VERSION ""

NS_ :

BS_:

BU_: AGSM BCM BSM CADM DMSM DTCM ECM EVCU2 GNMM HCP IPC RFHM SGW TCM
BO_ 1440 TELEMATIC_FD_13: 32 SGW
 SG_ AUD_LVL : 103|8@0+ (1,0) [0|38] "levels" EVCU2
 SG_ ETM_HUD_Zone1_Expanded : 7|6@0+ (1,0) [0|62] "-" IPC
 SG_ ETM_HUD_Zone2_Expanded : 15|6@0+ (1,0) [0|62] "-" IPC
 SG_ ETM_HUD_Zone3_Expanded : 23|6@0+ (1,0) [0|62] "-" IPC
 SG_ ETM_HUD_Zone4_Expanded : 31|6@0+ (1,0) [0|62] "-" IPC
 SG_ ETM_HUD_Zone5_Expanded : 39|6@0+ (1,0) [0|62] "-" IPC
 SG_ HU_Worksite_Inverter_RadioSwitch : 0|1@0+ (1,0) [0|1] "" BCM

BO_ 1465 TELEMATIC_FD_14: 32 SGW
 SG_ ClusterAudiomode : 127|7@0+ (1,0) [0|126] "-" IPC
 SG_ ETM_HUD_Zone1 : 156|3@0+ (1,0) [0|6] "-" IPC
 SG_ ETM_HUD_Zone2 : 167|3@0+ (1,0) [0|6] "-" IPC
 SG_ ETM_HUD_Zone3 : 164|3@0+ (1,0) [0|6] "-" IPC
 SG_ ETM_HUD_Zone4 : 175|3@0+ (1,0) [0|6] "-" IPC
 SG_ ETM_HUD_Zone5 : 172|3@0+ (1,0) [0|6] "-" IPC
 SG_ PSI_Gr1_RPM_SET : 7|5@0+ (250,500) [2000|8000] "rpm" ECM
 SG_ PSI_Gr2_RPM_SET : 15|5@0+ (250,500) [2000|8000] "rpm" ECM
 SG_ PSI_Gr3_RPM_SET : 23|5@0+ (250,500) [2000|8000] "rpm" ECM
 SG_ PSI_Gr4_RPM_SET : 31|5@0+ (250,500) [2000|8000] "rpm" ECM
 SG_ PSI_Gr5_RPM_SET : 39|5@0+ (250,500) [2000|8000] "rpm" ECM
 SG_ PSI_RPM_Reset : 45|1@0+ (1,0) [0|1] "-" ECM
 SG_ PSI_Rq : 47|2@0+ (1,0) [0|3] "-" ECM
 SG_ RACE_CLDWN_ON_OFF_REQ : 2|1@0+ (1,0) [0|0] "-" ECM
 SG_ Radio_Delete_Request : 183|3@0+ (1,0) [0|6] "" IPC
 SG_ Radio_Profile_Request : 82|3@0+ (1,0) [0|6] "-" IPC
 SG_ TGW_CAMERA_DISP_STAT : 91|4@0+ (1,0) [0|14] "-" BCM

BO_ 1466 TELEMATIC_FD_15: 32 SGW
 SG_ Center_Cluster_Button_function : 23|5@0+ (1,0) [0|30] "-" IPC
 SG_ ChargeNow : 89|1@0+ (1,0) [0|1] "-" EVCU2
 SG_ ETM_HUD_CustomSetting : 4|2@0+ (1,0) [0|3] "-" IPC
 SG_ ETM_HUD_Layout : 7|3@0+ (1,0) [0|6] "-" IPC
 SG_ GPS_Elevation : 151|16@0+ (1,-2000) [0|37000] "Hours" IPC
 SG_ HUtoIPC_NAV_Sts : 2|3@0+ (1,0) [0|6] "-" IPC
 SG_ Left_Cluster_Button_function : 15|5@0+ (1,0) [0|30] "-" IPC
 SG_ Right_Cluster_Button_function : 31|5@0+ (1,0) [0|30] "-" IPC

BO_ 150 TELEMATIC_FD_17: 64 SGW
 SG_ FirstFrame_NavTbT : 0|1@0+ (1,0) [0|1] "" IPC
 SG_ NumMultiMessage_NavTbT : 7|3@0+ (1,0) [0|7] "" IPC
 SG_ Text_Characters_NavTbT : 23|416@0+ (1,0) [0|0] "" IPC
 SG_ Text_Type_NavTbT : 4|4@0+ (1,0) [0|14] "" IPC

BO_ 154 TELEMATIC_FD_18: 64 SGW
 SG_ Text_Characters_Aud_Ph : 23|416@0+ (1,0) [0|0] "" IPC
 SG_ Text_Type_Aud_Ph : 7|8@0+ (1,0) [0|254] "" IPC

BO_ 145 TELEMATIC_FD_19: 64 SGW
 SG_ CRC_TELEMATIC_FD_19 : 447|8@0+ (1,0) [0|255] "" EVCU2
 SG_ MessageCounter_TELEMATIC_FD_19 : 435|4@0+ (1,0) [0|15] "" EVCU2
 SG_ PlugAndChargeReq : 385|1@0+ (1,0) [0|1] "" EVCU2
 SG_ Secure_Idle_Req : 0|1@0+ (1,0) [0|1] "" EVCU2,TCM
 SG_ SignatureLightingEnable_Req : 395|1@0+ (1,0) [0|1] "" IPC

BO_ 1428 TELEMATIC_FD_5: 32 SGW
 SG_ CM_TCH_STAT : 74|3@0+ (1,0) [0|6] "" BCM
 SG_ CM_TCH_X_COORD : 143|16@0+ (1,0) [0|65535] "" BCM
 SG_ CM_TCH_Y_COORD : 159|16@0+ (1,0) [0|65535] "" BCM
 SG_ DIST_TO_TURN : 63|16@0+ (1,0) [0|65534] "" CADM,IPC
 SG_ ESC_Sft_btn_status : 79|3@0+ (1,0) [0|6] "" BCM
 SG_ HU_CMP : 174|4@0+ (1,0) [0|0] "" BCM
 SG_ NAV_ARROW : 55|8@0+ (1,0) [1|255] "Arrow" CADM,IPC
 SG_ NAV_UNITS : 42|3@0+ (1,0) [0|7] "" IPC
 SG_ NAVPrsnt : 43|1@0+ (1,0) [0|1] "" IPC
 SG_ T_BY_T_ON : 32|1@0+ (1,0) [0|1] "" CADM,IPC
 SG_ TURN_COMP : 33|1@0+ (1,0) [0|1] "" CADM,IPC
 SG_ WorksiteINVM_Audible_LFW_Req : 76|1@0+ (1,0) [0|1] "" IPC
 SG_ WorksiteINVM_Visual_LFW_Req : 169|1@0+ (1,0) [0|1] "" IPC

BO_ 956 TELEMATIC_FD_8: 32 SGW
 SG_ Power_Tailgate_Enable_Req : 7|1@0+ (1,0) [0|1] "" IPC
 SG_ Rear_Guidance_Light_Status_Req : 0|1@0+ (1,0) [0|1] "" IPC
 SG_ Rear_Lights_with_Approach_Req : 4|1@0+ (1,0) [0|1] "" IPC

BO_ 1832 TELEMATIC_FD_9: 32 SGW
 SG_ GPS_Lat : 87|32@0+ (0.3017485143,-324000000) [-324000000|324000000] "mas" CADM,IPC
 SG_ GPS_Long : 119|32@0+ (0.3017485143,-648000000) [-648000000|648000000] "mas" CADM,IPC

BO_ 158 TELEMATIC_VEHICLE_SETUP: 48 SGW
 SG_ Act_Lane_Mgt_Req : 4|2@0+ (1,0) [0|2] "-" IPC
 SG_ Act_Lane_Mgt_Strength_Req : 1|2@0+ (1,0) [0|2] "-" IPC
 SG_ Active_Park_Mode_Req : 252|1@0+ (1,0) [0|1] "" IPC
 SG_ Active_Park_Prox_Chime_Req : 251|1@0+ (1,0) [0|1] "" IPC
 SG_ Auto_Fold_Mirr_Req : 255|1@0+ (1,0) [0|1] "-" IPC
 SG_ Auto_Trailer_Light_Check_Req : 286|1@0+ (1,0) [0|1] "-" IPC
 SG_ AutoHighBeamEnable_Req : 92|1@0+ (1,0) [0|1] "-" IPC
 SG_ AutoParkBrake_Req : 103|1@0+ (1,0) [0|1] "" IPC
 SG_ AutoUnlockDoorExit_Req : 162|1@0+ (1,0) [0|1] "-" IPC
 SG_ Backup_Cam_Delay_Req : 173|1@0+ (1,0) [0|1] "-" IPC
 SG_ BSDEnable_Req : 140|2@0+ (1,0) [0|2] "-" IPC
 SG_ Consum_Unit_Req : 238|3@0+ (1,0) [0|7] "" IPC
 SG_ CorneringEnable_Req : 82|1@0+ (1,0) [0|1] "-" IPC
 SG_ CRC_TVS1 : 319|8@0+ (1,0) [0|255] "-" CADM
 SG_ Dist_Unit_Req : 231|1@0+ (1,0) [0|1] "" IPC
 SG_ DRLEnable_Req : 80|1@0+ (1,0) [0|1] "-" IPC
 SG_ Drowsy_Driver_Alert_Req : 5|1@0+ (1,0) [0|1] "-" CADM,IPC
 SG_ DynamicGrid_Req : 100|1@0+ (1,0) [0|1] "" IPC
 SG_ Easy_Exit_D_Req : 174|1@0+ (1,0) [0|1] "-" IPC
 SG_ Eng_Off_Pwr_Delay_Req : 187|2@0+ (1,0) [0|3] "-" IPC
 SG_ EPB_MaintenanceMode_Req : 155|1@0+ (1,0) [0|1] "-" BSM
 SG_ FlashLightWLock_Req : 159|1@0+ (1,0) [0|1] "-" IPC
 SG_ FOA_Alert_Type_Req : 283|2@0+ (1,0) [0|3] "" IPC
 SG_ FSFCWPlusActivationMode_Req : 149|2@0+ (1,0) [0|3] "-" CADM,IPC
 SG_ FSFCWPlusSetting_Req : 143|3@0+ (1,0) [0|7] "-" CADM,IPC
 SG_ Fwrd_Cam_Guidelines_Req : 189|1@0+ (1,0) [0|1] "-" IPC
 SG_ GreetingLightsEnable_Req : 81|1@0+ (1,0) [0|1] "-" IPC
 SG_ HeadlightsOffDelay_Req : 145|2@0+ (1,0) [0|3] "-" IPC
 SG_ HeadLightWipers_Req : 167|1@0+ (1,0) [0|1] "-" IPC
 SG_ Hill_Start_Assist_Req : 184|1@0+ (1,0) [0|1] "-" IPC
 SG_ HourMode_Req : 87|1@0+ (1,0) [0|1] "-" IPC
 SG_ HP_Unit_Req : 245|2@0+ (1,0) [0|3] "" IPC
 SG_ Illuminated_Approach_Req : 197|2@0+ (1,0) [0|3] "-" IPC
 SG_ LanguageSelection_Req : 135|8@0+ (1,0) [0|255] "-" IPC
 SG_ LDW_Intensity_Req : 154|2@0+ (1,0) [0|3] "-" IPC
 SG_ LDW_Sensibility_Req : 147|2@0+ (1,0) [0|3] "-" IPC
 SG_ MessageCounter_TVS1 : 307|4@0+ (1,0) [0|15] "-" CADM
 SG_ NavigationRepetition_Req : 105|1@0+ (1,0) [0|1] "" IPC
 SG_ New_Spd_Zone_Ind_Req : 227|2@0+ (1,0) [0|3] "" IPC
 SG_ Paddle_Shifter_Req : 188|1@0+ (1,0) [0|1] "-" IPC
 SG_ PamChimeVolumeFront_Req : 107|2@0+ (1,0) [0|3] "" IPC
 SG_ PamChimeVolumeRear_Req : 111|2@0+ (1,0) [0|3] "" IPC
 SG_ PassiveEntry_Req : 101|1@0+ (1,0) [0|1] "" IPC
 SG_ Ped_EM_Brk_Warn_Act_Req : 175|1@0+ (1,0) [0|1] "-" CADM,IPC
 SG_ PhoneRepetition_Req : 114|1@0+ (1,0) [0|1] "" IPC
 SG_ PLGAlert_Req : 168|1@0+ (1,0) [0|1] "-" IPC
 SG_ Power_Side_Step_Req : 2|1@0+ (1,0) [0|1] "-" IPC
 SG_ Proximity_WU_Req : 6|1@0+ (1,0) [0|1] "-" IPC
 SG_ PwrLevReq : 10|3@0+ (1,0) [0|7] "" IPC
 SG_ RainSensorLevel_Req : 93|1@0+ (1,0) [0|1] "-" IPC
 SG_ Rdy_To_Drive_Req : 223|1@0+ (1,0) [0|1] "" IPC
 SG_ Rear_Brk_Asst_Req : 190|1@0+ (1,0) [0|1] "" IPC
 SG_ RemoteDoorUnlock_Req : 102|1@0+ (1,0) [0|1] "" IPC
 SG_ RemStNrmlStEnbl_Req : 178|2@0+ (1,0) [0|3] "-" IPC
 SG_ RKEMemoryLinkEnable_Req : 166|1@0+ (1,0) [0|1] "-" IPC
 SG_ SOC_Max_Lev_Req : 294|1@0+ (1,0) [0|1] "" IPC
 SG_ SoundHornLock_Req : 127|2@0+ (1,0) [0|3] "" IPC
 SG_ SoundHornRemoteStart_Req : 104|1@0+ (1,0) [0|1] "" IPC
 SG_ Speed_Unit_Req : 253|1@0+ (1,0) [0|1] "" IPC
 SG_ SpeedLockDoorEnable_Req : 94|1@0+ (1,0) [0|1] "-" IPC
 SG_ StaticGrid_Req : 99|1@0+ (1,0) [0|1] "" IPC
 SG_ Susp_Auto_Ent_Ext_Req : 195|1@0+ (1,0) [0|1] "" IPC
 SG_ Susp_Disp_Message_Req : 207|1@0+ (1,0) [0|1] "" IPC
 SG_ Susp_Flsh_Lght_Low_Req : 198|1@0+ (1,0) [0|1] "" IPC
 SG_ Susp_Sound_Hrn_Low_Req : 199|1@0+ (1,0) [0|1] "" IPC
 SG_ Susp_Tire_Jack_Req : 200|1@0+ (1,0) [0|1] "" IPC
 SG_ SVC_Delay_Req : 192|1@0+ (1,0) [0|1] "" IPC
 SG_ SVC_Guidelines_Req : 193|1@0+ (1,0) [0|1] "" IPC
 SG_ Temp_Unit_Req : 239|1@0+ (1,0) [0|1] "" IPC
 SG_ Tilt_Mirr_Rev_Req : 210|1@0+ (1,0) [0|1] "" IPC
 SG_ Tire_Fill_Alert_Req : 215|1@0+ (1,0) [0|1] "" IPC
 SG_ Torque_Unit_Req : 254|1@0+ (1,0) [0|1] "" IPC
 SG_ Traffic_Sign_Info_Req : 230|1@0+ (1,0) [0|1] "" IPC
 SG_ Traffic_Sign_Warn_Req : 206|3@0+ (1,0) [0|3] "" IPC
 SG_ Trail_Brk_Type_Req : 217|2@0+ (1,0) [0|3] "" IPC
 SG_ Trail_Name_Req : 235|4@0+ (1,0) [0|16] "" IPC
 SG_ Trail_Num_Req : 214|2@0+ (1,0) [0|3] "" IPC
 SG_ Trailer_detection_blind_spot_Req : 287|1@0+ (1,0) [0|1] "-" IPC
 SG_ Trailer_Light_Check_Request : 285|2@0+ (1,0) [0|3] "" BCM
 SG_ TyrePress_Unit_Req : 243|2@0+ (1,0) [0|3] "" IPC

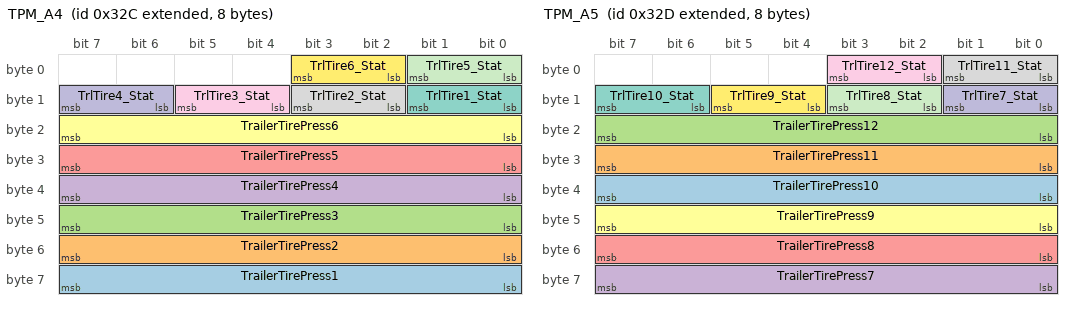
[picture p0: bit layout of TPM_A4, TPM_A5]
BO_ 2147484460 TPM_A4: 8 BCM
 SG_ TrailerTirePress1 : 63|8@0+ (1,0) [0|254] "psi" SGW
 SG_ TrailerTirePress2 : 55|8@0+ (1,0) [0|254] "psi" SGW
 SG_ TrailerTirePress3 : 47|8@0+ (1,0) [0|254] "psi" SGW
 SG_ TrailerTirePress4 : 39|8@0+ (1,0) [0|254] "psi" SGW
 SG_ TrailerTirePress5 : 31|8@0+ (1,0) [0|254] "psi" SGW
 SG_ TrailerTirePress6 : 23|8@0+ (1,0) [0|254] "psi" SGW
 SG_ TrlTire1_Stat : 9|2@0+ (1,0) [0|0] "" SGW
 SG_ TrlTire2_Stat : 11|2@0+ (1,0) [0|0] "" SGW
 SG_ TrlTire3_Stat : 13|2@0+ (1,0) [0|0] "" SGW
 SG_ TrlTire4_Stat : 15|2@0+ (1,0) [0|0] "" SGW
 SG_ TrlTire5_Stat : 1|2@0+ (1,0) [0|0] "" SGW
 SG_ TrlTire6_Stat : 3|2@0+ (1,0) [0|0] "" SGW

BO_ 2147484461 TPM_A5: 8 BCM
 SG_ TrailerTirePress10 : 39|8@0+ (1,0) [0|254] "psi" SGW
 SG_ TrailerTirePress11 : 31|8@0+ (1,0) [0|254] "psi" SGW
 SG_ TrailerTirePress12 : 23|8@0+ (1,0) [0|254] "psi" SGW
 SG_ TrailerTirePress7 : 63|8@0+ (1,0) [0|254] "psi" SGW
 SG_ TrailerTirePress8 : 55|8@0+ (1,0) [0|254] "psi" SGW
 SG_ TrailerTirePress9 : 47|8@0+ (1,0) [0|254] "psi" SGW
 SG_ TrlTire10_Stat : 15|2@0+ (1,0) [0|0] "" SGW
 SG_ TrlTire11_Stat : 1|2@0+ (1,0) [0|0] "" SGW
 SG_ TrlTire12_Stat : 3|2@0+ (1,0) [0|0] "" SGW
 SG_ TrlTire7_Stat : 9|2@0+ (1,0) [0|0] "" SGW
 SG_ TrlTire8_Stat : 11|2@0+ (1,0) [0|0] "" SGW
 SG_ TrlTire9_Stat : 13|2@0+ (1,0) [0|0] "" SGW

CM_ SG_ 1440 AUD_LVL "Audio level";
CM_ SG_ 1440 ETM_HUD_Zone1_Expanded "Configurable HUD zone area 1";
CM_ SG_ 1440 ETM_HUD_Zone2_Expanded "Configurable HUD zone area 2";
CM_ SG_ 1440 ETM_HUD_Zone3_Expanded "Configurable HUD zone area 3";
CM_ SG_ 1440 ETM_HUD_Zone4_Expanded "Configurable HUD zone area 4";
CM_ SG_ 1440 ETM_HUD_Zone5_Expanded "Configurable HUD zone area 5";
CM_ SG_ 1440 HU_Worksite_Inverter_RadioSwitch "Inverter Soft Button switch; [1] = ON";
CM_ SG_ 1465 ClusterAudiomode "TGW audio mode for Cabin/Driver";
CM_ SG_ 1465 ETM_HUD_Zone1 "ETM to Cluster HUD Zone 1";
CM_ SG_ 1465 ETM_HUD_Zone2 "ETM to Cluster HUD Zone 2";
CM_ SG_ 1465 ETM_HUD_Zone3 "ETM to Cluster HUD Zone 3";
CM_ SG_ 1465 ETM_HUD_Zone4 "ETM to Cluster HUD Zone 4";
CM_ SG_ 1465 ETM_HUD_Zone5 "ETM to Cluster HUD Zone 5";
CM_ SG_ 1465 PSI_Gr1_RPM_SET "Requested rpm set point for Performance Shift Indication; 500 indicates not set";
CM_ SG_ 1465 PSI_Gr2_RPM_SET "Requested rpm set point for Performance Shift Indication; 500 indicates not set";
CM_ SG_ 1465 PSI_Gr3_RPM_SET "Requested rpm set point for Performance Shift Indication; 500 indicates not set";
CM_ SG_ 1465 PSI_Gr4_RPM_SET "Requested rpm set point for Performance Shift Indication; 500 indicates not set";
CM_ SG_ 1465 PSI_Gr5_RPM_SET "Requested rpm set point for Performance Shift Indication; 500 indicates not set";
CM_ SG_ 1465 PSI_RPM_Reset "Reset performance shift indication RPM set points to default ;  Reset = [1]";
CM_ SG_ 1465 PSI_Rq "Performance shift indication request";
CM_ SG_ 1465 RACE_CLDWN_ON_OFF_REQ "Activate Quick Cooldown for ADR; Pressed = [1]";
CM_ SG_ 1465 Radio_Delete_Request "Updates based on user which profile is deleted";
CM_ SG_ 1465 Radio_Profile_Request "Changes the profile based on selection";
CM_ SG_ 1465 TGW_CAMERA_DISP_STAT "None";
CM_ SG_ 1466 Center_Cluster_Button_function "Value / text to be shown in Center steering wheel button on cluster";
CM_ SG_ 1466 ChargeNow "Charge Now Signal";
CM_ SG_ 1466 ETM_HUD_CustomSetting "HUD Setting Selection by User";
CM_ SG_ 1466 ETM_HUD_Layout "HUD Layout selection";
CM_ SG_ 1466 GPS_Elevation "Vehicle's altitude";
CM_ SG_ 1466 HUtoIPC_NAV_Sts "HU to IPC NAV Sts";
CM_ SG_ 1466 Left_Cluster_Button_function "Value / text to be shown in left steering wheel button on cluster";
CM_ SG_ 1466 Right_Cluster_Button_function "Value / text to be shown in Right steering wheel button on cluster";
CM_ SG_ 145 CRC_TELEMATIC_FD_19 "CRC according to SAE J1850 standard at each frame transmission.";
CM_ SG_ 145 MessageCounter_TELEMATIC_FD_19 "This signal is a counter used for safety checks strategies. This counter is incremented of 1 (one) unit at each frame transmission.";
CM_ SG_ 145 PlugAndChargeReq "HU Activation Request for for Plug & Change";
CM_ SG_ 145 Secure_Idle_Req "Secure Idle Request";
CM_ SG_ 145 SignatureLightingEnable_Req "Signature Lighting Enable/Disable";
CM_ SG_ 1428 CM_TCH_STAT "Touch Screen Status";
CM_ SG_ 1428 CM_TCH_X_COORD "Value for the touch screen X axis coordinates";
CM_ SG_ 1428 CM_TCH_Y_COORD "Value for the touch screen Y axis coordinates";
CM_ SG_ 1428 DIST_TO_TURN "Numeric distance to next turn";
CM_ SG_ 1428 ESC_Sft_btn_status "ESC mode personalization request";
CM_ SG_ 1428 HU_CMP "Radio compass direction";
CM_ SG_ 1428 NAV_ARROW "Navigation arrow type";
CM_ SG_ 1428 NAV_UNITS "Unit of measure";
CM_ SG_ 1428 NAVPrsnt "A navigation system module is present";
CM_ SG_ 1428 T_BY_T_ON "Turn by turn on";
CM_ SG_ 1428 TURN_COMP "Turn complete";
CM_ SG_ 1428 WorksiteINVM_Audible_LFW_Req "Worksite Inverter Low Fuel Warning audible setting; ON = [1]";
CM_ SG_ 1428 WorksiteINVM_Visual_LFW_Req "Worksite Inverter Low Fuel Warning visual setting; ON = [1]";
CM_ SG_ 956 Power_Tailgate_Enable_Req "Tailgate enable status; enabled = [1]";
CM_ SG_ 956 Rear_Guidance_Light_Status_Req "Rear Guidance Light Status Setting; ON = [1]";
CM_ SG_ 956 Rear_Lights_with_Approach_Req "Rear Guidance Lighting with approach setting; On with Approach = [1]";
CM_ SG_ 1832 GPS_Lat "GPS Latitude (- means south)";
CM_ SG_ 1832 GPS_Long "GPS Longitude (- means west)";
CM_ SG_ 158 Act_Lane_Mgt_Req "Act Lane Mgt setting request";
CM_ SG_ 158 Act_Lane_Mgt_Strength_Req "Act Lane Mgt Strength setting request";
CM_ SG_ 158 Active_Park_Mode_Req "Active Parksense Mode setting request";
CM_ SG_ 158 Active_Park_Prox_Chime_Req "Active Parksense Proximity Chime setting request";
CM_ SG_ 158 Auto_Fold_Mirr_Req "Auto Folding Mirror setting request";
CM_ SG_ 158 Auto_Trailer_Light_Check_Req "Automatic trailer light sequence activation on connect";
CM_ SG_ 158 AutoHighBeamEnable_Req "This signal is managed when the driver requests a setting of  the Auto High Beam feature";
CM_ SG_ 158 AutoParkBrake_Req "This signal is managed when the driver requests a setting of the Auto Park Brake";
CM_ SG_ 158 AutoUnlockDoorExit_Req "This signal is managed when the driver request a setting of  Auto Unlock Door On Exit";
CM_ SG_ 158 Backup_Cam_Delay_Req "Backup Camera Delay setting request";
CM_ SG_ 158 BSDEnable_Req "This signal is managed when the driver requests a setting of Blind Spot Alert";
CM_ SG_ 158 Consum_Unit_Req "Consumption Unit setting request";
CM_ SG_ 158 CorneringEnable_Req "This signal is managed when the driver requests a setting of Cornering Lights";
CM_ SG_ 158 CRC_TVS1 "CRC according to SAE J1850 standard at each frame transmission.";
CM_ SG_ 158 Dist_Unit_Req "Distance Unit setting request";
CM_ SG_ 158 DRLEnable_Req "This signal is managed when the driver requests a setting of the DRL feature";
CM_ SG_ 158 Drowsy_Driver_Alert_Req "Drowsy Driver Alert setting request";
CM_ SG_ 158 DynamicGrid_Req "Rear View Camera Dynamic Gridlines request";
CM_ SG_ 158 Easy_Exit_D_Req "Driver Easy Exit Seat setting request";
CM_ SG_ 158 Eng_Off_Pwr_Delay_Req "Engine Off Power Delay setting request";
CM_ SG_ 158 EPB_MaintenanceMode_Req "This signal is managed when the driver request a setting of  Maintenance Mode";
CM_ SG_ 158 FlashLightWLock_Req "This signal is managed when the driver request a setting of  Flash Light With Lock";
CM_ SG_ 158 FOA_Alert_Type_Req "Forgotten Object Alert Type";
CM_ SG_ 158 FSFCWPlusActivationMode_Req "This signal is managed when the driver request a  setting of FSFCW";
CM_ SG_ 158 FSFCWPlusSetting_Req "This signal is managed when the driver request a  setting of FSFCW";
CM_ SG_ 158 Fwrd_Cam_Guidelines_Req "Forward Facing Camera Guidelines setting request";
CM_ SG_ 158 GreetingLightsEnable_Req "This signal is managed when the button of block or unblocking of the door is pressed.";
CM_ SG_ 158 HeadlightsOffDelay_Req "This signal is managed when the driver requests a setting of the Headligts Off Delay";
CM_ SG_ 158 HeadLightWipers_Req "Setting to turn on/off headlights with wipers";
CM_ SG_ 158 Hill_Start_Assist_Req "Hill Start Assist setting request";
CM_ SG_ 158 HourMode_Req "This signal is managed when the driver requests a setting of Hour Mode";
CM_ SG_ 158 HP_Unit_Req "Horsepower Unit setting request";
CM_ SG_ 158 Illuminated_Approach_Req "Illuminated Approach setting request";
CM_ SG_ 158 LanguageSelection_Req "This signal is managed when the driver requests a setting of Language";
CM_ SG_ 158 LDW_Intensity_Req "This signal is managed when the driver requests a setting of the LDW Intensity";
CM_ SG_ 158 LDW_Sensibility_Req "This signal is managed when the driver requests a setting of  the LDW Sensibility";
CM_ SG_ 158 MessageCounter_TVS1 "This signal is a counter used for safety checks strategies. This counter is incremented of 1 (one) unit at each frame transmission.";
CM_ SG_ 158 New_Spd_Zone_Ind_Req "New Speed Zone Indication setting request";
CM_ SG_ 158 Paddle_Shifter_Req "Paddle Shifter setting request";
CM_ SG_ 158 PamChimeVolumeFront_Req "This signal is managed when the driver request a  setting of the of Chime Volume  of the PAM";
CM_ SG_ 158 PamChimeVolumeRear_Req "This signal is managed when the driver request a  setting of the of Chime Volume  of the PAM  8  Channels";
CM_ SG_ 158 PassiveEntry_Req "This signal is managed when the driver requests a setting of the Passive Entry";
CM_ SG_ 158 Ped_EM_Brk_Warn_Act_Req "Pedestrian Emergency Braking Warning & Active Braking setting request";
CM_ SG_ 158 PLGAlert_Req "Setting to turn on/off the power liftgate chime";
CM_ SG_ 158 Power_Side_Step_Req "Power side step setting request";
CM_ SG_ 158 Proximity_WU_Req "Proximity Wakeup setting request";
CM_ SG_ 158 PwrLevReq "This signal is managed when the driver requests the Power Level setting";
CM_ SG_ 158 RainSensorLevel_Req "This signal is managed when the driver requests a setting of Rain Sensor Level";
CM_ SG_ 158 Rdy_To_Drive_Req "Ready to Driver Pop Up setting request";
CM_ SG_ 158 Rear_Brk_Asst_Req "Rear Braking Assist setting request";
CM_ SG_ 158 RemoteDoorUnlock_Req "This signal is managed when the driver requests a setting of the Remote Door Unlock";
CM_ SG_ 158 RemStNrmlStEnbl_Req "Setting to allow seat heating and venting for all starts, remote starts, or none";
CM_ SG_ 158 RKEMemoryLinkEnable_Req "To enable or disable RKE linked to memory";
CM_ SG_ 158 SOC_Max_Lev_Req "Customer top of SOC selection request.";
CM_ SG_ 158 SoundHornLock_Req "This signal is managed when the driver requests a setting of the Sound Horn with Unlock";
CM_ SG_ 158 SoundHornRemoteStart_Req "This signal is managed when the driver requests a setting of the Sound Horn with Remote Start";
CM_ SG_ 158 Speed_Unit_Req "Speed Unit setting request";
CM_ SG_ 158 SpeedLockDoorEnable_Req "This signal is managed when the driver requests a setting of Auto Door Locks";
CM_ SG_ 158 StaticGrid_Req "Rear View Camera Static Gridlines request";
CM_ SG_ 158 Susp_Auto_Ent_Ext_Req "Suspension Auto Entry/Exit setting request";
CM_ SG_ 158 Susp_Disp_Message_Req "Suspension Display Messages setting request";
CM_ SG_ 158 Susp_Flsh_Lght_Low_Req "Suspension Flash Lights with Lower setting request";
CM_ SG_ 158 Susp_Sound_Hrn_Low_Req "Suspension Sound Horn with Lower setting request";
CM_ SG_ 158 Susp_Tire_Jack_Req "Suspension Tire/Jack Mode setting request";
CM_ SG_ 158 SVC_Delay_Req "Surround View Camera Delay setting request";
CM_ SG_ 158 SVC_Guidelines_Req "Surround View Camera Guidelines setting request";
CM_ SG_ 158 Temp_Unit_Req "Temperature Unit setting request";
CM_ SG_ 158 Tilt_Mirr_Rev_Req "Tilt Mirrors in Reverse setting request";
CM_ SG_ 158 Tire_Fill_Alert_Req "Tire Fill Alert setting request";
CM_ SG_ 158 Torque_Unit_Req "Torque Unit setting request";
CM_ SG_ 158 Traffic_Sign_Info_Req "Traffic Sign Information setting request";
CM_ SG_ 158 Traffic_Sign_Warn_Req "Traffic Sign Warning setting request";
CM_ SG_ 158 Trail_Brk_Type_Req "Trailer Brake Type setting request";
CM_ SG_ 158 Trail_Name_Req "Trailer Name setting request";
CM_ SG_ 158 Trail_Num_Req "Trailer Number setting request";
CM_ SG_ 158 Trailer_detection_blind_spot_Req "Trailer_detection_blind_spot_Req";
CM_ SG_ 158 Trailer_Light_Check_Request "Trailer Light Check Request";
CM_ SG_ 158 TyrePress_Unit_Req "Tyre Pressure setting request";
CM_ SG_ 2147484460 TrailerTirePress1 "Trailer Tire Pressure 1";
CM_ SG_ 2147484460 TrailerTirePress2 "Trailer Tire Pressure 2";
CM_ SG_ 2147484460 TrailerTirePress3 "Trailer Tire Pressure 3";
CM_ SG_ 2147484460 TrailerTirePress4 "Trailer Tire Pressure 4";
CM_ SG_ 2147484460 TrailerTirePress5 "Trailer Tire Pressure 5";
CM_ SG_ 2147484460 TrailerTirePress6 "Trailer Tire Pressure 6";
CM_ SG_ 2147484460 TrlTire1_Stat "Trailer Tire 1 Status";
CM_ SG_ 2147484460 TrlTire2_Stat "Trailer Tire 2 Status";
CM_ SG_ 2147484460 TrlTire3_Stat "Trailer Tire 3 Status";
CM_ SG_ 2147484460 TrlTire4_Stat "Trailer Tire 4 Status";
CM_ SG_ 2147484460 TrlTire5_Stat "Trailer Tire 5 Status";
CM_ SG_ 2147484460 TrlTire6_Stat "Trailer Tire 6 Status";
CM_ SG_ 2147484461 TrailerTirePress10 "Trailer Tire Pressure 10";
CM_ SG_ 2147484461 TrailerTirePress11 "Trailer Tire Pressure 11";
CM_ SG_ 2147484461 TrailerTirePress12 "Trailer Tire Pressure 12";
CM_ SG_ 2147484461 TrailerTirePress7 "Trailer Tire Pressure 7";
CM_ SG_ 2147484461 TrailerTirePress8 "Trailer Tire Pressure 8";
CM_ SG_ 2147484461 TrailerTirePress9 "Trailer Tire Pressure 9";
CM_ SG_ 2147484461 TrlTire10_Stat "Trailer Tire 10 Status";
CM_ SG_ 2147484461 TrlTire11_Stat "Trailer Tire 11 Status";
CM_ SG_ 2147484461 TrlTire12_Stat "Trailer Tire 12 Status";
CM_ SG_ 2147484461 TrlTire7_Stat "Trailer Tire 7 Status";
CM_ SG_ 2147484461 TrlTire8_Stat "Trailer Tire 8 Status";
CM_ SG_ 2147484461 TrlTire9_Stat "Trailer Tire 9 Status";

BA_DEF_ SG_ "GenSigStartValue" INT 0 2147483647;
BA_DEF_ SG_ "GenSigInactiveValue" INT 0 2147483647;
BA_DEF_ SG_ "GenSigSendType" ENUM "NotUsed","OnWrite","OnWriteWithRepetition","OnChange","OnChangeWithRepetition","IfActive","IfActiveWithRepetition","NoSigSendType";
BA_DEF_ SG_ "SystemSignalLongSymbol" STRING ;
BA_DEF_ SG_ "GenSigTimeoutTime_AGSM" INT 0 65535;
BA_DEF_ SG_ "GenSigTimeoutTime_BCM" INT 0 65535;
BA_DEF_ SG_ "GenSigTimeoutTime_BSM" INT 0 65535;
BA_DEF_ SG_ "GenSigTimeoutTime_CADM" INT 0 65535;
BA_DEF_ SG_ "GenSigTimeoutTime_DMSM" INT 0 65535;
BA_DEF_ SG_ "GenSigTimeoutTime_DTCM" INT 0 65535;
BA_DEF_ SG_ "GenSigTimeoutTime_ECM" INT 0 65535;
BA_DEF_ SG_ "GenSigTimeoutTime_EVCU2" INT 0 65535;
BA_DEF_ SG_ "GenSigTimeoutTime_GNMM" INT 0 65535;
BA_DEF_ SG_ "GenSigTimeoutTime_HCP" INT 0 65535;
BA_DEF_ SG_ "GenSigTimeoutTime_IPC" INT 0 65535;
BA_DEF_ SG_ "GenSigTimeoutTime_RFHM" INT 0 65535;
BA_DEF_ SG_ "GenSigTimeoutTime_SGW" INT 0 65535;
BA_DEF_ SG_ "GenSigTimeoutTime_TCM" INT 0 65535;
BA_DEF_ BO_ "DiagRequest" ENUM "No","Yes";
BA_DEF_ BO_ "Type" ENUM "P","C","PE","COC","PE_Cntrl","E","E_Cntrl","OC","S","BAF","DC","EM","MM","ISO-TP","-";
BA_DEF_ BO_ "DiagResponse" ENUM "No","Yes";
BA_DEF_ BO_ "NmMessage" ENUM "No","Yes";
BA_DEF_ BO_ "GenMsgSendType" ENUM "Cyclic","NotUsed","NotUsed","NotUsed","NotUsed","NotUsed","NotUsed","NotUsed","NoMsgSendType";
BA_DEF_ BO_ "GenMsgNrOfRepetition" INT 0 255;
BA_DEF_ BO_ "GenMsgILSupport" ENUM "No","Yes";
BA_DEF_ BO_ "GenMsgStartDelayTime" INT 0 65535;
BA_DEF_ BO_ "GenMsgCycleTimeFast" INT 0 65535;
BA_DEF_ BO_ "GenMsgCycleTime" INT 0 65535;
BA_DEF_ BO_ "GenMsgDelayTime" INT 0 65535;
BA_DEF_ BO_ "NmAsrMessage" ENUM "No","Yes";
BA_DEF_ BO_ "DiagState" ENUM "No","Yes";
BA_DEF_ BO_ "DiagConnection" HEX 0 65535;
BA_DEF_ BO_ "VFrameFormat" ENUM "StandardCAN","ExtendedCAN","reserved","reserved","reserved","reserved","reserved","reserved","reserved","reserved","reserved","reserved","reserved","reserved","StandardCAN_FD","ExtendedCAN_FD";
BA_DEF_ BO_ "CANFD_BRS" ENUM "0","1";
BA_DEF_DEF_ "DiagRequest" "No";
BA_DEF_DEF_ "Type" "-";
BA_DEF_DEF_ "DiagResponse" "No";
BA_DEF_DEF_ "NmMessage" "No";
BA_DEF_DEF_ "GenMsgSendType" "NoMsgSendType";
BA_DEF_DEF_ "GenMsgNrOfRepetition" 0;
BA_DEF_DEF_ "GenMsgILSupport" "No";
BA_DEF_DEF_ "GenMsgStartDelayTime" 0;
BA_DEF_DEF_ "GenMsgCycleTimeFast" 0;
BA_DEF_DEF_ "GenMsgCycleTime" 0;
BA_DEF_DEF_ "GenMsgDelayTime" 0;
BA_DEF_DEF_ "NmAsrMessage" "No";
BA_DEF_DEF_ "DiagState" "No";
BA_DEF_DEF_ "DiagConnection" 0;
BA_DEF_DEF_ "VFrameFormat" "StandardCAN_FD";
BA_DEF_DEF_ "CANFD_BRS" "0";
BA_DEF_DEF_ "GenSigStartValue" 0;
BA_DEF_DEF_ "GenSigInactiveValue" 0;
BA_DEF_DEF_ "GenSigSendType" "NoSigSendType";
BA_DEF_DEF_ "SystemSignalLongSymbol" "";
BA_DEF_DEF_ "GenSigTimeoutTime_AGSM" 2500;
BA_DEF_DEF_ "GenSigTimeoutTime_BCM" 2500;
BA_DEF_DEF_ "GenSigTimeoutTime_BSM" 2500;
BA_DEF_DEF_ "GenSigTimeoutTime_CADM" 2500;
BA_DEF_DEF_ "GenSigTimeoutTime_DMSM" 2500;
BA_DEF_DEF_ "GenSigTimeoutTime_DTCM" 2500;
BA_DEF_DEF_ "GenSigTimeoutTime_ECM" 2500;
BA_DEF_DEF_ "GenSigTimeoutTime_EVCU2" 2500;
BA_DEF_DEF_ "GenSigTimeoutTime_GNMM" 2500;
BA_DEF_DEF_ "GenSigTimeoutTime_HCP" 2500;
BA_DEF_DEF_ "GenSigTimeoutTime_IPC" 2500;
BA_DEF_DEF_ "GenSigTimeoutTime_RFHM" 2500;
BA_DEF_DEF_ "GenSigTimeoutTime_SGW" 2500;
BA_DEF_DEF_ "GenSigTimeoutTime_TCM" 2500;
BA_ "Type" BO_ 1440 3;
BA_ "GenMsgSendType" BO_ 1440 0;
BA_ "GenMsgNrOfRepetition" BO_ 1440 2;
BA_ "GenMsgILSupport" BO_ 1440 1;
BA_ "GenMsgCycleTimeFast" BO_ 1440 20;
BA_ "GenMsgCycleTime" BO_ 1440 1000;
BA_ "GenMsgDelayTime" BO_ 1440 20;
BA_ "CANFD_BRS" BO_ 1440 1;
BA_ "Type" BO_ 1465 3;
BA_ "GenMsgSendType" BO_ 1465 0;
BA_ "GenMsgNrOfRepetition" BO_ 1465 2;
BA_ "GenMsgILSupport" BO_ 1465 1;
BA_ "GenMsgCycleTimeFast" BO_ 1465 20;
BA_ "GenMsgCycleTime" BO_ 1465 1000;
BA_ "GenMsgDelayTime" BO_ 1465 20;
BA_ "CANFD_BRS" BO_ 1465 1;
BA_ "Type" BO_ 1466 3;
BA_ "GenMsgSendType" BO_ 1466 0;
BA_ "GenMsgNrOfRepetition" BO_ 1466 2;
BA_ "GenMsgILSupport" BO_ 1466 1;
BA_ "GenMsgCycleTimeFast" BO_ 1466 20;
BA_ "GenMsgCycleTime" BO_ 1466 1000;
BA_ "GenMsgDelayTime" BO_ 1466 20;
BA_ "CANFD_BRS" BO_ 1466 1;
BA_ "Type" BO_ 150 7;
BA_ "GenMsgILSupport" BO_ 150 1;
BA_ "CANFD_BRS" BO_ 150 1;
BA_ "Type" BO_ 154 7;
BA_ "GenMsgILSupport" BO_ 154 1;
BA_ "CANFD_BRS" BO_ 154 1;
BA_ "Type" BO_ 145 3;
BA_ "GenMsgSendType" BO_ 145 0;
BA_ "GenMsgILSupport" BO_ 145 1;
BA_ "GenMsgCycleTime" BO_ 145 1000;
BA_ "CANFD_BRS" BO_ 145 1;
BA_ "Type" BO_ 1428 3;
BA_ "GenMsgSendType" BO_ 1428 0;
BA_ "GenMsgNrOfRepetition" BO_ 1428 2;
BA_ "GenMsgILSupport" BO_ 1428 1;
BA_ "GenMsgCycleTimeFast" BO_ 1428 20;
BA_ "GenMsgCycleTime" BO_ 1428 1000;
BA_ "GenMsgDelayTime" BO_ 1428 20;
BA_ "CANFD_BRS" BO_ 1428 1;
BA_ "Type" BO_ 956 7;
BA_ "GenMsgILSupport" BO_ 956 1;
BA_ "CANFD_BRS" BO_ 956 1;
BA_ "Type" BO_ 1832 1;
BA_ "GenMsgSendType" BO_ 1832 0;
BA_ "GenMsgILSupport" BO_ 1832 1;
BA_ "GenMsgCycleTime" BO_ 1832 1000;
BA_ "CANFD_BRS" BO_ 1832 1;
BA_ "Type" BO_ 158 8;
BA_ "GenMsgILSupport" BO_ 158 1;
BA_ "CANFD_BRS" BO_ 158 1;
BA_ "Type" BO_ 2147484460 1;
BA_ "GenMsgSendType" BO_ 2147484460 0;
BA_ "GenMsgNrOfRepetition" BO_ 2147484460 2;
BA_ "GenMsgILSupport" BO_ 2147484460 1;
BA_ "GenMsgCycleTime" BO_ 2147484460 1000;
BA_ "GenMsgDelayTime" BO_ 2147484460 20;
BA_ "VFrameFormat" BO_ 2147484460 15;
BA_ "CANFD_BRS" BO_ 2147484460 1;
BA_ "Type" BO_ 2147484461 1;
BA_ "GenMsgSendType" BO_ 2147484461 0;
BA_ "GenMsgNrOfRepetition" BO_ 2147484461 2;
BA_ "GenMsgILSupport" BO_ 2147484461 1;
BA_ "GenMsgCycleTime" BO_ 2147484461 1000;
BA_ "GenMsgDelayTime" BO_ 2147484461 20;
BA_ "VFrameFormat" BO_ 2147484461 15;
BA_ "CANFD_BRS" BO_ 2147484461 1;
BA_ "GenSigSendType" SG_ 1440 AUD_LVL 3;
BA_ "GenSigTimeoutTime_AGSM" SG_ 1440 AUD_LVL 0;
BA_ "GenSigTimeoutTime_BCM" SG_ 1440 AUD_LVL 0;
BA_ "GenSigTimeoutTime_BSM" SG_ 1440 AUD_LVL 0;
BA_ "GenSigTimeoutTime_CADM" SG_ 1440 AUD_LVL 0;
BA_ "GenSigTimeoutTime_DMSM" SG_ 1440 AUD_LVL 0;
BA_ "GenSigTimeoutTime_DTCM" SG_ 1440 AUD_LVL 0;
BA_ "GenSigTimeoutTime_ECM" SG_ 1440 AUD_LVL 0;
BA_ "GenSigTimeoutTime_GNMM" SG_ 1440 AUD_LVL 0;
BA_ "GenSigTimeoutTime_HCP" SG_ 1440 AUD_LVL 0;
BA_ "GenSigTimeoutTime_IPC" SG_ 1440 AUD_LVL 0;
BA_ "GenSigTimeoutTime_RFHM" SG_ 1440 AUD_LVL 0;
BA_ "GenSigTimeoutTime_SGW" SG_ 1440 AUD_LVL 0;
BA_ "GenSigTimeoutTime_TCM" SG_ 1440 AUD_LVL 0;
BA_ "GenSigSendType" SG_ 1440 ETM_HUD_Zone1_Expanded 4;
BA_ "GenSigTimeoutTime_AGSM" SG_ 1440 ETM_HUD_Zone1_Expanded 0;
BA_ "GenSigTimeoutTime_BCM" SG_ 1440 ETM_HUD_Zone1_Expanded 0;
BA_ "GenSigTimeoutTime_BSM" SG_ 1440 ETM_HUD_Zone1_Expanded 0;
BA_ "GenSigTimeoutTime_CADM" SG_ 1440 ETM_HUD_Zone1_Expanded 0;
BA_ "GenSigTimeoutTime_DMSM" SG_ 1440 ETM_HUD_Zone1_Expanded 0;
BA_ "GenSigTimeoutTime_DTCM" SG_ 1440 ETM_HUD_Zone1_Expanded 0;
BA_ "GenSigTimeoutTime_ECM" SG_ 1440 ETM_HUD_Zone1_Expanded 0;
BA_ "GenSigTimeoutTime_EVCU2" SG_ 1440 ETM_HUD_Zone1_Expanded 0;
BA_ "GenSigTimeoutTime_GNMM" SG_ 1440 ETM_HUD_Zone1_Expanded 0;
BA_ "GenSigTimeoutTime_HCP" SG_ 1440 ETM_HUD_Zone1_Expanded 0;
BA_ "GenSigTimeoutTime_RFHM" SG_ 1440 ETM_HUD_Zone1_Expanded 0;
BA_ "GenSigTimeoutTime_SGW" SG_ 1440 ETM_HUD_Zone1_Expanded 0;
BA_ "GenSigTimeoutTime_TCM" SG_ 1440 ETM_HUD_Zone1_Expanded 0;
BA_ "GenSigSendType" SG_ 1440 ETM_HUD_Zone2_Expanded 4;
BA_ "GenSigTimeoutTime_AGSM" SG_ 1440 ETM_HUD_Zone2_Expanded 0;
BA_ "GenSigTimeoutTime_BCM" SG_ 1440 ETM_HUD_Zone2_Expanded 0;
BA_ "GenSigTimeoutTime_BSM" SG_ 1440 ETM_HUD_Zone2_Expanded 0;
BA_ "GenSigTimeoutTime_CADM" SG_ 1440 ETM_HUD_Zone2_Expanded 0;
BA_ "GenSigTimeoutTime_DMSM" SG_ 1440 ETM_HUD_Zone2_Expanded 0;
BA_ "GenSigTimeoutTime_DTCM" SG_ 1440 ETM_HUD_Zone2_Expanded 0;
BA_ "GenSigTimeoutTime_ECM" SG_ 1440 ETM_HUD_Zone2_Expanded 0;
BA_ "GenSigTimeoutTime_EVCU2" SG_ 1440 ETM_HUD_Zone2_Expanded 0;
BA_ "GenSigTimeoutTime_GNMM" SG_ 1440 ETM_HUD_Zone2_Expanded 0;
BA_ "GenSigTimeoutTime_HCP" SG_ 1440 ETM_HUD_Zone2_Expanded 0;
BA_ "GenSigTimeoutTime_RFHM" SG_ 1440 ETM_HUD_Zone2_Expanded 0;
BA_ "GenSigTimeoutTime_SGW" SG_ 1440 ETM_HUD_Zone2_Expanded 0;
BA_ "GenSigTimeoutTime_TCM" SG_ 1440 ETM_HUD_Zone2_Expanded 0;
BA_ "GenSigSendType" SG_ 1440 ETM_HUD_Zone3_Expanded 4;
BA_ "GenSigTimeoutTime_AGSM" SG_ 1440 ETM_HUD_Zone3_Expanded 0;
BA_ "GenSigTimeoutTime_BCM" SG_ 1440 ETM_HUD_Zone3_Expanded 0;
BA_ "GenSigTimeoutTime_BSM" SG_ 1440 ETM_HUD_Zone3_Expanded 0;
BA_ "GenSigTimeoutTime_CADM" SG_ 1440 ETM_HUD_Zone3_Expanded 0;
BA_ "GenSigTimeoutTime_DMSM" SG_ 1440 ETM_HUD_Zone3_Expanded 0;
BA_ "GenSigTimeoutTime_DTCM" SG_ 1440 ETM_HUD_Zone3_Expanded 0;
BA_ "GenSigTimeoutTime_ECM" SG_ 1440 ETM_HUD_Zone3_Expanded 0;
BA_ "GenSigTimeoutTime_EVCU2" SG_ 1440 ETM_HUD_Zone3_Expanded 0;
BA_ "GenSigTimeoutTime_GNMM" SG_ 1440 ETM_HUD_Zone3_Expanded 0;
BA_ "GenSigTimeoutTime_HCP" SG_ 1440 ETM_HUD_Zone3_Expanded 0;
BA_ "GenSigTimeoutTime_RFHM" SG_ 1440 ETM_HUD_Zone3_Expanded 0;
BA_ "GenSigTimeoutTime_SGW" SG_ 1440 ETM_HUD_Zone3_Expanded 0;
BA_ "GenSigTimeoutTime_TCM" SG_ 1440 ETM_HUD_Zone3_Expanded 0;
BA_ "GenSigSendType" SG_ 1440 ETM_HUD_Zone4_Expanded 4;
BA_ "GenSigTimeoutTime_AGSM" SG_ 1440 ETM_HUD_Zone4_Expanded 0;
BA_ "GenSigTimeoutTime_BCM" SG_ 1440 ETM_HUD_Zone4_Expanded 0;
BA_ "GenSigTimeoutTime_BSM" SG_ 1440 ETM_HUD_Zone4_Expanded 0;
BA_ "GenSigTimeoutTime_CADM" SG_ 1440 ETM_HUD_Zone4_Expanded 0;
BA_ "GenSigTimeoutTime_DMSM" SG_ 1440 ETM_HUD_Zone4_Expanded 0;
BA_ "GenSigTimeoutTime_DTCM" SG_ 1440 ETM_HUD_Zone4_Expanded 0;
BA_ "GenSigTimeoutTime_ECM" SG_ 1440 ETM_HUD_Zone4_Expanded 0;
BA_ "GenSigTimeoutTime_EVCU2" SG_ 1440 ETM_HUD_Zone4_Expanded 0;
BA_ "GenSigTimeoutTime_GNMM" SG_ 1440 ETM_HUD_Zone4_Expanded 0;
BA_ "GenSigTimeoutTime_HCP" SG_ 1440 ETM_HUD_Zone4_Expanded 0;
BA_ "GenSigTimeoutTime_RFHM" SG_ 1440 ETM_HUD_Zone4_Expanded 0;
BA_ "GenSigTimeoutTime_SGW" SG_ 1440 ETM_HUD_Zone4_Expanded 0;
BA_ "GenSigTimeoutTime_TCM" SG_ 1440 ETM_HUD_Zone4_Expanded 0;
BA_ "GenSigSendType" SG_ 1440 ETM_HUD_Zone5_Expanded 4;
BA_ "GenSigTimeoutTime_AGSM" SG_ 1440 ETM_HUD_Zone5_Expanded 0;
BA_ "GenSigTimeoutTime_BCM" SG_ 1440 ETM_HUD_Zone5_Expanded 0;
BA_ "GenSigTimeoutTime_BSM" SG_ 1440 ETM_HUD_Zone5_Expanded 0;
BA_ "GenSigTimeoutTime_CADM" SG_ 1440 ETM_HUD_Zone5_Expanded 0;
BA_ "GenSigTimeoutTime_DMSM" SG_ 1440 ETM_HUD_Zone5_Expanded 0;
BA_ "GenSigTimeoutTime_DTCM" SG_ 1440 ETM_HUD_Zone5_Expanded 0;
BA_ "GenSigTimeoutTime_ECM" SG_ 1440 ETM_HUD_Zone5_Expanded 0;
BA_ "GenSigTimeoutTime_EVCU2" SG_ 1440 ETM_HUD_Zone5_Expanded 0;
BA_ "GenSigTimeoutTime_GNMM" SG_ 1440 ETM_HUD_Zone5_Expanded 0;
BA_ "GenSigTimeoutTime_HCP" SG_ 1440 ETM_HUD_Zone5_Expanded 0;
BA_ "GenSigTimeoutTime_RFHM" SG_ 1440 ETM_HUD_Zone5_Expanded 0;
BA_ "GenSigTimeoutTime_SGW" SG_ 1440 ETM_HUD_Zone5_Expanded 0;
BA_ "GenSigTimeoutTime_TCM" SG_ 1440 ETM_HUD_Zone5_Expanded 0;
BA_ "GenSigSendType" SG_ 1440 HU_Worksite_Inverter_RadioSwitch 3;
BA_ "GenSigTimeoutTime_AGSM" SG_ 1440 HU_Worksite_Inverter_RadioSwitch 0;
BA_ "GenSigTimeoutTime_BSM" SG_ 1440 HU_Worksite_Inverter_RadioSwitch 0;
BA_ "GenSigTimeoutTime_CADM" SG_ 1440 HU_Worksite_Inverter_RadioSwitch 0;
BA_ "GenSigTimeoutTime_DMSM" SG_ 1440 HU_Worksite_Inverter_RadioSwitch 0;
BA_ "GenSigTimeoutTime_DTCM" SG_ 1440 HU_Worksite_Inverter_RadioSwitch 0;
BA_ "GenSigTimeoutTime_ECM" SG_ 1440 HU_Worksite_Inverter_RadioSwitch 0;
BA_ "GenSigTimeoutTime_EVCU2" SG_ 1440 HU_Worksite_Inverter_RadioSwitch 0;
BA_ "GenSigTimeoutTime_GNMM" SG_ 1440 HU_Worksite_Inverter_RadioSwitch 0;
BA_ "GenSigTimeoutTime_HCP" SG_ 1440 HU_Worksite_Inverter_RadioSwitch 0;
BA_ "GenSigTimeoutTime_IPC" SG_ 1440 HU_Worksite_Inverter_RadioSwitch 0;
BA_ "GenSigTimeoutTime_RFHM" SG_ 1440 HU_Worksite_Inverter_RadioSwitch 0;
BA_ "GenSigTimeoutTime_SGW" SG_ 1440 HU_Worksite_Inverter_RadioSwitch 0;
BA_ "GenSigTimeoutTime_TCM" SG_ 1440 HU_Worksite_Inverter_RadioSwitch 0;
BA_ "GenSigSendType" SG_ 1465 ClusterAudiomode 3;
BA_ "GenSigTimeoutTime_AGSM" SG_ 1465 ClusterAudiomode 0;
BA_ "GenSigTimeoutTime_BCM" SG_ 1465 ClusterAudiomode 0;
BA_ "GenSigTimeoutTime_BSM" SG_ 1465 ClusterAudiomode 0;
BA_ "GenSigTimeoutTime_CADM" SG_ 1465 ClusterAudiomode 0;
BA_ "GenSigTimeoutTime_DMSM" SG_ 1465 ClusterAudiomode 0;
BA_ "GenSigTimeoutTime_DTCM" SG_ 1465 ClusterAudiomode 0;
BA_ "GenSigTimeoutTime_ECM" SG_ 1465 ClusterAudiomode 0;
BA_ "GenSigTimeoutTime_EVCU2" SG_ 1465 ClusterAudiomode 0;
BA_ "GenSigTimeoutTime_GNMM" SG_ 1465 ClusterAudiomode 0;
BA_ "GenSigTimeoutTime_HCP" SG_ 1465 ClusterAudiomode 0;
BA_ "GenSigTimeoutTime_RFHM" SG_ 1465 ClusterAudiomode 0;
BA_ "GenSigTimeoutTime_SGW" SG_ 1465 ClusterAudiomode 0;
BA_ "GenSigTimeoutTime_TCM" SG_ 1465 ClusterAudiomode 0;
BA_ "GenSigSendType" SG_ 1465 ETM_HUD_Zone1 3;
BA_ "GenSigTimeoutTime_AGSM" SG_ 1465 ETM_HUD_Zone1 0;
BA_ "GenSigTimeoutTime_BCM" SG_ 1465 ETM_HUD_Zone1 0;
BA_ "GenSigTimeoutTime_BSM" SG_ 1465 ETM_HUD_Zone1 0;
BA_ "GenSigTimeoutTime_CADM" SG_ 1465 ETM_HUD_Zone1 0;
BA_ "GenSigTimeoutTime_DMSM" SG_ 1465 ETM_HUD_Zone1 0;
BA_ "GenSigTimeoutTime_DTCM" SG_ 1465 ETM_HUD_Zone1 0;
BA_ "GenSigTimeoutTime_ECM" SG_ 1465 ETM_HUD_Zone1 0;
BA_ "GenSigTimeoutTime_EVCU2" SG_ 1465 ETM_HUD_Zone1 0;
BA_ "GenSigTimeoutTime_GNMM" SG_ 1465 ETM_HUD_Zone1 0;
BA_ "GenSigTimeoutTime_HCP" SG_ 1465 ETM_HUD_Zone1 0;
BA_ "GenSigTimeoutTime_RFHM" SG_ 1465 ETM_HUD_Zone1 0;
BA_ "GenSigTimeoutTime_SGW" SG_ 1465 ETM_HUD_Zone1 0;
BA_ "GenSigTimeoutTime_TCM" SG_ 1465 ETM_HUD_Zone1 0;
BA_ "GenSigSendType" SG_ 1465 ETM_HUD_Zone2 3;
BA_ "GenSigTimeoutTime_AGSM" SG_ 1465 ETM_HUD_Zone2 0;
BA_ "GenSigTimeoutTime_BCM" SG_ 1465 ETM_HUD_Zone2 0;
BA_ "GenSigTimeoutTime_BSM" SG_ 1465 ETM_HUD_Zone2 0;
BA_ "GenSigTimeoutTime_CADM" SG_ 1465 ETM_HUD_Zone2 0;
BA_ "GenSigTimeoutTime_DMSM" SG_ 1465 ETM_HUD_Zone2 0;
BA_ "GenSigTimeoutTime_DTCM" SG_ 1465 ETM_HUD_Zone2 0;
BA_ "GenSigTimeoutTime_ECM" SG_ 1465 ETM_HUD_Zone2 0;
BA_ "GenSigTimeoutTime_EVCU2" SG_ 1465 ETM_HUD_Zone2 0;
BA_ "GenSigTimeoutTime_GNMM" SG_ 1465 ETM_HUD_Zone2 0;
BA_ "GenSigTimeoutTime_HCP" SG_ 1465 ETM_HUD_Zone2 0;
BA_ "GenSigTimeoutTime_RFHM" SG_ 1465 ETM_HUD_Zone2 0;
BA_ "GenSigTimeoutTime_SGW" SG_ 1465 ETM_HUD_Zone2 0;
BA_ "GenSigTimeoutTime_TCM" SG_ 1465 ETM_HUD_Zone2 0;
BA_ "GenSigSendType" SG_ 1465 ETM_HUD_Zone3 3;
BA_ "GenSigTimeoutTime_AGSM" SG_ 1465 ETM_HUD_Zone3 0;
BA_ "GenSigTimeoutTime_BCM" SG_ 1465 ETM_HUD_Zone3 0;
BA_ "GenSigTimeoutTime_BSM" SG_ 1465 ETM_HUD_Zone3 0;
BA_ "GenSigTimeoutTime_CADM" SG_ 1465 ETM_HUD_Zone3 0;
BA_ "GenSigTimeoutTime_DMSM" SG_ 1465 ETM_HUD_Zone3 0;
BA_ "GenSigTimeoutTime_DTCM" SG_ 1465 ETM_HUD_Zone3 0;
BA_ "GenSigTimeoutTime_ECM" SG_ 1465 ETM_HUD_Zone3 0;
BA_ "GenSigTimeoutTime_EVCU2" SG_ 1465 ETM_HUD_Zone3 0;
BA_ "GenSigTimeoutTime_GNMM" SG_ 1465 ETM_HUD_Zone3 0;
BA_ "GenSigTimeoutTime_HCP" SG_ 1465 ETM_HUD_Zone3 0;
BA_ "GenSigTimeoutTime_RFHM" SG_ 1465 ETM_HUD_Zone3 0;
BA_ "GenSigTimeoutTime_SGW" SG_ 1465 ETM_HUD_Zone3 0;
BA_ "GenSigTimeoutTime_TCM" SG_ 1465 ETM_HUD_Zone3 0;
BA_ "GenSigSendType" SG_ 1465 ETM_HUD_Zone4 3;
BA_ "GenSigTimeoutTime_AGSM" SG_ 1465 ETM_HUD_Zone4 0;
BA_ "GenSigTimeoutTime_BCM" SG_ 1465 ETM_HUD_Zone4 0;
BA_ "GenSigTimeoutTime_BSM" SG_ 1465 ETM_HUD_Zone4 0;
BA_ "GenSigTimeoutTime_CADM" SG_ 1465 ETM_HUD_Zone4 0;
BA_ "GenSigTimeoutTime_DMSM" SG_ 1465 ETM_HUD_Zone4 0;
BA_ "GenSigTimeoutTime_DTCM" SG_ 1465 ETM_HUD_Zone4 0;
BA_ "GenSigTimeoutTime_ECM" SG_ 1465 ETM_HUD_Zone4 0;
BA_ "GenSigTimeoutTime_EVCU2" SG_ 1465 ETM_HUD_Zone4 0;
BA_ "GenSigTimeoutTime_GNMM" SG_ 1465 ETM_HUD_Zone4 0;
BA_ "GenSigTimeoutTime_HCP" SG_ 1465 ETM_HUD_Zone4 0;
BA_ "GenSigTimeoutTime_RFHM" SG_ 1465 ETM_HUD_Zone4 0;
BA_ "GenSigTimeoutTime_SGW" SG_ 1465 ETM_HUD_Zone4 0;
BA_ "GenSigTimeoutTime_TCM" SG_ 1465 ETM_HUD_Zone4 0;
BA_ "GenSigSendType" SG_ 1465 ETM_HUD_Zone5 3;
BA_ "GenSigTimeoutTime_AGSM" SG_ 1465 ETM_HUD_Zone5 0;
BA_ "GenSigTimeoutTime_BCM" SG_ 1465 ETM_HUD_Zone5 0;
BA_ "GenSigTimeoutTime_BSM" SG_ 1465 ETM_HUD_Zone5 0;
BA_ "GenSigTimeoutTime_CADM" SG_ 1465 ETM_HUD_Zone5 0;
BA_ "GenSigTimeoutTime_DMSM" SG_ 1465 ETM_HUD_Zone5 0;
BA_ "GenSigTimeoutTime_DTCM" SG_ 1465 ETM_HUD_Zone5 0;
BA_ "GenSigTimeoutTime_ECM" SG_ 1465 ETM_HUD_Zone5 0;
BA_ "GenSigTimeoutTime_EVCU2" SG_ 1465 ETM_HUD_Zone5 0;
BA_ "GenSigTimeoutTime_GNMM" SG_ 1465 ETM_HUD_Zone5 0;
BA_ "GenSigTimeoutTime_HCP" SG_ 1465 ETM_HUD_Zone5 0;
BA_ "GenSigTimeoutTime_RFHM" SG_ 1465 ETM_HUD_Zone5 0;
BA_ "GenSigTimeoutTime_SGW" SG_ 1465 ETM_HUD_Zone5 0;
BA_ "GenSigTimeoutTime_TCM" SG_ 1465 ETM_HUD_Zone5 0;
BA_ "GenSigSendType" SG_ 1465 PSI_Gr1_RPM_SET 3;
BA_ "GenSigTimeoutTime_AGSM" SG_ 1465 PSI_Gr1_RPM_SET 0;
BA_ "GenSigTimeoutTime_BCM" SG_ 1465 PSI_Gr1_RPM_SET 0;
BA_ "GenSigTimeoutTime_BSM" SG_ 1465 PSI_Gr1_RPM_SET 0;
BA_ "GenSigTimeoutTime_CADM" SG_ 1465 PSI_Gr1_RPM_SET 0;
BA_ "GenSigTimeoutTime_DMSM" SG_ 1465 PSI_Gr1_RPM_SET 0;
BA_ "GenSigTimeoutTime_DTCM" SG_ 1465 PSI_Gr1_RPM_SET 0;
BA_ "GenSigTimeoutTime_EVCU2" SG_ 1465 PSI_Gr1_RPM_SET 0;
BA_ "GenSigTimeoutTime_GNMM" SG_ 1465 PSI_Gr1_RPM_SET 0;
BA_ "GenSigTimeoutTime_HCP" SG_ 1465 PSI_Gr1_RPM_SET 0;
BA_ "GenSigTimeoutTime_IPC" SG_ 1465 PSI_Gr1_RPM_SET 0;
BA_ "GenSigTimeoutTime_RFHM" SG_ 1465 PSI_Gr1_RPM_SET 0;
BA_ "GenSigTimeoutTime_SGW" SG_ 1465 PSI_Gr1_RPM_SET 0;
BA_ "GenSigTimeoutTime_TCM" SG_ 1465 PSI_Gr1_RPM_SET 0;
BA_ "GenSigSendType" SG_ 1465 PSI_Gr2_RPM_SET 3;
BA_ "GenSigTimeoutTime_AGSM" SG_ 1465 PSI_Gr2_RPM_SET 0;
BA_ "GenSigTimeoutTime_BCM" SG_ 1465 PSI_Gr2_RPM_SET 0;
BA_ "GenSigTimeoutTime_BSM" SG_ 1465 PSI_Gr2_RPM_SET 0;
BA_ "GenSigTimeoutTime_CADM" SG_ 1465 PSI_Gr2_RPM_SET 0;
BA_ "GenSigTimeoutTime_DMSM" SG_ 1465 PSI_Gr2_RPM_SET 0;
BA_ "GenSigTimeoutTime_DTCM" SG_ 1465 PSI_Gr2_RPM_SET 0;
BA_ "GenSigTimeoutTime_EVCU2" SG_ 1465 PSI_Gr2_RPM_SET 0;
BA_ "GenSigTimeoutTime_GNMM" SG_ 1465 PSI_Gr2_RPM_SET 0;
BA_ "GenSigTimeoutTime_HCP" SG_ 1465 PSI_Gr2_RPM_SET 0;
BA_ "GenSigTimeoutTime_IPC" SG_ 1465 PSI_Gr2_RPM_SET 0;
BA_ "GenSigTimeoutTime_RFHM" SG_ 1465 PSI_Gr2_RPM_SET 0;
BA_ "GenSigTimeoutTime_SGW" SG_ 1465 PSI_Gr2_RPM_SET 0;
BA_ "GenSigTimeoutTime_TCM" SG_ 1465 PSI_Gr2_RPM_SET 0;
BA_ "GenSigSendType" SG_ 1465 PSI_Gr3_RPM_SET 3;
BA_ "GenSigTimeoutTime_AGSM" SG_ 1465 PSI_Gr3_RPM_SET 0;
BA_ "GenSigTimeoutTime_BCM" SG_ 1465 PSI_Gr3_RPM_SET 0;
BA_ "GenSigTimeoutTime_BSM" SG_ 1465 PSI_Gr3_RPM_SET 0;
BA_ "GenSigTimeoutTime_CADM" SG_ 1465 PSI_Gr3_RPM_SET 0;
BA_ "GenSigTimeoutTime_DMSM" SG_ 1465 PSI_Gr3_RPM_SET 0;
BA_ "GenSigTimeoutTime_DTCM" SG_ 1465 PSI_Gr3_RPM_SET 0;
BA_ "GenSigTimeoutTime_EVCU2" SG_ 1465 PSI_Gr3_RPM_SET 0;
BA_ "GenSigTimeoutTime_GNMM" SG_ 1465 PSI_Gr3_RPM_SET 0;
BA_ "GenSigTimeoutTime_HCP" SG_ 1465 PSI_Gr3_RPM_SET 0;
BA_ "GenSigTimeoutTime_IPC" SG_ 1465 PSI_Gr3_RPM_SET 0;
BA_ "GenSigTimeoutTime_RFHM" SG_ 1465 PSI_Gr3_RPM_SET 0;
BA_ "GenSigTimeoutTime_SGW" SG_ 1465 PSI_Gr3_RPM_SET 0;
BA_ "GenSigTimeoutTime_TCM" SG_ 1465 PSI_Gr3_RPM_SET 0;
BA_ "GenSigSendType" SG_ 1465 PSI_Gr4_RPM_SET 3;
BA_ "GenSigTimeoutTime_AGSM" SG_ 1465 PSI_Gr4_RPM_SET 0;
BA_ "GenSigTimeoutTime_BCM" SG_ 1465 PSI_Gr4_RPM_SET 0;
BA_ "GenSigTimeoutTime_BSM" SG_ 1465 PSI_Gr4_RPM_SET 0;
BA_ "GenSigTimeoutTime_CADM" SG_ 1465 PSI_Gr4_RPM_SET 0;
BA_ "GenSigTimeoutTime_DMSM" SG_ 1465 PSI_Gr4_RPM_SET 0;
BA_ "GenSigTimeoutTime_DTCM" SG_ 1465 PSI_Gr4_RPM_SET 0;
BA_ "GenSigTimeoutTime_EVCU2" SG_ 1465 PSI_Gr4_RPM_SET 0;
BA_ "GenSigTimeoutTime_GNMM" SG_ 1465 PSI_Gr4_RPM_SET 0;
BA_ "GenSigTimeoutTime_HCP" SG_ 1465 PSI_Gr4_RPM_SET 0;
BA_ "GenSigTimeoutTime_IPC" SG_ 1465 PSI_Gr4_RPM_SET 0;
BA_ "GenSigTimeoutTime_RFHM" SG_ 1465 PSI_Gr4_RPM_SET 0;
BA_ "GenSigTimeoutTime_SGW" SG_ 1465 PSI_Gr4_RPM_SET 0;
BA_ "GenSigTimeoutTime_TCM" SG_ 1465 PSI_Gr4_RPM_SET 0;
BA_ "GenSigSendType" SG_ 1465 PSI_Gr5_RPM_SET 3;
BA_ "GenSigTimeoutTime_AGSM" SG_ 1465 PSI_Gr5_RPM_SET 0;
BA_ "GenSigTimeoutTime_BCM" SG_ 1465 PSI_Gr5_RPM_SET 0;
BA_ "GenSigTimeoutTime_BSM" SG_ 1465 PSI_Gr5_RPM_SET 0;
BA_ "GenSigTimeoutTime_CADM" SG_ 1465 PSI_Gr5_RPM_SET 0;
BA_ "GenSigTimeoutTime_DMSM" SG_ 1465 PSI_Gr5_RPM_SET 0;
BA_ "GenSigTimeoutTime_DTCM" SG_ 1465 PSI_Gr5_RPM_SET 0;
BA_ "GenSigTimeoutTime_EVCU2" SG_ 1465 PSI_Gr5_RPM_SET 0;
BA_ "GenSigTimeoutTime_GNMM" SG_ 1465 PSI_Gr5_RPM_SET 0;
BA_ "GenSigTimeoutTime_HCP" SG_ 1465 PSI_Gr5_RPM_SET 0;
BA_ "GenSigTimeoutTime_IPC" SG_ 1465 PSI_Gr5_RPM_SET 0;
BA_ "GenSigTimeoutTime_RFHM" SG_ 1465 PSI_Gr5_RPM_SET 0;
BA_ "GenSigTimeoutTime_SGW" SG_ 1465 PSI_Gr5_RPM_SET 0;
BA_ "GenSigTimeoutTime_TCM" SG_ 1465 PSI_Gr5_RPM_SET 0;
BA_ "GenSigSendType" SG_ 1465 PSI_RPM_Reset 3;
BA_ "GenSigTimeoutTime_AGSM" SG_ 1465 PSI_RPM_Reset 0;
BA_ "GenSigTimeoutTime_BCM" SG_ 1465 PSI_RPM_Reset 0;
BA_ "GenSigTimeoutTime_BSM" SG_ 1465 PSI_RPM_Reset 0;
BA_ "GenSigTimeoutTime_CADM" SG_ 1465 PSI_RPM_Reset 0;
BA_ "GenSigTimeoutTime_DMSM" SG_ 1465 PSI_RPM_Reset 0;
BA_ "GenSigTimeoutTime_DTCM" SG_ 1465 PSI_RPM_Reset 0;
BA_ "GenSigTimeoutTime_EVCU2" SG_ 1465 PSI_RPM_Reset 0;
BA_ "GenSigTimeoutTime_GNMM" SG_ 1465 PSI_RPM_Reset 0;
BA_ "GenSigTimeoutTime_HCP" SG_ 1465 PSI_RPM_Reset 0;
BA_ "GenSigTimeoutTime_IPC" SG_ 1465 PSI_RPM_Reset 0;
BA_ "GenSigTimeoutTime_RFHM" SG_ 1465 PSI_RPM_Reset 0;
BA_ "GenSigTimeoutTime_SGW" SG_ 1465 PSI_RPM_Reset 0;
BA_ "GenSigTimeoutTime_TCM" SG_ 1465 PSI_RPM_Reset 0;
BA_ "GenSigSendType" SG_ 1465 PSI_Rq 3;
BA_ "GenSigTimeoutTime_AGSM" SG_ 1465 PSI_Rq 0;
BA_ "GenSigTimeoutTime_BCM" SG_ 1465 PSI_Rq 0;
BA_ "GenSigTimeoutTime_BSM" SG_ 1465 PSI_Rq 0;
BA_ "GenSigTimeoutTime_CADM" SG_ 1465 PSI_Rq 0;
BA_ "GenSigTimeoutTime_DMSM" SG_ 1465 PSI_Rq 0;
BA_ "GenSigTimeoutTime_DTCM" SG_ 1465 PSI_Rq 0;
BA_ "GenSigTimeoutTime_EVCU2" SG_ 1465 PSI_Rq 0;
BA_ "GenSigTimeoutTime_GNMM" SG_ 1465 PSI_Rq 0;
BA_ "GenSigTimeoutTime_HCP" SG_ 1465 PSI_Rq 0;
BA_ "GenSigTimeoutTime_IPC" SG_ 1465 PSI_Rq 0;
BA_ "GenSigTimeoutTime_RFHM" SG_ 1465 PSI_Rq 0;
BA_ "GenSigTimeoutTime_SGW" SG_ 1465 PSI_Rq 0;
BA_ "GenSigTimeoutTime_TCM" SG_ 1465 PSI_Rq 0;
BA_ "GenSigSendType" SG_ 1465 RACE_CLDWN_ON_OFF_REQ 3;
BA_ "GenSigTimeoutTime_AGSM" SG_ 1465 RACE_CLDWN_ON_OFF_REQ 0;
BA_ "GenSigTimeoutTime_BCM" SG_ 1465 RACE_CLDWN_ON_OFF_REQ 0;
BA_ "GenSigTimeoutTime_BSM" SG_ 1465 RACE_CLDWN_ON_OFF_REQ 0;
BA_ "GenSigTimeoutTime_CADM" SG_ 1465 RACE_CLDWN_ON_OFF_REQ 0;
BA_ "GenSigTimeoutTime_DMSM" SG_ 1465 RACE_CLDWN_ON_OFF_REQ 0;
BA_ "GenSigTimeoutTime_DTCM" SG_ 1465 RACE_CLDWN_ON_OFF_REQ 0;
BA_ "GenSigTimeoutTime_EVCU2" SG_ 1465 RACE_CLDWN_ON_OFF_REQ 0;
BA_ "GenSigTimeoutTime_GNMM" SG_ 1465 RACE_CLDWN_ON_OFF_REQ 0;
BA_ "GenSigTimeoutTime_HCP" SG_ 1465 RACE_CLDWN_ON_OFF_REQ 0;
BA_ "GenSigTimeoutTime_IPC" SG_ 1465 RACE_CLDWN_ON_OFF_REQ 0;
BA_ "GenSigTimeoutTime_RFHM" SG_ 1465 RACE_CLDWN_ON_OFF_REQ 0;
BA_ "GenSigTimeoutTime_SGW" SG_ 1465 RACE_CLDWN_ON_OFF_REQ 0;
BA_ "GenSigTimeoutTime_TCM" SG_ 1465 RACE_CLDWN_ON_OFF_REQ 0;
BA_ "GenSigSendType" SG_ 1465 Radio_Delete_Request 3;
BA_ "GenSigTimeoutTime_AGSM" SG_ 1465 Radio_Delete_Request 0;
BA_ "GenSigTimeoutTime_BCM" SG_ 1465 Radio_Delete_Request 0;
BA_ "GenSigTimeoutTime_BSM" SG_ 1465 Radio_Delete_Request 0;
BA_ "GenSigTimeoutTime_CADM" SG_ 1465 Radio_Delete_Request 0;
BA_ "GenSigTimeoutTime_DMSM" SG_ 1465 Radio_Delete_Request 0;
BA_ "GenSigTimeoutTime_DTCM" SG_ 1465 Radio_Delete_Request 0;
BA_ "GenSigTimeoutTime_ECM" SG_ 1465 Radio_Delete_Request 0;
BA_ "GenSigTimeoutTime_EVCU2" SG_ 1465 Radio_Delete_Request 0;
BA_ "GenSigTimeoutTime_GNMM" SG_ 1465 Radio_Delete_Request 0;
BA_ "GenSigTimeoutTime_HCP" SG_ 1465 Radio_Delete_Request 0;
BA_ "GenSigTimeoutTime_RFHM" SG_ 1465 Radio_Delete_Request 0;
BA_ "GenSigTimeoutTime_SGW" SG_ 1465 Radio_Delete_Request 0;
BA_ "GenSigTimeoutTime_TCM" SG_ 1465 Radio_Delete_Request 0;
BA_ "GenSigSendType" SG_ 1465 Radio_Profile_Request 3;
BA_ "GenSigTimeoutTime_AGSM" SG_ 1465 Radio_Profile_Request 0;
BA_ "GenSigTimeoutTime_BCM" SG_ 1465 Radio_Profile_Request 0;
BA_ "GenSigTimeoutTime_BSM" SG_ 1465 Radio_Profile_Request 0;
BA_ "GenSigTimeoutTime_CADM" SG_ 1465 Radio_Profile_Request 0;
BA_ "GenSigTimeoutTime_DMSM" SG_ 1465 Radio_Profile_Request 0;
BA_ "GenSigTimeoutTime_DTCM" SG_ 1465 Radio_Profile_Request 0;
BA_ "GenSigTimeoutTime_ECM" SG_ 1465 Radio_Profile_Request 0;
BA_ "GenSigTimeoutTime_EVCU2" SG_ 1465 Radio_Profile_Request 0;
BA_ "GenSigTimeoutTime_GNMM" SG_ 1465 Radio_Profile_Request 0;
BA_ "GenSigTimeoutTime_HCP" SG_ 1465 Radio_Profile_Request 0;
BA_ "GenSigTimeoutTime_RFHM" SG_ 1465 Radio_Profile_Request 0;
BA_ "GenSigTimeoutTime_SGW" SG_ 1465 Radio_Profile_Request 0;
BA_ "GenSigTimeoutTime_TCM" SG_ 1465 Radio_Profile_Request 0;
BA_ "GenSigSendType" SG_ 1465 TGW_CAMERA_DISP_STAT 3;
BA_ "GenSigTimeoutTime_AGSM" SG_ 1465 TGW_CAMERA_DISP_STAT 0;
BA_ "GenSigTimeoutTime_BSM" SG_ 1465 TGW_CAMERA_DISP_STAT 0;
BA_ "GenSigTimeoutTime_CADM" SG_ 1465 TGW_CAMERA_DISP_STAT 0;
BA_ "GenSigTimeoutTime_DMSM" SG_ 1465 TGW_CAMERA_DISP_STAT 0;
BA_ "GenSigTimeoutTime_DTCM" SG_ 1465 TGW_CAMERA_DISP_STAT 0;
BA_ "GenSigTimeoutTime_ECM" SG_ 1465 TGW_CAMERA_DISP_STAT 0;
BA_ "GenSigTimeoutTime_EVCU2" SG_ 1465 TGW_CAMERA_DISP_STAT 0;
BA_ "GenSigTimeoutTime_GNMM" SG_ 1465 TGW_CAMERA_DISP_STAT 0;
BA_ "GenSigTimeoutTime_HCP" SG_ 1465 TGW_CAMERA_DISP_STAT 0;
BA_ "GenSigTimeoutTime_IPC" SG_ 1465 TGW_CAMERA_DISP_STAT 0;
BA_ "GenSigTimeoutTime_RFHM" SG_ 1465 TGW_CAMERA_DISP_STAT 0;
BA_ "GenSigTimeoutTime_SGW" SG_ 1465 TGW_CAMERA_DISP_STAT 0;
BA_ "GenSigTimeoutTime_TCM" SG_ 1465 TGW_CAMERA_DISP_STAT 0;
BA_ "GenSigSendType" SG_ 1466 Center_Cluster_Button_function 3;
BA_ "GenSigTimeoutTime_AGSM" SG_ 1466 Center_Cluster_Button_function 0;
BA_ "GenSigTimeoutTime_BCM" SG_ 1466 Center_Cluster_Button_function 0;
BA_ "GenSigTimeoutTime_BSM" SG_ 1466 Center_Cluster_Button_function 0;
BA_ "GenSigTimeoutTime_CADM" SG_ 1466 Center_Cluster_Button_function 0;
BA_ "GenSigTimeoutTime_DMSM" SG_ 1466 Center_Cluster_Button_function 0;
BA_ "GenSigTimeoutTime_DTCM" SG_ 1466 Center_Cluster_Button_function 0;
BA_ "GenSigTimeoutTime_ECM" SG_ 1466 Center_Cluster_Button_function 0;
BA_ "GenSigTimeoutTime_EVCU2" SG_ 1466 Center_Cluster_Button_function 0;
BA_ "GenSigTimeoutTime_GNMM" SG_ 1466 Center_Cluster_Button_function 0;
BA_ "GenSigTimeoutTime_HCP" SG_ 1466 Center_Cluster_Button_function 0;
BA_ "GenSigTimeoutTime_RFHM" SG_ 1466 Center_Cluster_Button_function 0;
BA_ "GenSigTimeoutTime_SGW" SG_ 1466 Center_Cluster_Button_function 0;
BA_ "GenSigTimeoutTime_TCM" SG_ 1466 Center_Cluster_Button_function 0;
BA_ "GenSigSendType" SG_ 1466 ChargeNow 3;
BA_ "GenSigTimeoutTime_AGSM" SG_ 1466 ChargeNow 0;
BA_ "GenSigTimeoutTime_BCM" SG_ 1466 ChargeNow 0;
BA_ "GenSigTimeoutTime_BSM" SG_ 1466 ChargeNow 0;
BA_ "GenSigTimeoutTime_CADM" SG_ 1466 ChargeNow 0;
BA_ "GenSigTimeoutTime_DMSM" SG_ 1466 ChargeNow 0;
BA_ "GenSigTimeoutTime_DTCM" SG_ 1466 ChargeNow 0;
BA_ "GenSigTimeoutTime_ECM" SG_ 1466 ChargeNow 0;
BA_ "GenSigTimeoutTime_GNMM" SG_ 1466 ChargeNow 0;
BA_ "GenSigTimeoutTime_HCP" SG_ 1466 ChargeNow 0;
BA_ "GenSigTimeoutTime_IPC" SG_ 1466 ChargeNow 0;
BA_ "GenSigTimeoutTime_RFHM" SG_ 1466 ChargeNow 0;
BA_ "GenSigTimeoutTime_SGW" SG_ 1466 ChargeNow 0;
BA_ "GenSigTimeoutTime_TCM" SG_ 1466 ChargeNow 0;
BA_ "GenSigSendType" SG_ 1466 ETM_HUD_CustomSetting 3;
BA_ "GenSigTimeoutTime_AGSM" SG_ 1466 ETM_HUD_CustomSetting 0;
BA_ "GenSigTimeoutTime_BCM" SG_ 1466 ETM_HUD_CustomSetting 0;
BA_ "GenSigTimeoutTime_BSM" SG_ 1466 ETM_HUD_CustomSetting 0;
BA_ "GenSigTimeoutTime_CADM" SG_ 1466 ETM_HUD_CustomSetting 0;
BA_ "GenSigTimeoutTime_DMSM" SG_ 1466 ETM_HUD_CustomSetting 0;
BA_ "GenSigTimeoutTime_DTCM" SG_ 1466 ETM_HUD_CustomSetting 0;
BA_ "GenSigTimeoutTime_ECM" SG_ 1466 ETM_HUD_CustomSetting 0;
BA_ "GenSigTimeoutTime_EVCU2" SG_ 1466 ETM_HUD_CustomSetting 0;
BA_ "GenSigTimeoutTime_GNMM" SG_ 1466 ETM_HUD_CustomSetting 0;
BA_ "GenSigTimeoutTime_HCP" SG_ 1466 ETM_HUD_CustomSetting 0;
BA_ "GenSigTimeoutTime_RFHM" SG_ 1466 ETM_HUD_CustomSetting 0;
BA_ "GenSigTimeoutTime_SGW" SG_ 1466 ETM_HUD_CustomSetting 0;
BA_ "GenSigTimeoutTime_TCM" SG_ 1466 ETM_HUD_CustomSetting 0;
BA_ "GenSigSendType" SG_ 1466 ETM_HUD_Layout 3;
BA_ "GenSigTimeoutTime_AGSM" SG_ 1466 ETM_HUD_Layout 0;
BA_ "GenSigTimeoutTime_BCM" SG_ 1466 ETM_HUD_Layout 0;
BA_ "GenSigTimeoutTime_BSM" SG_ 1466 ETM_HUD_Layout 0;
BA_ "GenSigTimeoutTime_CADM" SG_ 1466 ETM_HUD_Layout 0;
BA_ "GenSigTimeoutTime_DMSM" SG_ 1466 ETM_HUD_Layout 0;
BA_ "GenSigTimeoutTime_DTCM" SG_ 1466 ETM_HUD_Layout 0;
BA_ "GenSigTimeoutTime_ECM" SG_ 1466 ETM_HUD_Layout 0;
BA_ "GenSigTimeoutTime_EVCU2" SG_ 1466 ETM_HUD_Layout 0;
BA_ "GenSigTimeoutTime_GNMM" SG_ 1466 ETM_HUD_Layout 0;
BA_ "GenSigTimeoutTime_HCP" SG_ 1466 ETM_HUD_Layout 0;
BA_ "GenSigTimeoutTime_RFHM" SG_ 1466 ETM_HUD_Layout 0;
BA_ "GenSigTimeoutTime_SGW" SG_ 1466 ETM_HUD_Layout 0;
BA_ "GenSigTimeoutTime_TCM" SG_ 1466 ETM_HUD_Layout 0;
BA_ "GenSigStartValue" SG_ 1466 GPS_Elevation 65535;
BA_ "GenSigSendType" SG_ 1466 GPS_Elevation 4;
BA_ "GenSigTimeoutTime_AGSM" SG_ 1466 GPS_Elevation 0;
BA_ "GenSigTimeoutTime_BCM" SG_ 1466 GPS_Elevation 0;
BA_ "GenSigTimeoutTime_BSM" SG_ 1466 GPS_Elevation 0;
BA_ "GenSigTimeoutTime_CADM" SG_ 1466 GPS_Elevation 0;
BA_ "GenSigTimeoutTime_DMSM" SG_ 1466 GPS_Elevation 0;
BA_ "GenSigTimeoutTime_DTCM" SG_ 1466 GPS_Elevation 0;
BA_ "GenSigTimeoutTime_ECM" SG_ 1466 GPS_Elevation 0;
BA_ "GenSigTimeoutTime_EVCU2" SG_ 1466 GPS_Elevation 0;
BA_ "GenSigTimeoutTime_GNMM" SG_ 1466 GPS_Elevation 0;
BA_ "GenSigTimeoutTime_HCP" SG_ 1466 GPS_Elevation 0;
BA_ "GenSigTimeoutTime_RFHM" SG_ 1466 GPS_Elevation 0;
BA_ "GenSigTimeoutTime_SGW" SG_ 1466 GPS_Elevation 0;
BA_ "GenSigTimeoutTime_TCM" SG_ 1466 GPS_Elevation 0;
BA_ "GenSigSendType" SG_ 1466 HUtoIPC_NAV_Sts 3;
BA_ "GenSigTimeoutTime_AGSM" SG_ 1466 HUtoIPC_NAV_Sts 0;
BA_ "GenSigTimeoutTime_BCM" SG_ 1466 HUtoIPC_NAV_Sts 0;
BA_ "GenSigTimeoutTime_BSM" SG_ 1466 HUtoIPC_NAV_Sts 0;
BA_ "GenSigTimeoutTime_CADM" SG_ 1466 HUtoIPC_NAV_Sts 0;
BA_ "GenSigTimeoutTime_DMSM" SG_ 1466 HUtoIPC_NAV_Sts 0;
BA_ "GenSigTimeoutTime_DTCM" SG_ 1466 HUtoIPC_NAV_Sts 0;
BA_ "GenSigTimeoutTime_ECM" SG_ 1466 HUtoIPC_NAV_Sts 0;
BA_ "GenSigTimeoutTime_EVCU2" SG_ 1466 HUtoIPC_NAV_Sts 0;
BA_ "GenSigTimeoutTime_GNMM" SG_ 1466 HUtoIPC_NAV_Sts 0;
BA_ "GenSigTimeoutTime_HCP" SG_ 1466 HUtoIPC_NAV_Sts 0;
BA_ "GenSigTimeoutTime_RFHM" SG_ 1466 HUtoIPC_NAV_Sts 0;
BA_ "GenSigTimeoutTime_SGW" SG_ 1466 HUtoIPC_NAV_Sts 0;
BA_ "GenSigTimeoutTime_TCM" SG_ 1466 HUtoIPC_NAV_Sts 0;
BA_ "GenSigSendType" SG_ 1466 Left_Cluster_Button_function 3;
BA_ "GenSigTimeoutTime_AGSM" SG_ 1466 Left_Cluster_Button_function 0;
BA_ "GenSigTimeoutTime_BCM" SG_ 1466 Left_Cluster_Button_function 0;
BA_ "GenSigTimeoutTime_BSM" SG_ 1466 Left_Cluster_Button_function 0;
BA_ "GenSigTimeoutTime_CADM" SG_ 1466 Left_Cluster_Button_function 0;
BA_ "GenSigTimeoutTime_DMSM" SG_ 1466 Left_Cluster_Button_function 0;
BA_ "GenSigTimeoutTime_DTCM" SG_ 1466 Left_Cluster_Button_function 0;
BA_ "GenSigTimeoutTime_ECM" SG_ 1466 Left_Cluster_Button_function 0;
BA_ "GenSigTimeoutTime_EVCU2" SG_ 1466 Left_Cluster_Button_function 0;
BA_ "GenSigTimeoutTime_GNMM" SG_ 1466 Left_Cluster_Button_function 0;
BA_ "GenSigTimeoutTime_HCP" SG_ 1466 Left_Cluster_Button_function 0;
BA_ "GenSigTimeoutTime_RFHM" SG_ 1466 Left_Cluster_Button_function 0;
BA_ "GenSigTimeoutTime_SGW" SG_ 1466 Left_Cluster_Button_function 0;
BA_ "GenSigTimeoutTime_TCM" SG_ 1466 Left_Cluster_Button_function 0;
BA_ "GenSigSendType" SG_ 1466 Right_Cluster_Button_function 3;
BA_ "GenSigTimeoutTime_AGSM" SG_ 1466 Right_Cluster_Button_function 0;
BA_ "GenSigTimeoutTime_BCM" SG_ 1466 Right_Cluster_Button_function 0;
BA_ "GenSigTimeoutTime_BSM" SG_ 1466 Right_Cluster_Button_function 0;
BA_ "GenSigTimeoutTime_CADM" SG_ 1466 Right_Cluster_Button_function 0;
BA_ "GenSigTimeoutTime_DMSM" SG_ 1466 Right_Cluster_Button_function 0;
BA_ "GenSigTimeoutTime_DTCM" SG_ 1466 Right_Cluster_Button_function 0;
BA_ "GenSigTimeoutTime_ECM" SG_ 1466 Right_Cluster_Button_function 0;
BA_ "GenSigTimeoutTime_EVCU2" SG_ 1466 Right_Cluster_Button_function 0;
BA_ "GenSigTimeoutTime_GNMM" SG_ 1466 Right_Cluster_Button_function 0;
BA_ "GenSigTimeoutTime_HCP" SG_ 1466 Right_Cluster_Button_function 0;
BA_ "GenSigTimeoutTime_RFHM" SG_ 1466 Right_Cluster_Button_function 0;
BA_ "GenSigTimeoutTime_SGW" SG_ 1466 Right_Cluster_Button_function 0;
BA_ "GenSigTimeoutTime_TCM" SG_ 1466 Right_Cluster_Button_function 0;
BA_ "GenSigSendType" SG_ 150 FirstFrame_NavTbT 3;
BA_ "GenSigTimeoutTime_AGSM" SG_ 150 FirstFrame_NavTbT 0;
BA_ "GenSigTimeoutTime_BCM" SG_ 150 FirstFrame_NavTbT 0;
BA_ "GenSigTimeoutTime_BSM" SG_ 150 FirstFrame_NavTbT 0;
BA_ "GenSigTimeoutTime_CADM" SG_ 150 FirstFrame_NavTbT 0;
BA_ "GenSigTimeoutTime_DMSM" SG_ 150 FirstFrame_NavTbT 0;
BA_ "GenSigTimeoutTime_DTCM" SG_ 150 FirstFrame_NavTbT 0;
BA_ "GenSigTimeoutTime_ECM" SG_ 150 FirstFrame_NavTbT 0;
BA_ "GenSigTimeoutTime_EVCU2" SG_ 150 FirstFrame_NavTbT 0;
BA_ "GenSigTimeoutTime_GNMM" SG_ 150 FirstFrame_NavTbT 0;
BA_ "GenSigTimeoutTime_HCP" SG_ 150 FirstFrame_NavTbT 0;
BA_ "GenSigTimeoutTime_RFHM" SG_ 150 FirstFrame_NavTbT 0;
BA_ "GenSigTimeoutTime_SGW" SG_ 150 FirstFrame_NavTbT 0;
BA_ "GenSigTimeoutTime_TCM" SG_ 150 FirstFrame_NavTbT 0;
BA_ "GenSigSendType" SG_ 150 NumMultiMessage_NavTbT 3;
BA_ "GenSigTimeoutTime_AGSM" SG_ 150 NumMultiMessage_NavTbT 0;
BA_ "GenSigTimeoutTime_BCM" SG_ 150 NumMultiMessage_NavTbT 0;
BA_ "GenSigTimeoutTime_BSM" SG_ 150 NumMultiMessage_NavTbT 0;
BA_ "GenSigTimeoutTime_CADM" SG_ 150 NumMultiMessage_NavTbT 0;
BA_ "GenSigTimeoutTime_DMSM" SG_ 150 NumMultiMessage_NavTbT 0;
BA_ "GenSigTimeoutTime_DTCM" SG_ 150 NumMultiMessage_NavTbT 0;
BA_ "GenSigTimeoutTime_ECM" SG_ 150 NumMultiMessage_NavTbT 0;
BA_ "GenSigTimeoutTime_EVCU2" SG_ 150 NumMultiMessage_NavTbT 0;
BA_ "GenSigTimeoutTime_GNMM" SG_ 150 NumMultiMessage_NavTbT 0;
BA_ "GenSigTimeoutTime_HCP" SG_ 150 NumMultiMessage_NavTbT 0;
BA_ "GenSigTimeoutTime_RFHM" SG_ 150 NumMultiMessage_NavTbT 0;
BA_ "GenSigTimeoutTime_SGW" SG_ 150 NumMultiMessage_NavTbT 0;
BA_ "GenSigTimeoutTime_TCM" SG_ 150 NumMultiMessage_NavTbT 0;
BA_ "GenSigSendType" SG_ 150 Text_Characters_NavTbT 3;
BA_ "GenSigTimeoutTime_AGSM" SG_ 150 Text_Characters_NavTbT 0;
BA_ "GenSigTimeoutTime_BCM" SG_ 150 Text_Characters_NavTbT 0;
BA_ "GenSigTimeoutTime_BSM" SG_ 150 Text_Characters_NavTbT 0;
BA_ "GenSigTimeoutTime_CADM" SG_ 150 Text_Characters_NavTbT 0;
BA_ "GenSigTimeoutTime_DMSM" SG_ 150 Text_Characters_NavTbT 0;
BA_ "GenSigTimeoutTime_DTCM" SG_ 150 Text_Characters_NavTbT 0;
BA_ "GenSigTimeoutTime_ECM" SG_ 150 Text_Characters_NavTbT 0;
BA_ "GenSigTimeoutTime_EVCU2" SG_ 150 Text_Characters_NavTbT 0;
BA_ "GenSigTimeoutTime_GNMM" SG_ 150 Text_Characters_NavTbT 0;
BA_ "GenSigTimeoutTime_HCP" SG_ 150 Text_Characters_NavTbT 0;
BA_ "GenSigTimeoutTime_RFHM" SG_ 150 Text_Characters_NavTbT 0;
BA_ "GenSigTimeoutTime_SGW" SG_ 150 Text_Characters_NavTbT 0;
BA_ "GenSigTimeoutTime_TCM" SG_ 150 Text_Characters_NavTbT 0;
BA_ "GenSigSendType" SG_ 150 Text_Type_NavTbT 3;
BA_ "GenSigTimeoutTime_AGSM" SG_ 150 Text_Type_NavTbT 0;
BA_ "GenSigTimeoutTime_BCM" SG_ 150 Text_Type_NavTbT 0;
BA_ "GenSigTimeoutTime_BSM" SG_ 150 Text_Type_NavTbT 0;
BA_ "GenSigTimeoutTime_CADM" SG_ 150 Text_Type_NavTbT 0;
BA_ "GenSigTimeoutTime_DMSM" SG_ 150 Text_Type_NavTbT 0;
BA_ "GenSigTimeoutTime_DTCM" SG_ 150 Text_Type_NavTbT 0;
BA_ "GenSigTimeoutTime_ECM" SG_ 150 Text_Type_NavTbT 0;
BA_ "GenSigTimeoutTime_EVCU2" SG_ 150 Text_Type_NavTbT 0;
BA_ "GenSigTimeoutTime_GNMM" SG_ 150 Text_Type_NavTbT 0;
BA_ "GenSigTimeoutTime_HCP" SG_ 150 Text_Type_NavTbT 0;
BA_ "GenSigTimeoutTime_RFHM" SG_ 150 Text_Type_NavTbT 0;
BA_ "GenSigTimeoutTime_SGW" SG_ 150 Text_Type_NavTbT 0;
BA_ "GenSigTimeoutTime_TCM" SG_ 150 Text_Type_NavTbT 0;
BA_ "GenSigSendType" SG_ 154 Text_Characters_Aud_Ph 3;
BA_ "GenSigTimeoutTime_AGSM" SG_ 154 Text_Characters_Aud_Ph 0;
BA_ "GenSigTimeoutTime_BCM" SG_ 154 Text_Characters_Aud_Ph 0;
BA_ "GenSigTimeoutTime_BSM" SG_ 154 Text_Characters_Aud_Ph 0;
BA_ "GenSigTimeoutTime_CADM" SG_ 154 Text_Characters_Aud_Ph 0;
BA_ "GenSigTimeoutTime_DMSM" SG_ 154 Text_Characters_Aud_Ph 0;
BA_ "GenSigTimeoutTime_DTCM" SG_ 154 Text_Characters_Aud_Ph 0;
BA_ "GenSigTimeoutTime_ECM" SG_ 154 Text_Characters_Aud_Ph 0;
BA_ "GenSigTimeoutTime_EVCU2" SG_ 154 Text_Characters_Aud_Ph 0;
BA_ "GenSigTimeoutTime_GNMM" SG_ 154 Text_Characters_Aud_Ph 0;
BA_ "GenSigTimeoutTime_HCP" SG_ 154 Text_Characters_Aud_Ph 0;
BA_ "GenSigTimeoutTime_RFHM" SG_ 154 Text_Characters_Aud_Ph 0;
BA_ "GenSigTimeoutTime_SGW" SG_ 154 Text_Characters_Aud_Ph 0;
BA_ "GenSigTimeoutTime_TCM" SG_ 154 Text_Characters_Aud_Ph 0;
BA_ "GenSigSendType" SG_ 154 Text_Type_Aud_Ph 3;
BA_ "GenSigTimeoutTime_AGSM" SG_ 154 Text_Type_Aud_Ph 0;
BA_ "GenSigTimeoutTime_BCM" SG_ 154 Text_Type_Aud_Ph 0;
BA_ "GenSigTimeoutTime_BSM" SG_ 154 Text_Type_Aud_Ph 0;
BA_ "GenSigTimeoutTime_CADM" SG_ 154 Text_Type_Aud_Ph 0;
BA_ "GenSigTimeoutTime_DMSM" SG_ 154 Text_Type_Aud_Ph 0;
BA_ "GenSigTimeoutTime_DTCM" SG_ 154 Text_Type_Aud_Ph 0;
BA_ "GenSigTimeoutTime_ECM" SG_ 154 Text_Type_Aud_Ph 0;
BA_ "GenSigTimeoutTime_EVCU2" SG_ 154 Text_Type_Aud_Ph 0;
BA_ "GenSigTimeoutTime_GNMM" SG_ 154 Text_Type_Aud_Ph 0;
BA_ "GenSigTimeoutTime_HCP" SG_ 154 Text_Type_Aud_Ph 0;
BA_ "GenSigTimeoutTime_RFHM" SG_ 154 Text_Type_Aud_Ph 0;
BA_ "GenSigTimeoutTime_SGW" SG_ 154 Text_Type_Aud_Ph 0;
BA_ "GenSigTimeoutTime_TCM" SG_ 154 Text_Type_Aud_Ph 0;
BA_ "GenSigTimeoutTime_AGSM" SG_ 145 CRC_TELEMATIC_FD_19 0;
BA_ "GenSigTimeoutTime_BCM" SG_ 145 CRC_TELEMATIC_FD_19 0;
BA_ "GenSigTimeoutTime_BSM" SG_ 145 CRC_TELEMATIC_FD_19 0;
BA_ "GenSigTimeoutTime_CADM" SG_ 145 CRC_TELEMATIC_FD_19 0;
BA_ "GenSigTimeoutTime_DMSM" SG_ 145 CRC_TELEMATIC_FD_19 0;
BA_ "GenSigTimeoutTime_DTCM" SG_ 145 CRC_TELEMATIC_FD_19 0;
BA_ "GenSigTimeoutTime_ECM" SG_ 145 CRC_TELEMATIC_FD_19 0;
BA_ "GenSigTimeoutTime_GNMM" SG_ 145 CRC_TELEMATIC_FD_19 0;
BA_ "GenSigTimeoutTime_HCP" SG_ 145 CRC_TELEMATIC_FD_19 0;
BA_ "GenSigTimeoutTime_IPC" SG_ 145 CRC_TELEMATIC_FD_19 0;
BA_ "GenSigTimeoutTime_RFHM" SG_ 145 CRC_TELEMATIC_FD_19 0;
BA_ "GenSigTimeoutTime_SGW" SG_ 145 CRC_TELEMATIC_FD_19 0;
BA_ "GenSigTimeoutTime_TCM" SG_ 145 CRC_TELEMATIC_FD_19 0;
BA_ "GenSigTimeoutTime_AGSM" SG_ 145 MessageCounter_TELEMATIC_FD_19 0;
BA_ "GenSigTimeoutTime_BCM" SG_ 145 MessageCounter_TELEMATIC_FD_19 0;
BA_ "GenSigTimeoutTime_BSM" SG_ 145 MessageCounter_TELEMATIC_FD_19 0;
BA_ "GenSigTimeoutTime_CADM" SG_ 145 MessageCounter_TELEMATIC_FD_19 0;
BA_ "GenSigTimeoutTime_DMSM" SG_ 145 MessageCounter_TELEMATIC_FD_19 0;
BA_ "GenSigTimeoutTime_DTCM" SG_ 145 MessageCounter_TELEMATIC_FD_19 0;
BA_ "GenSigTimeoutTime_ECM" SG_ 145 MessageCounter_TELEMATIC_FD_19 0;
BA_ "GenSigTimeoutTime_GNMM" SG_ 145 MessageCounter_TELEMATIC_FD_19 0;
BA_ "GenSigTimeoutTime_HCP" SG_ 145 MessageCounter_TELEMATIC_FD_19 0;
BA_ "GenSigTimeoutTime_IPC" SG_ 145 MessageCounter_TELEMATIC_FD_19 0;
BA_ "GenSigTimeoutTime_RFHM" SG_ 145 MessageCounter_TELEMATIC_FD_19 0;
BA_ "GenSigTimeoutTime_SGW" SG_ 145 MessageCounter_TELEMATIC_FD_19 0;
BA_ "GenSigTimeoutTime_TCM" SG_ 145 MessageCounter_TELEMATIC_FD_19 0;
BA_ "GenSigSendType" SG_ 145 PlugAndChargeReq 3;
BA_ "GenSigTimeoutTime_AGSM" SG_ 145 PlugAndChargeReq 0;
BA_ "GenSigTimeoutTime_BCM" SG_ 145 PlugAndChargeReq 0;
BA_ "GenSigTimeoutTime_BSM" SG_ 145 PlugAndChargeReq 0;
BA_ "GenSigTimeoutTime_CADM" SG_ 145 PlugAndChargeReq 0;
BA_ "GenSigTimeoutTime_DMSM" SG_ 145 PlugAndChargeReq 0;
BA_ "GenSigTimeoutTime_DTCM" SG_ 145 PlugAndChargeReq 0;
BA_ "GenSigTimeoutTime_ECM" SG_ 145 PlugAndChargeReq 0;
BA_ "GenSigTimeoutTime_GNMM" SG_ 145 PlugAndChargeReq 0;
BA_ "GenSigTimeoutTime_HCP" SG_ 145 PlugAndChargeReq 0;
BA_ "GenSigTimeoutTime_IPC" SG_ 145 PlugAndChargeReq 0;
BA_ "GenSigTimeoutTime_RFHM" SG_ 145 PlugAndChargeReq 0;
BA_ "GenSigTimeoutTime_SGW" SG_ 145 PlugAndChargeReq 0;
BA_ "GenSigTimeoutTime_TCM" SG_ 145 PlugAndChargeReq 0;
BA_ "GenSigSendType" SG_ 145 Secure_Idle_Req 3;
BA_ "GenSigTimeoutTime_AGSM" SG_ 145 Secure_Idle_Req 0;
BA_ "GenSigTimeoutTime_BCM" SG_ 145 Secure_Idle_Req 0;
BA_ "GenSigTimeoutTime_BSM" SG_ 145 Secure_Idle_Req 0;
BA_ "GenSigTimeoutTime_CADM" SG_ 145 Secure_Idle_Req 0;
BA_ "GenSigTimeoutTime_DMSM" SG_ 145 Secure_Idle_Req 0;
BA_ "GenSigTimeoutTime_DTCM" SG_ 145 Secure_Idle_Req 0;
BA_ "GenSigTimeoutTime_ECM" SG_ 145 Secure_Idle_Req 0;
BA_ "GenSigTimeoutTime_GNMM" SG_ 145 Secure_Idle_Req 0;
BA_ "GenSigTimeoutTime_HCP" SG_ 145 Secure_Idle_Req 0;
BA_ "GenSigTimeoutTime_IPC" SG_ 145 Secure_Idle_Req 0;
BA_ "GenSigTimeoutTime_RFHM" SG_ 145 Secure_Idle_Req 0;
BA_ "GenSigTimeoutTime_SGW" SG_ 145 Secure_Idle_Req 0;
BA_ "GenSigStartValue" SG_ 145 SignatureLightingEnable_Req 1;
BA_ "GenSigSendType" SG_ 145 SignatureLightingEnable_Req 3;
BA_ "GenSigTimeoutTime_AGSM" SG_ 145 SignatureLightingEnable_Req 0;
BA_ "GenSigTimeoutTime_BCM" SG_ 145 SignatureLightingEnable_Req 0;
BA_ "GenSigTimeoutTime_BSM" SG_ 145 SignatureLightingEnable_Req 0;
BA_ "GenSigTimeoutTime_CADM" SG_ 145 SignatureLightingEnable_Req 0;
BA_ "GenSigTimeoutTime_DMSM" SG_ 145 SignatureLightingEnable_Req 0;
BA_ "GenSigTimeoutTime_DTCM" SG_ 145 SignatureLightingEnable_Req 0;
BA_ "GenSigTimeoutTime_ECM" SG_ 145 SignatureLightingEnable_Req 0;
BA_ "GenSigTimeoutTime_EVCU2" SG_ 145 SignatureLightingEnable_Req 0;
BA_ "GenSigTimeoutTime_GNMM" SG_ 145 SignatureLightingEnable_Req 0;
BA_ "GenSigTimeoutTime_HCP" SG_ 145 SignatureLightingEnable_Req 0;
BA_ "GenSigTimeoutTime_RFHM" SG_ 145 SignatureLightingEnable_Req 0;
BA_ "GenSigTimeoutTime_SGW" SG_ 145 SignatureLightingEnable_Req 0;
BA_ "GenSigTimeoutTime_TCM" SG_ 145 SignatureLightingEnable_Req 0;
BA_ "GenSigSendType" SG_ 1428 CM_TCH_STAT 3;
BA_ "GenSigTimeoutTime_AGSM" SG_ 1428 CM_TCH_STAT 0;
BA_ "GenSigTimeoutTime_BSM" SG_ 1428 CM_TCH_STAT 0;
BA_ "GenSigTimeoutTime_CADM" SG_ 1428 CM_TCH_STAT 0;
BA_ "GenSigTimeoutTime_DMSM" SG_ 1428 CM_TCH_STAT 0;
BA_ "GenSigTimeoutTime_DTCM" SG_ 1428 CM_TCH_STAT 0;
BA_ "GenSigTimeoutTime_ECM" SG_ 1428 CM_TCH_STAT 0;
BA_ "GenSigTimeoutTime_EVCU2" SG_ 1428 CM_TCH_STAT 0;
BA_ "GenSigTimeoutTime_GNMM" SG_ 1428 CM_TCH_STAT 0;
BA_ "GenSigTimeoutTime_HCP" SG_ 1428 CM_TCH_STAT 0;
BA_ "GenSigTimeoutTime_IPC" SG_ 1428 CM_TCH_STAT 0;
BA_ "GenSigTimeoutTime_RFHM" SG_ 1428 CM_TCH_STAT 0;
BA_ "GenSigTimeoutTime_SGW" SG_ 1428 CM_TCH_STAT 0;
BA_ "GenSigTimeoutTime_TCM" SG_ 1428 CM_TCH_STAT 0;
BA_ "GenSigSendType" SG_ 1428 CM_TCH_X_COORD 3;
BA_ "GenSigTimeoutTime_AGSM" SG_ 1428 CM_TCH_X_COORD 0;
BA_ "GenSigTimeoutTime_BSM" SG_ 1428 CM_TCH_X_COORD 0;
BA_ "GenSigTimeoutTime_CADM" SG_ 1428 CM_TCH_X_COORD 0;
BA_ "GenSigTimeoutTime_DMSM" SG_ 1428 CM_TCH_X_COORD 0;
BA_ "GenSigTimeoutTime_DTCM" SG_ 1428 CM_TCH_X_COORD 0;
BA_ "GenSigTimeoutTime_ECM" SG_ 1428 CM_TCH_X_COORD 0;
BA_ "GenSigTimeoutTime_EVCU2" SG_ 1428 CM_TCH_X_COORD 0;
BA_ "GenSigTimeoutTime_GNMM" SG_ 1428 CM_TCH_X_COORD 0;
BA_ "GenSigTimeoutTime_HCP" SG_ 1428 CM_TCH_X_COORD 0;
BA_ "GenSigTimeoutTime_IPC" SG_ 1428 CM_TCH_X_COORD 0;
BA_ "GenSigTimeoutTime_RFHM" SG_ 1428 CM_TCH_X_COORD 0;
BA_ "GenSigTimeoutTime_SGW" SG_ 1428 CM_TCH_X_COORD 0;
BA_ "GenSigTimeoutTime_TCM" SG_ 1428 CM_TCH_X_COORD 0;
BA_ "GenSigSendType" SG_ 1428 CM_TCH_Y_COORD 3;
BA_ "GenSigTimeoutTime_AGSM" SG_ 1428 CM_TCH_Y_COORD 0;
BA_ "GenSigTimeoutTime_BSM" SG_ 1428 CM_TCH_Y_COORD 0;
BA_ "GenSigTimeoutTime_CADM" SG_ 1428 CM_TCH_Y_COORD 0;
BA_ "GenSigTimeoutTime_DMSM" SG_ 1428 CM_TCH_Y_COORD 0;
BA_ "GenSigTimeoutTime_DTCM" SG_ 1428 CM_TCH_Y_COORD 0;
BA_ "GenSigTimeoutTime_ECM" SG_ 1428 CM_TCH_Y_COORD 0;
BA_ "GenSigTimeoutTime_EVCU2" SG_ 1428 CM_TCH_Y_COORD 0;
BA_ "GenSigTimeoutTime_GNMM" SG_ 1428 CM_TCH_Y_COORD 0;
BA_ "GenSigTimeoutTime_HCP" SG_ 1428 CM_TCH_Y_COORD 0;
BA_ "GenSigTimeoutTime_IPC" SG_ 1428 CM_TCH_Y_COORD 0;
BA_ "GenSigTimeoutTime_RFHM" SG_ 1428 CM_TCH_Y_COORD 0;
BA_ "GenSigTimeoutTime_SGW" SG_ 1428 CM_TCH_Y_COORD 0;
BA_ "GenSigTimeoutTime_TCM" SG_ 1428 CM_TCH_Y_COORD 0;
BA_ "GenSigSendType" SG_ 1428 DIST_TO_TURN 3;
BA_ "GenSigTimeoutTime_AGSM" SG_ 1428 DIST_TO_TURN 0;
BA_ "GenSigTimeoutTime_BCM" SG_ 1428 DIST_TO_TURN 0;
BA_ "GenSigTimeoutTime_BSM" SG_ 1428 DIST_TO_TURN 0;
BA_ "GenSigTimeoutTime_DMSM" SG_ 1428 DIST_TO_TURN 0;
BA_ "GenSigTimeoutTime_DTCM" SG_ 1428 DIST_TO_TURN 0;
BA_ "GenSigTimeoutTime_ECM" SG_ 1428 DIST_TO_TURN 0;
BA_ "GenSigTimeoutTime_EVCU2" SG_ 1428 DIST_TO_TURN 0;
BA_ "GenSigTimeoutTime_GNMM" SG_ 1428 DIST_TO_TURN 0;
BA_ "GenSigTimeoutTime_HCP" SG_ 1428 DIST_TO_TURN 0;
BA_ "GenSigTimeoutTime_RFHM" SG_ 1428 DIST_TO_TURN 0;
BA_ "GenSigTimeoutTime_SGW" SG_ 1428 DIST_TO_TURN 0;
BA_ "GenSigTimeoutTime_TCM" SG_ 1428 DIST_TO_TURN 0;
BA_ "GenSigStartValue" SG_ 1428 ESC_Sft_btn_status 4;
BA_ "GenSigSendType" SG_ 1428 ESC_Sft_btn_status 3;
BA_ "GenSigTimeoutTime_AGSM" SG_ 1428 ESC_Sft_btn_status 0;
BA_ "GenSigTimeoutTime_BSM" SG_ 1428 ESC_Sft_btn_status 0;
BA_ "GenSigTimeoutTime_CADM" SG_ 1428 ESC_Sft_btn_status 0;
BA_ "GenSigTimeoutTime_DMSM" SG_ 1428 ESC_Sft_btn_status 0;
BA_ "GenSigTimeoutTime_DTCM" SG_ 1428 ESC_Sft_btn_status 0;
BA_ "GenSigTimeoutTime_ECM" SG_ 1428 ESC_Sft_btn_status 0;
BA_ "GenSigTimeoutTime_EVCU2" SG_ 1428 ESC_Sft_btn_status 0;
BA_ "GenSigTimeoutTime_GNMM" SG_ 1428 ESC_Sft_btn_status 0;
BA_ "GenSigTimeoutTime_HCP" SG_ 1428 ESC_Sft_btn_status 0;
BA_ "GenSigTimeoutTime_IPC" SG_ 1428 ESC_Sft_btn_status 0;
BA_ "GenSigTimeoutTime_RFHM" SG_ 1428 ESC_Sft_btn_status 0;
BA_ "GenSigTimeoutTime_SGW" SG_ 1428 ESC_Sft_btn_status 0;
BA_ "GenSigTimeoutTime_TCM" SG_ 1428 ESC_Sft_btn_status 0;
BA_ "GenSigStartValue" SG_ 1428 HU_CMP 15;
BA_ "GenSigSendType" SG_ 1428 HU_CMP 3;
BA_ "GenSigTimeoutTime_AGSM" SG_ 1428 HU_CMP 0;
BA_ "GenSigTimeoutTime_BSM" SG_ 1428 HU_CMP 0;
BA_ "GenSigTimeoutTime_CADM" SG_ 1428 HU_CMP 0;
BA_ "GenSigTimeoutTime_DMSM" SG_ 1428 HU_CMP 0;
BA_ "GenSigTimeoutTime_DTCM" SG_ 1428 HU_CMP 0;
BA_ "GenSigTimeoutTime_ECM" SG_ 1428 HU_CMP 0;
BA_ "GenSigTimeoutTime_EVCU2" SG_ 1428 HU_CMP 0;
BA_ "GenSigTimeoutTime_GNMM" SG_ 1428 HU_CMP 0;
BA_ "GenSigTimeoutTime_HCP" SG_ 1428 HU_CMP 0;
BA_ "GenSigTimeoutTime_IPC" SG_ 1428 HU_CMP 0;
BA_ "GenSigTimeoutTime_RFHM" SG_ 1428 HU_CMP 0;
BA_ "GenSigTimeoutTime_SGW" SG_ 1428 HU_CMP 0;
BA_ "GenSigTimeoutTime_TCM" SG_ 1428 HU_CMP 0;
BA_ "GenSigSendType" SG_ 1428 NAV_ARROW 3;
BA_ "GenSigTimeoutTime_AGSM" SG_ 1428 NAV_ARROW 0;
BA_ "GenSigTimeoutTime_BCM" SG_ 1428 NAV_ARROW 0;
BA_ "GenSigTimeoutTime_BSM" SG_ 1428 NAV_ARROW 0;
BA_ "GenSigTimeoutTime_DMSM" SG_ 1428 NAV_ARROW 0;
BA_ "GenSigTimeoutTime_DTCM" SG_ 1428 NAV_ARROW 0;
BA_ "GenSigTimeoutTime_ECM" SG_ 1428 NAV_ARROW 0;
BA_ "GenSigTimeoutTime_EVCU2" SG_ 1428 NAV_ARROW 0;
BA_ "GenSigTimeoutTime_GNMM" SG_ 1428 NAV_ARROW 0;
BA_ "GenSigTimeoutTime_HCP" SG_ 1428 NAV_ARROW 0;
BA_ "GenSigTimeoutTime_RFHM" SG_ 1428 NAV_ARROW 0;
BA_ "GenSigTimeoutTime_SGW" SG_ 1428 NAV_ARROW 0;
BA_ "GenSigTimeoutTime_TCM" SG_ 1428 NAV_ARROW 0;
BA_ "GenSigSendType" SG_ 1428 NAV_UNITS 3;
BA_ "GenSigTimeoutTime_AGSM" SG_ 1428 NAV_UNITS 0;
BA_ "GenSigTimeoutTime_BCM" SG_ 1428 NAV_UNITS 0;
BA_ "GenSigTimeoutTime_BSM" SG_ 1428 NAV_UNITS 0;
BA_ "GenSigTimeoutTime_CADM" SG_ 1428 NAV_UNITS 0;
BA_ "GenSigTimeoutTime_DMSM" SG_ 1428 NAV_UNITS 0;
BA_ "GenSigTimeoutTime_DTCM" SG_ 1428 NAV_UNITS 0;
BA_ "GenSigTimeoutTime_ECM" SG_ 1428 NAV_UNITS 0;
BA_ "GenSigTimeoutTime_EVCU2" SG_ 1428 NAV_UNITS 0;
BA_ "GenSigTimeoutTime_GNMM" SG_ 1428 NAV_UNITS 0;
BA_ "GenSigTimeoutTime_HCP" SG_ 1428 NAV_UNITS 0;
BA_ "GenSigTimeoutTime_RFHM" SG_ 1428 NAV_UNITS 0;
BA_ "GenSigTimeoutTime_SGW" SG_ 1428 NAV_UNITS 0;
BA_ "GenSigTimeoutTime_TCM" SG_ 1428 NAV_UNITS 0;
BA_ "GenSigSendType" SG_ 1428 NAVPrsnt 3;
BA_ "GenSigTimeoutTime_AGSM" SG_ 1428 NAVPrsnt 0;
BA_ "GenSigTimeoutTime_BCM" SG_ 1428 NAVPrsnt 0;
BA_ "GenSigTimeoutTime_BSM" SG_ 1428 NAVPrsnt 0;
BA_ "GenSigTimeoutTime_CADM" SG_ 1428 NAVPrsnt 0;
BA_ "GenSigTimeoutTime_DMSM" SG_ 1428 NAVPrsnt 0;
BA_ "GenSigTimeoutTime_DTCM" SG_ 1428 NAVPrsnt 0;
BA_ "GenSigTimeoutTime_ECM" SG_ 1428 NAVPrsnt 0;
BA_ "GenSigTimeoutTime_EVCU2" SG_ 1428 NAVPrsnt 0;
BA_ "GenSigTimeoutTime_GNMM" SG_ 1428 NAVPrsnt 0;
BA_ "GenSigTimeoutTime_HCP" SG_ 1428 NAVPrsnt 0;
BA_ "GenSigTimeoutTime_RFHM" SG_ 1428 NAVPrsnt 0;
BA_ "GenSigTimeoutTime_SGW" SG_ 1428 NAVPrsnt 0;
BA_ "GenSigTimeoutTime_TCM" SG_ 1428 NAVPrsnt 0;
BA_ "GenSigSendType" SG_ 1428 T_BY_T_ON 3;
BA_ "GenSigTimeoutTime_AGSM" SG_ 1428 T_BY_T_ON 0;
BA_ "GenSigTimeoutTime_BCM" SG_ 1428 T_BY_T_ON 0;
BA_ "GenSigTimeoutTime_BSM" SG_ 1428 T_BY_T_ON 0;
BA_ "GenSigTimeoutTime_DMSM" SG_ 1428 T_BY_T_ON 0;
BA_ "GenSigTimeoutTime_DTCM" SG_ 1428 T_BY_T_ON 0;
BA_ "GenSigTimeoutTime_ECM" SG_ 1428 T_BY_T_ON 0;
BA_ "GenSigTimeoutTime_EVCU2" SG_ 1428 T_BY_T_ON 0;
BA_ "GenSigTimeoutTime_GNMM" SG_ 1428 T_BY_T_ON 0;
BA_ "GenSigTimeoutTime_HCP" SG_ 1428 T_BY_T_ON 0;
BA_ "GenSigTimeoutTime_RFHM" SG_ 1428 T_BY_T_ON 0;
BA_ "GenSigTimeoutTime_SGW" SG_ 1428 T_BY_T_ON 0;
BA_ "GenSigTimeoutTime_TCM" SG_ 1428 T_BY_T_ON 0;
BA_ "GenSigSendType" SG_ 1428 TURN_COMP 3;
BA_ "GenSigTimeoutTime_AGSM" SG_ 1428 TURN_COMP 0;
BA_ "GenSigTimeoutTime_BCM" SG_ 1428 TURN_COMP 0;
BA_ "GenSigTimeoutTime_BSM" SG_ 1428 TURN_COMP 0;
BA_ "GenSigTimeoutTime_DMSM" SG_ 1428 TURN_COMP 0;
BA_ "GenSigTimeoutTime_DTCM" SG_ 1428 TURN_COMP 0;
BA_ "GenSigTimeoutTime_ECM" SG_ 1428 TURN_COMP 0;
BA_ "GenSigTimeoutTime_EVCU2" SG_ 1428 TURN_COMP 0;
BA_ "GenSigTimeoutTime_GNMM" SG_ 1428 TURN_COMP 0;
BA_ "GenSigTimeoutTime_HCP" SG_ 1428 TURN_COMP 0;
BA_ "GenSigTimeoutTime_RFHM" SG_ 1428 TURN_COMP 0;
BA_ "GenSigTimeoutTime_SGW" SG_ 1428 TURN_COMP 0;
BA_ "GenSigTimeoutTime_TCM" SG_ 1428 TURN_COMP 0;
BA_ "GenSigStartValue" SG_ 1428 WorksiteINVM_Audible_LFW_Req 1;
BA_ "GenSigSendType" SG_ 1428 WorksiteINVM_Audible_LFW_Req 4;
BA_ "GenSigTimeoutTime_AGSM" SG_ 1428 WorksiteINVM_Audible_LFW_Req 0;
BA_ "GenSigTimeoutTime_BCM" SG_ 1428 WorksiteINVM_Audible_LFW_Req 0;
BA_ "GenSigTimeoutTime_BSM" SG_ 1428 WorksiteINVM_Audible_LFW_Req 0;
BA_ "GenSigTimeoutTime_CADM" SG_ 1428 WorksiteINVM_Audible_LFW_Req 0;
BA_ "GenSigTimeoutTime_DMSM" SG_ 1428 WorksiteINVM_Audible_LFW_Req 0;
BA_ "GenSigTimeoutTime_DTCM" SG_ 1428 WorksiteINVM_Audible_LFW_Req 0;
BA_ "GenSigTimeoutTime_ECM" SG_ 1428 WorksiteINVM_Audible_LFW_Req 0;
BA_ "GenSigTimeoutTime_EVCU2" SG_ 1428 WorksiteINVM_Audible_LFW_Req 0;
BA_ "GenSigTimeoutTime_GNMM" SG_ 1428 WorksiteINVM_Audible_LFW_Req 0;
BA_ "GenSigTimeoutTime_HCP" SG_ 1428 WorksiteINVM_Audible_LFW_Req 0;
BA_ "GenSigTimeoutTime_RFHM" SG_ 1428 WorksiteINVM_Audible_LFW_Req 0;
BA_ "GenSigTimeoutTime_SGW" SG_ 1428 WorksiteINVM_Audible_LFW_Req 0;
BA_ "GenSigTimeoutTime_TCM" SG_ 1428 WorksiteINVM_Audible_LFW_Req 0;
BA_ "GenSigStartValue" SG_ 1428 WorksiteINVM_Visual_LFW_Req 1;
BA_ "GenSigSendType" SG_ 1428 WorksiteINVM_Visual_LFW_Req 4;
BA_ "GenSigTimeoutTime_AGSM" SG_ 1428 WorksiteINVM_Visual_LFW_Req 0;
BA_ "GenSigTimeoutTime_BCM" SG_ 1428 WorksiteINVM_Visual_LFW_Req 0;
BA_ "GenSigTimeoutTime_BSM" SG_ 1428 WorksiteINVM_Visual_LFW_Req 0;
BA_ "GenSigTimeoutTime_CADM" SG_ 1428 WorksiteINVM_Visual_LFW_Req 0;
BA_ "GenSigTimeoutTime_DMSM" SG_ 1428 WorksiteINVM_Visual_LFW_Req 0;
BA_ "GenSigTimeoutTime_DTCM" SG_ 1428 WorksiteINVM_Visual_LFW_Req 0;
BA_ "GenSigTimeoutTime_ECM" SG_ 1428 WorksiteINVM_Visual_LFW_Req 0;
BA_ "GenSigTimeoutTime_EVCU2" SG_ 1428 WorksiteINVM_Visual_LFW_Req 0;
BA_ "GenSigTimeoutTime_GNMM" SG_ 1428 WorksiteINVM_Visual_LFW_Req 0;
BA_ "GenSigTimeoutTime_HCP" SG_ 1428 WorksiteINVM_Visual_LFW_Req 0;
BA_ "GenSigTimeoutTime_RFHM" SG_ 1428 WorksiteINVM_Visual_LFW_Req 0;
BA_ "GenSigTimeoutTime_SGW" SG_ 1428 WorksiteINVM_Visual_LFW_Req 0;
BA_ "GenSigTimeoutTime_TCM" SG_ 1428 WorksiteINVM_Visual_LFW_Req 0;
BA_ "GenSigStartValue" SG_ 956 Power_Tailgate_Enable_Req 1;
BA_ "GenSigSendType" SG_ 956 Power_Tailgate_Enable_Req 4;
BA_ "GenSigTimeoutTime_AGSM" SG_ 956 Power_Tailgate_Enable_Req 0;
BA_ "GenSigTimeoutTime_BCM" SG_ 956 Power_Tailgate_Enable_Req 0;
BA_ "GenSigTimeoutTime_BSM" SG_ 956 Power_Tailgate_Enable_Req 0;
BA_ "GenSigTimeoutTime_CADM" SG_ 956 Power_Tailgate_Enable_Req 0;
BA_ "GenSigTimeoutTime_DMSM" SG_ 956 Power_Tailgate_Enable_Req 0;
BA_ "GenSigTimeoutTime_DTCM" SG_ 956 Power_Tailgate_Enable_Req 0;
BA_ "GenSigTimeoutTime_ECM" SG_ 956 Power_Tailgate_Enable_Req 0;
BA_ "GenSigTimeoutTime_EVCU2" SG_ 956 Power_Tailgate_Enable_Req 0;
BA_ "GenSigTimeoutTime_GNMM" SG_ 956 Power_Tailgate_Enable_Req 0;
BA_ "GenSigTimeoutTime_HCP" SG_ 956 Power_Tailgate_Enable_Req 0;
BA_ "GenSigTimeoutTime_RFHM" SG_ 956 Power_Tailgate_Enable_Req 0;
BA_ "GenSigTimeoutTime_SGW" SG_ 956 Power_Tailgate_Enable_Req 0;
BA_ "GenSigTimeoutTime_TCM" SG_ 956 Power_Tailgate_Enable_Req 0;
BA_ "GenSigSendType" SG_ 956 Rear_Guidance_Light_Status_Req 4;
BA_ "GenSigTimeoutTime_AGSM" SG_ 956 Rear_Guidance_Light_Status_Req 0;
BA_ "GenSigTimeoutTime_BCM" SG_ 956 Rear_Guidance_Light_Status_Req 0;
BA_ "GenSigTimeoutTime_BSM" SG_ 956 Rear_Guidance_Light_Status_Req 0;
BA_ "GenSigTimeoutTime_CADM" SG_ 956 Rear_Guidance_Light_Status_Req 0;
BA_ "GenSigTimeoutTime_DMSM" SG_ 956 Rear_Guidance_Light_Status_Req 0;
BA_ "GenSigTimeoutTime_DTCM" SG_ 956 Rear_Guidance_Light_Status_Req 0;
BA_ "GenSigTimeoutTime_ECM" SG_ 956 Rear_Guidance_Light_Status_Req 0;
BA_ "GenSigTimeoutTime_EVCU2" SG_ 956 Rear_Guidance_Light_Status_Req 0;
BA_ "GenSigTimeoutTime_GNMM" SG_ 956 Rear_Guidance_Light_Status_Req 0;
BA_ "GenSigTimeoutTime_HCP" SG_ 956 Rear_Guidance_Light_Status_Req 0;
BA_ "GenSigTimeoutTime_RFHM" SG_ 956 Rear_Guidance_Light_Status_Req 0;
BA_ "GenSigTimeoutTime_SGW" SG_ 956 Rear_Guidance_Light_Status_Req 0;
BA_ "GenSigTimeoutTime_TCM" SG_ 956 Rear_Guidance_Light_Status_Req 0;
BA_ "GenSigSendType" SG_ 956 Rear_Lights_with_Approach_Req 4;
BA_ "GenSigTimeoutTime_AGSM" SG_ 956 Rear_Lights_with_Approach_Req 0;
BA_ "GenSigTimeoutTime_BCM" SG_ 956 Rear_Lights_with_Approach_Req 0;
BA_ "GenSigTimeoutTime_BSM" SG_ 956 Rear_Lights_with_Approach_Req 0;
BA_ "GenSigTimeoutTime_CADM" SG_ 956 Rear_Lights_with_Approach_Req 0;
BA_ "GenSigTimeoutTime_DMSM" SG_ 956 Rear_Lights_with_Approach_Req 0;
BA_ "GenSigTimeoutTime_DTCM" SG_ 956 Rear_Lights_with_Approach_Req 0;
BA_ "GenSigTimeoutTime_ECM" SG_ 956 Rear_Lights_with_Approach_Req 0;
BA_ "GenSigTimeoutTime_EVCU2" SG_ 956 Rear_Lights_with_Approach_Req 0;
BA_ "GenSigTimeoutTime_GNMM" SG_ 956 Rear_Lights_with_Approach_Req 0;
BA_ "GenSigTimeoutTime_HCP" SG_ 956 Rear_Lights_with_Approach_Req 0;
BA_ "GenSigTimeoutTime_RFHM" SG_ 956 Rear_Lights_with_Approach_Req 0;
BA_ "GenSigTimeoutTime_SGW" SG_ 956 Rear_Lights_with_Approach_Req 0;
BA_ "GenSigTimeoutTime_TCM" SG_ 956 Rear_Lights_with_Approach_Req 0;
BA_ "GenSigStartValue" SG_ 1832 GPS_Lat 4294967295;
BA_ "GenSigTimeoutTime_AGSM" SG_ 1832 GPS_Lat 0;
BA_ "GenSigTimeoutTime_BCM" SG_ 1832 GPS_Lat 0;
BA_ "GenSigTimeoutTime_BSM" SG_ 1832 GPS_Lat 0;
BA_ "GenSigTimeoutTime_DMSM" SG_ 1832 GPS_Lat 0;
BA_ "GenSigTimeoutTime_DTCM" SG_ 1832 GPS_Lat 0;
BA_ "GenSigTimeoutTime_ECM" SG_ 1832 GPS_Lat 0;
BA_ "GenSigTimeoutTime_EVCU2" SG_ 1832 GPS_Lat 0;
BA_ "GenSigTimeoutTime_GNMM" SG_ 1832 GPS_Lat 0;
BA_ "GenSigTimeoutTime_HCP" SG_ 1832 GPS_Lat 0;
BA_ "GenSigTimeoutTime_RFHM" SG_ 1832 GPS_Lat 0;
BA_ "GenSigTimeoutTime_SGW" SG_ 1832 GPS_Lat 0;
BA_ "GenSigTimeoutTime_TCM" SG_ 1832 GPS_Lat 0;
BA_ "GenSigStartValue" SG_ 1832 GPS_Long 4294967295;
BA_ "GenSigTimeoutTime_AGSM" SG_ 1832 GPS_Long 0;
BA_ "GenSigTimeoutTime_BCM" SG_ 1832 GPS_Long 0;
BA_ "GenSigTimeoutTime_BSM" SG_ 1832 GPS_Long 0;
BA_ "GenSigTimeoutTime_DMSM" SG_ 1832 GPS_Long 0;
BA_ "GenSigTimeoutTime_DTCM" SG_ 1832 GPS_Long 0;
BA_ "GenSigTimeoutTime_ECM" SG_ 1832 GPS_Long 0;
BA_ "GenSigTimeoutTime_EVCU2" SG_ 1832 GPS_Long 0;
BA_ "GenSigTimeoutTime_GNMM" SG_ 1832 GPS_Long 0;
BA_ "GenSigTimeoutTime_HCP" SG_ 1832 GPS_Long 0;
BA_ "GenSigTimeoutTime_RFHM" SG_ 1832 GPS_Long 0;
BA_ "GenSigTimeoutTime_SGW" SG_ 1832 GPS_Long 0;
BA_ "GenSigTimeoutTime_TCM" SG_ 1832 GPS_Long 0;
BA_ "GenSigSendType" SG_ 158 Act_Lane_Mgt_Req 3;
BA_ "GenSigTimeoutTime_AGSM" SG_ 158 Act_Lane_Mgt_Req 0;
BA_ "GenSigTimeoutTime_BCM" SG_ 158 Act_Lane_Mgt_Req 0;
BA_ "GenSigTimeoutTime_BSM" SG_ 158 Act_Lane_Mgt_Req 0;
BA_ "GenSigTimeoutTime_CADM" SG_ 158 Act_Lane_Mgt_Req 0;
BA_ "GenSigTimeoutTime_DMSM" SG_ 158 Act_Lane_Mgt_Req 0;
BA_ "GenSigTimeoutTime_DTCM" SG_ 158 Act_Lane_Mgt_Req 0;
BA_ "GenSigTimeoutTime_ECM" SG_ 158 Act_Lane_Mgt_Req 0;
BA_ "GenSigTimeoutTime_EVCU2" SG_ 158 Act_Lane_Mgt_Req 0;
BA_ "GenSigTimeoutTime_GNMM" SG_ 158 Act_Lane_Mgt_Req 0;
BA_ "GenSigTimeoutTime_HCP" SG_ 158 Act_Lane_Mgt_Req 0;
BA_ "GenSigTimeoutTime_RFHM" SG_ 158 Act_Lane_Mgt_Req 0;
BA_ "GenSigTimeoutTime_SGW" SG_ 158 Act_Lane_Mgt_Req 0;
BA_ "GenSigTimeoutTime_TCM" SG_ 158 Act_Lane_Mgt_Req 0;
BA_ "GenSigSendType" SG_ 158 Act_Lane_Mgt_Strength_Req 3;
BA_ "GenSigTimeoutTime_AGSM" SG_ 158 Act_Lane_Mgt_Strength_Req 0;
BA_ "GenSigTimeoutTime_BCM" SG_ 158 Act_Lane_Mgt_Strength_Req 0;
BA_ "GenSigTimeoutTime_BSM" SG_ 158 Act_Lane_Mgt_Strength_Req 0;
BA_ "GenSigTimeoutTime_CADM" SG_ 158 Act_Lane_Mgt_Strength_Req 0;
BA_ "GenSigTimeoutTime_DMSM" SG_ 158 Act_Lane_Mgt_Strength_Req 0;
BA_ "GenSigTimeoutTime_DTCM" SG_ 158 Act_Lane_Mgt_Strength_Req 0;
BA_ "GenSigTimeoutTime_ECM" SG_ 158 Act_Lane_Mgt_Strength_Req 0;
BA_ "GenSigTimeoutTime_EVCU2" SG_ 158 Act_Lane_Mgt_Strength_Req 0;
BA_ "GenSigTimeoutTime_GNMM" SG_ 158 Act_Lane_Mgt_Strength_Req 0;
BA_ "GenSigTimeoutTime_HCP" SG_ 158 Act_Lane_Mgt_Strength_Req 0;
BA_ "GenSigTimeoutTime_RFHM" SG_ 158 Act_Lane_Mgt_Strength_Req 0;
BA_ "GenSigTimeoutTime_SGW" SG_ 158 Act_Lane_Mgt_Strength_Req 0;
BA_ "GenSigTimeoutTime_TCM" SG_ 158 Act_Lane_Mgt_Strength_Req 0;
BA_ "GenSigSendType" SG_ 158 Active_Park_Mode_Req 3;
BA_ "GenSigTimeoutTime_AGSM" SG_ 158 Active_Park_Mode_Req 0;
BA_ "GenSigTimeoutTime_BCM" SG_ 158 Active_Park_Mode_Req 0;
BA_ "GenSigTimeoutTime_BSM" SG_ 158 Active_Park_Mode_Req 0;
BA_ "GenSigTimeoutTime_CADM" SG_ 158 Active_Park_Mode_Req 0;
BA_ "GenSigTimeoutTime_DMSM" SG_ 158 Active_Park_Mode_Req 0;
BA_ "GenSigTimeoutTime_DTCM" SG_ 158 Active_Park_Mode_Req 0;
BA_ "GenSigTimeoutTime_ECM" SG_ 158 Active_Park_Mode_Req 0;
BA_ "GenSigTimeoutTime_EVCU2" SG_ 158 Active_Park_Mode_Req 0;
BA_ "GenSigTimeoutTime_GNMM" SG_ 158 Active_Park_Mode_Req 0;
BA_ "GenSigTimeoutTime_HCP" SG_ 158 Active_Park_Mode_Req 0;
BA_ "GenSigTimeoutTime_RFHM" SG_ 158 Active_Park_Mode_Req 0;
BA_ "GenSigTimeoutTime_SGW" SG_ 158 Active_Park_Mode_Req 0;
BA_ "GenSigTimeoutTime_TCM" SG_ 158 Active_Park_Mode_Req 0;
BA_ "GenSigSendType" SG_ 158 Active_Park_Prox_Chime_Req 3;
BA_ "GenSigTimeoutTime_AGSM" SG_ 158 Active_Park_Prox_Chime_Req 0;
BA_ "GenSigTimeoutTime_BCM" SG_ 158 Active_Park_Prox_Chime_Req 0;
BA_ "GenSigTimeoutTime_BSM" SG_ 158 Active_Park_Prox_Chime_Req 0;
BA_ "GenSigTimeoutTime_CADM" SG_ 158 Active_Park_Prox_Chime_Req 0;
BA_ "GenSigTimeoutTime_DMSM" SG_ 158 Active_Park_Prox_Chime_Req 0;
BA_ "GenSigTimeoutTime_DTCM" SG_ 158 Active_Park_Prox_Chime_Req 0;
BA_ "GenSigTimeoutTime_ECM" SG_ 158 Active_Park_Prox_Chime_Req 0;
BA_ "GenSigTimeoutTime_EVCU2" SG_ 158 Active_Park_Prox_Chime_Req 0;
BA_ "GenSigTimeoutTime_GNMM" SG_ 158 Active_Park_Prox_Chime_Req 0;
BA_ "GenSigTimeoutTime_HCP" SG_ 158 Active_Park_Prox_Chime_Req 0;
BA_ "GenSigTimeoutTime_RFHM" SG_ 158 Active_Park_Prox_Chime_Req 0;
BA_ "GenSigTimeoutTime_SGW" SG_ 158 Active_Park_Prox_Chime_Req 0;
BA_ "GenSigTimeoutTime_TCM" SG_ 158 Active_Park_Prox_Chime_Req 0;
BA_ "GenSigSendType" SG_ 158 Auto_Fold_Mirr_Req 3;
BA_ "GenSigTimeoutTime_AGSM" SG_ 158 Auto_Fold_Mirr_Req 0;
BA_ "GenSigTimeoutTime_BCM" SG_ 158 Auto_Fold_Mirr_Req 0;
BA_ "GenSigTimeoutTime_BSM" SG_ 158 Auto_Fold_Mirr_Req 0;
BA_ "GenSigTimeoutTime_CADM" SG_ 158 Auto_Fold_Mirr_Req 0;
BA_ "GenSigTimeoutTime_DMSM" SG_ 158 Auto_Fold_Mirr_Req 0;
BA_ "GenSigTimeoutTime_DTCM" SG_ 158 Auto_Fold_Mirr_Req 0;
BA_ "GenSigTimeoutTime_ECM" SG_ 158 Auto_Fold_Mirr_Req 0;
BA_ "GenSigTimeoutTime_EVCU2" SG_ 158 Auto_Fold_Mirr_Req 0;
BA_ "GenSigTimeoutTime_GNMM" SG_ 158 Auto_Fold_Mirr_Req 0;
BA_ "GenSigTimeoutTime_HCP" SG_ 158 Auto_Fold_Mirr_Req 0;
BA_ "GenSigTimeoutTime_RFHM" SG_ 158 Auto_Fold_Mirr_Req 0;
BA_ "GenSigTimeoutTime_SGW" SG_ 158 Auto_Fold_Mirr_Req 0;
BA_ "GenSigTimeoutTime_TCM" SG_ 158 Auto_Fold_Mirr_Req 0;
BA_ "GenSigStartValue" SG_ 158 Auto_Trailer_Light_Check_Req 1;
BA_ "GenSigSendType" SG_ 158 Auto_Trailer_Light_Check_Req 3;
BA_ "GenSigTimeoutTime_AGSM" SG_ 158 Auto_Trailer_Light_Check_Req 0;
BA_ "GenSigTimeoutTime_BCM" SG_ 158 Auto_Trailer_Light_Check_Req 0;
BA_ "GenSigTimeoutTime_BSM" SG_ 158 Auto_Trailer_Light_Check_Req 0;
BA_ "GenSigTimeoutTime_CADM" SG_ 158 Auto_Trailer_Light_Check_Req 0;
BA_ "GenSigTimeoutTime_DMSM" SG_ 158 Auto_Trailer_Light_Check_Req 0;
BA_ "GenSigTimeoutTime_DTCM" SG_ 158 Auto_Trailer_Light_Check_Req 0;
BA_ "GenSigTimeoutTime_ECM" SG_ 158 Auto_Trailer_Light_Check_Req 0;
BA_ "GenSigTimeoutTime_EVCU2" SG_ 158 Auto_Trailer_Light_Check_Req 0;
BA_ "GenSigTimeoutTime_GNMM" SG_ 158 Auto_Trailer_Light_Check_Req 0;
BA_ "GenSigTimeoutTime_HCP" SG_ 158 Auto_Trailer_Light_Check_Req 0;
BA_ "GenSigTimeoutTime_RFHM" SG_ 158 Auto_Trailer_Light_Check_Req 0;
BA_ "GenSigTimeoutTime_SGW" SG_ 158 Auto_Trailer_Light_Check_Req 0;
BA_ "GenSigTimeoutTime_TCM" SG_ 158 Auto_Trailer_Light_Check_Req 0;
BA_ "GenSigStartValue" SG_ 158 AutoHighBeamEnable_Req 1;
BA_ "GenSigSendType" SG_ 158 AutoHighBeamEnable_Req 1;
BA_ "GenSigTimeoutTime_AGSM" SG_ 158 AutoHighBeamEnable_Req 0;
BA_ "GenSigTimeoutTime_BCM" SG_ 158 AutoHighBeamEnable_Req 0;
BA_ "GenSigTimeoutTime_BSM" SG_ 158 AutoHighBeamEnable_Req 0;
BA_ "GenSigTimeoutTime_CADM" SG_ 158 AutoHighBeamEnable_Req 0;
BA_ "GenSigTimeoutTime_DMSM" SG_ 158 AutoHighBeamEnable_Req 0;
BA_ "GenSigTimeoutTime_DTCM" SG_ 158 AutoHighBeamEnable_Req 0;
BA_ "GenSigTimeoutTime_ECM" SG_ 158 AutoHighBeamEnable_Req 0;
BA_ "GenSigTimeoutTime_EVCU2" SG_ 158 AutoHighBeamEnable_Req 0;
BA_ "GenSigTimeoutTime_GNMM" SG_ 158 AutoHighBeamEnable_Req 0;
BA_ "GenSigTimeoutTime_HCP" SG_ 158 AutoHighBeamEnable_Req 0;
BA_ "GenSigTimeoutTime_RFHM" SG_ 158 AutoHighBeamEnable_Req 0;
BA_ "GenSigTimeoutTime_SGW" SG_ 158 AutoHighBeamEnable_Req 0;
BA_ "GenSigTimeoutTime_TCM" SG_ 158 AutoHighBeamEnable_Req 0;
BA_ "GenSigSendType" SG_ 158 AutoParkBrake_Req 1;
BA_ "GenSigTimeoutTime_AGSM" SG_ 158 AutoParkBrake_Req 0;
BA_ "GenSigTimeoutTime_BCM" SG_ 158 AutoParkBrake_Req 0;
BA_ "GenSigTimeoutTime_BSM" SG_ 158 AutoParkBrake_Req 0;
BA_ "GenSigTimeoutTime_CADM" SG_ 158 AutoParkBrake_Req 0;
BA_ "GenSigTimeoutTime_DMSM" SG_ 158 AutoParkBrake_Req 0;
BA_ "GenSigTimeoutTime_DTCM" SG_ 158 AutoParkBrake_Req 0;
BA_ "GenSigTimeoutTime_ECM" SG_ 158 AutoParkBrake_Req 0;
BA_ "GenSigTimeoutTime_EVCU2" SG_ 158 AutoParkBrake_Req 0;
BA_ "GenSigTimeoutTime_GNMM" SG_ 158 AutoParkBrake_Req 0;
BA_ "GenSigTimeoutTime_HCP" SG_ 158 AutoParkBrake_Req 0;
BA_ "GenSigTimeoutTime_RFHM" SG_ 158 AutoParkBrake_Req 0;
BA_ "GenSigTimeoutTime_SGW" SG_ 158 AutoParkBrake_Req 0;
BA_ "GenSigTimeoutTime_TCM" SG_ 158 AutoParkBrake_Req 0;
BA_ "GenSigStartValue" SG_ 158 AutoUnlockDoorExit_Req 1;
BA_ "GenSigSendType" SG_ 158 AutoUnlockDoorExit_Req 1;
BA_ "GenSigTimeoutTime_AGSM" SG_ 158 AutoUnlockDoorExit_Req 0;
BA_ "GenSigTimeoutTime_BCM" SG_ 158 AutoUnlockDoorExit_Req 0;
BA_ "GenSigTimeoutTime_BSM" SG_ 158 AutoUnlockDoorExit_Req 0;
BA_ "GenSigTimeoutTime_CADM" SG_ 158 AutoUnlockDoorExit_Req 0;
BA_ "GenSigTimeoutTime_DMSM" SG_ 158 AutoUnlockDoorExit_Req 0;
BA_ "GenSigTimeoutTime_DTCM" SG_ 158 AutoUnlockDoorExit_Req 0;
BA_ "GenSigTimeoutTime_ECM" SG_ 158 AutoUnlockDoorExit_Req 0;
BA_ "GenSigTimeoutTime_EVCU2" SG_ 158 AutoUnlockDoorExit_Req 0;
BA_ "GenSigTimeoutTime_GNMM" SG_ 158 AutoUnlockDoorExit_Req 0;
BA_ "GenSigTimeoutTime_HCP" SG_ 158 AutoUnlockDoorExit_Req 0;
BA_ "GenSigTimeoutTime_RFHM" SG_ 158 AutoUnlockDoorExit_Req 0;
BA_ "GenSigTimeoutTime_SGW" SG_ 158 AutoUnlockDoorExit_Req 0;
BA_ "GenSigTimeoutTime_TCM" SG_ 158 AutoUnlockDoorExit_Req 0;
BA_ "GenSigSendType" SG_ 158 Backup_Cam_Delay_Req 3;
BA_ "GenSigTimeoutTime_AGSM" SG_ 158 Backup_Cam_Delay_Req 0;
BA_ "GenSigTimeoutTime_BCM" SG_ 158 Backup_Cam_Delay_Req 0;
BA_ "GenSigTimeoutTime_BSM" SG_ 158 Backup_Cam_Delay_Req 0;
BA_ "GenSigTimeoutTime_CADM" SG_ 158 Backup_Cam_Delay_Req 0;
BA_ "GenSigTimeoutTime_DMSM" SG_ 158 Backup_Cam_Delay_Req 0;
BA_ "GenSigTimeoutTime_DTCM" SG_ 158 Backup_Cam_Delay_Req 0;
BA_ "GenSigTimeoutTime_ECM" SG_ 158 Backup_Cam_Delay_Req 0;
BA_ "GenSigTimeoutTime_EVCU2" SG_ 158 Backup_Cam_Delay_Req 0;
BA_ "GenSigTimeoutTime_GNMM" SG_ 158 Backup_Cam_Delay_Req 0;
BA_ "GenSigTimeoutTime_HCP" SG_ 158 Backup_Cam_Delay_Req 0;
BA_ "GenSigTimeoutTime_RFHM" SG_ 158 Backup_Cam_Delay_Req 0;
BA_ "GenSigTimeoutTime_SGW" SG_ 158 Backup_Cam_Delay_Req 0;
BA_ "GenSigTimeoutTime_TCM" SG_ 158 Backup_Cam_Delay_Req 0;
BA_ "GenSigStartValue" SG_ 158 BSDEnable_Req 2;
BA_ "GenSigSendType" SG_ 158 BSDEnable_Req 1;
BA_ "GenSigTimeoutTime_AGSM" SG_ 158 BSDEnable_Req 0;
BA_ "GenSigTimeoutTime_BCM" SG_ 158 BSDEnable_Req 0;
BA_ "GenSigTimeoutTime_BSM" SG_ 158 BSDEnable_Req 0;
BA_ "GenSigTimeoutTime_CADM" SG_ 158 BSDEnable_Req 0;
BA_ "GenSigTimeoutTime_DMSM" SG_ 158 BSDEnable_Req 0;
BA_ "GenSigTimeoutTime_DTCM" SG_ 158 BSDEnable_Req 0;
BA_ "GenSigTimeoutTime_ECM" SG_ 158 BSDEnable_Req 0;
BA_ "GenSigTimeoutTime_EVCU2" SG_ 158 BSDEnable_Req 0;
BA_ "GenSigTimeoutTime_GNMM" SG_ 158 BSDEnable_Req 0;
BA_ "GenSigTimeoutTime_HCP" SG_ 158 BSDEnable_Req 0;
BA_ "GenSigTimeoutTime_RFHM" SG_ 158 BSDEnable_Req 0;
BA_ "GenSigTimeoutTime_SGW" SG_ 158 BSDEnable_Req 0;
BA_ "GenSigTimeoutTime_TCM" SG_ 158 BSDEnable_Req 0;
BA_ "GenSigSendType" SG_ 158 Consum_Unit_Req 3;
BA_ "GenSigTimeoutTime_AGSM" SG_ 158 Consum_Unit_Req 0;
BA_ "GenSigTimeoutTime_BCM" SG_ 158 Consum_Unit_Req 0;
BA_ "GenSigTimeoutTime_BSM" SG_ 158 Consum_Unit_Req 0;
BA_ "GenSigTimeoutTime_CADM" SG_ 158 Consum_Unit_Req 0;
BA_ "GenSigTimeoutTime_DMSM" SG_ 158 Consum_Unit_Req 0;
BA_ "GenSigTimeoutTime_DTCM" SG_ 158 Consum_Unit_Req 0;
BA_ "GenSigTimeoutTime_ECM" SG_ 158 Consum_Unit_Req 0;
BA_ "GenSigTimeoutTime_EVCU2" SG_ 158 Consum_Unit_Req 0;
BA_ "GenSigTimeoutTime_GNMM" SG_ 158 Consum_Unit_Req 0;
BA_ "GenSigTimeoutTime_HCP" SG_ 158 Consum_Unit_Req 0;
BA_ "GenSigTimeoutTime_RFHM" SG_ 158 Consum_Unit_Req 0;
BA_ "GenSigTimeoutTime_SGW" SG_ 158 Consum_Unit_Req 0;
BA_ "GenSigTimeoutTime_TCM" SG_ 158 Consum_Unit_Req 0;
BA_ "GenSigSendType" SG_ 158 CorneringEnable_Req 1;
BA_ "GenSigTimeoutTime_AGSM" SG_ 158 CorneringEnable_Req 0;
BA_ "GenSigTimeoutTime_BCM" SG_ 158 CorneringEnable_Req 0;
BA_ "GenSigTimeoutTime_BSM" SG_ 158 CorneringEnable_Req 0;
BA_ "GenSigTimeoutTime_CADM" SG_ 158 CorneringEnable_Req 0;
BA_ "GenSigTimeoutTime_DMSM" SG_ 158 CorneringEnable_Req 0;
BA_ "GenSigTimeoutTime_DTCM" SG_ 158 CorneringEnable_Req 0;
BA_ "GenSigTimeoutTime_ECM" SG_ 158 CorneringEnable_Req 0;
BA_ "GenSigTimeoutTime_EVCU2" SG_ 158 CorneringEnable_Req 0;
BA_ "GenSigTimeoutTime_GNMM" SG_ 158 CorneringEnable_Req 0;
BA_ "GenSigTimeoutTime_HCP" SG_ 158 CorneringEnable_Req 0;
BA_ "GenSigTimeoutTime_RFHM" SG_ 158 CorneringEnable_Req 0;
BA_ "GenSigTimeoutTime_SGW" SG_ 158 CorneringEnable_Req 0;
BA_ "GenSigTimeoutTime_TCM" SG_ 158 CorneringEnable_Req 0;
BA_ "GenSigTimeoutTime_AGSM" SG_ 158 CRC_TVS1 0;
BA_ "GenSigTimeoutTime_BCM" SG_ 158 CRC_TVS1 0;
BA_ "GenSigTimeoutTime_BSM" SG_ 158 CRC_TVS1 0;
BA_ "GenSigTimeoutTime_DMSM" SG_ 158 CRC_TVS1 0;
BA_ "GenSigTimeoutTime_DTCM" SG_ 158 CRC_TVS1 0;
BA_ "GenSigTimeoutTime_ECM" SG_ 158 CRC_TVS1 0;
BA_ "GenSigTimeoutTime_EVCU2" SG_ 158 CRC_TVS1 0;
BA_ "GenSigTimeoutTime_GNMM" SG_ 158 CRC_TVS1 0;
BA_ "GenSigTimeoutTime_HCP" SG_ 158 CRC_TVS1 0;
BA_ "GenSigTimeoutTime_IPC" SG_ 158 CRC_TVS1 0;
BA_ "GenSigTimeoutTime_RFHM" SG_ 158 CRC_TVS1 0;
BA_ "GenSigTimeoutTime_SGW" SG_ 158 CRC_TVS1 0;
BA_ "GenSigTimeoutTime_TCM" SG_ 158 CRC_TVS1 0;
BA_ "GenSigSendType" SG_ 158 Dist_Unit_Req 3;
BA_ "GenSigTimeoutTime_AGSM" SG_ 158 Dist_Unit_Req 0;
BA_ "GenSigTimeoutTime_BCM" SG_ 158 Dist_Unit_Req 0;
BA_ "GenSigTimeoutTime_BSM" SG_ 158 Dist_Unit_Req 0;
BA_ "GenSigTimeoutTime_CADM" SG_ 158 Dist_Unit_Req 0;
BA_ "GenSigTimeoutTime_DMSM" SG_ 158 Dist_Unit_Req 0;
BA_ "GenSigTimeoutTime_DTCM" SG_ 158 Dist_Unit_Req 0;
BA_ "GenSigTimeoutTime_ECM" SG_ 158 Dist_Unit_Req 0;
BA_ "GenSigTimeoutTime_EVCU2" SG_ 158 Dist_Unit_Req 0;
BA_ "GenSigTimeoutTime_GNMM" SG_ 158 Dist_Unit_Req 0;
BA_ "GenSigTimeoutTime_HCP" SG_ 158 Dist_Unit_Req 0;
BA_ "GenSigTimeoutTime_RFHM" SG_ 158 Dist_Unit_Req 0;
BA_ "GenSigTimeoutTime_SGW" SG_ 158 Dist_Unit_Req 0;
BA_ "GenSigTimeoutTime_TCM" SG_ 158 Dist_Unit_Req 0;
BA_ "GenSigSendType" SG_ 158 DRLEnable_Req 1;
BA_ "GenSigTimeoutTime_AGSM" SG_ 158 DRLEnable_Req 0;
BA_ "GenSigTimeoutTime_BCM" SG_ 158 DRLEnable_Req 0;
BA_ "GenSigTimeoutTime_BSM" SG_ 158 DRLEnable_Req 0;
BA_ "GenSigTimeoutTime_CADM" SG_ 158 DRLEnable_Req 0;
BA_ "GenSigTimeoutTime_DMSM" SG_ 158 DRLEnable_Req 0;
BA_ "GenSigTimeoutTime_DTCM" SG_ 158 DRLEnable_Req 0;
BA_ "GenSigTimeoutTime_ECM" SG_ 158 DRLEnable_Req 0;
BA_ "GenSigTimeoutTime_EVCU2" SG_ 158 DRLEnable_Req 0;
BA_ "GenSigTimeoutTime_GNMM" SG_ 158 DRLEnable_Req 0;
BA_ "GenSigTimeoutTime_HCP" SG_ 158 DRLEnable_Req 0;
BA_ "GenSigTimeoutTime_RFHM" SG_ 158 DRLEnable_Req 0;
BA_ "GenSigTimeoutTime_SGW" SG_ 158 DRLEnable_Req 0;
BA_ "GenSigTimeoutTime_TCM" SG_ 158 DRLEnable_Req 0;
BA_ "GenSigSendType" SG_ 158 Drowsy_Driver_Alert_Req 3;
BA_ "GenSigTimeoutTime_AGSM" SG_ 158 Drowsy_Driver_Alert_Req 0;
BA_ "GenSigTimeoutTime_BCM" SG_ 158 Drowsy_Driver_Alert_Req 0;
BA_ "GenSigTimeoutTime_BSM" SG_ 158 Drowsy_Driver_Alert_Req 0;
BA_ "GenSigTimeoutTime_DMSM" SG_ 158 Drowsy_Driver_Alert_Req 0;
BA_ "GenSigTimeoutTime_DTCM" SG_ 158 Drowsy_Driver_Alert_Req 0;
BA_ "GenSigTimeoutTime_ECM" SG_ 158 Drowsy_Driver_Alert_Req 0;
BA_ "GenSigTimeoutTime_EVCU2" SG_ 158 Drowsy_Driver_Alert_Req 0;
BA_ "GenSigTimeoutTime_GNMM" SG_ 158 Drowsy_Driver_Alert_Req 0;
BA_ "GenSigTimeoutTime_HCP" SG_ 158 Drowsy_Driver_Alert_Req 0;
BA_ "GenSigTimeoutTime_RFHM" SG_ 158 Drowsy_Driver_Alert_Req 0;
BA_ "GenSigTimeoutTime_SGW" SG_ 158 Drowsy_Driver_Alert_Req 0;
BA_ "GenSigTimeoutTime_TCM" SG_ 158 Drowsy_Driver_Alert_Req 0;
BA_ "GenSigStartValue" SG_ 158 DynamicGrid_Req 1;
BA_ "GenSigSendType" SG_ 158 DynamicGrid_Req 1;
BA_ "GenSigTimeoutTime_AGSM" SG_ 158 DynamicGrid_Req 0;
BA_ "GenSigTimeoutTime_BCM" SG_ 158 DynamicGrid_Req 0;
BA_ "GenSigTimeoutTime_BSM" SG_ 158 DynamicGrid_Req 0;
BA_ "GenSigTimeoutTime_CADM" SG_ 158 DynamicGrid_Req 0;
BA_ "GenSigTimeoutTime_DMSM" SG_ 158 DynamicGrid_Req 0;
BA_ "GenSigTimeoutTime_DTCM" SG_ 158 DynamicGrid_Req 0;
BA_ "GenSigTimeoutTime_ECM" SG_ 158 DynamicGrid_Req 0;
BA_ "GenSigTimeoutTime_EVCU2" SG_ 158 DynamicGrid_Req 0;
BA_ "GenSigTimeoutTime_GNMM" SG_ 158 DynamicGrid_Req 0;
BA_ "GenSigTimeoutTime_HCP" SG_ 158 DynamicGrid_Req 0;
BA_ "GenSigTimeoutTime_RFHM" SG_ 158 DynamicGrid_Req 0;
BA_ "GenSigTimeoutTime_SGW" SG_ 158 DynamicGrid_Req 0;
BA_ "GenSigTimeoutTime_TCM" SG_ 158 DynamicGrid_Req 0;
BA_ "GenSigSendType" SG_ 158 Easy_Exit_D_Req 3;
BA_ "GenSigTimeoutTime_AGSM" SG_ 158 Easy_Exit_D_Req 0;
BA_ "GenSigTimeoutTime_BCM" SG_ 158 Easy_Exit_D_Req 0;
BA_ "GenSigTimeoutTime_BSM" SG_ 158 Easy_Exit_D_Req 0;
BA_ "GenSigTimeoutTime_CADM" SG_ 158 Easy_Exit_D_Req 0;
BA_ "GenSigTimeoutTime_DMSM" SG_ 158 Easy_Exit_D_Req 0;
BA_ "GenSigTimeoutTime_DTCM" SG_ 158 Easy_Exit_D_Req 0;
BA_ "GenSigTimeoutTime_ECM" SG_ 158 Easy_Exit_D_Req 0;
BA_ "GenSigTimeoutTime_EVCU2" SG_ 158 Easy_Exit_D_Req 0;
BA_ "GenSigTimeoutTime_GNMM" SG_ 158 Easy_Exit_D_Req 0;
BA_ "GenSigTimeoutTime_HCP" SG_ 158 Easy_Exit_D_Req 0;
BA_ "GenSigTimeoutTime_RFHM" SG_ 158 Easy_Exit_D_Req 0;
BA_ "GenSigTimeoutTime_SGW" SG_ 158 Easy_Exit_D_Req 0;
BA_ "GenSigTimeoutTime_TCM" SG_ 158 Easy_Exit_D_Req 0;
BA_ "GenSigSendType" SG_ 158 Eng_Off_Pwr_Delay_Req 3;
BA_ "GenSigTimeoutTime_AGSM" SG_ 158 Eng_Off_Pwr_Delay_Req 0;
BA_ "GenSigTimeoutTime_BCM" SG_ 158 Eng_Off_Pwr_Delay_Req 0;
BA_ "GenSigTimeoutTime_BSM" SG_ 158 Eng_Off_Pwr_Delay_Req 0;
BA_ "GenSigTimeoutTime_CADM" SG_ 158 Eng_Off_Pwr_Delay_Req 0;
BA_ "GenSigTimeoutTime_DMSM" SG_ 158 Eng_Off_Pwr_Delay_Req 0;
BA_ "GenSigTimeoutTime_DTCM" SG_ 158 Eng_Off_Pwr_Delay_Req 0;
BA_ "GenSigTimeoutTime_ECM" SG_ 158 Eng_Off_Pwr_Delay_Req 0;
BA_ "GenSigTimeoutTime_EVCU2" SG_ 158 Eng_Off_Pwr_Delay_Req 0;
BA_ "GenSigTimeoutTime_GNMM" SG_ 158 Eng_Off_Pwr_Delay_Req 0;
BA_ "GenSigTimeoutTime_HCP" SG_ 158 Eng_Off_Pwr_Delay_Req 0;
BA_ "GenSigTimeoutTime_RFHM" SG_ 158 Eng_Off_Pwr_Delay_Req 0;
BA_ "GenSigTimeoutTime_SGW" SG_ 158 Eng_Off_Pwr_Delay_Req 0;
BA_ "GenSigTimeoutTime_TCM" SG_ 158 Eng_Off_Pwr_Delay_Req 0;
BA_ "GenSigSendType" SG_ 158 EPB_MaintenanceMode_Req 1;
BA_ "GenSigTimeoutTime_AGSM" SG_ 158 EPB_MaintenanceMode_Req 0;
BA_ "GenSigTimeoutTime_BCM" SG_ 158 EPB_MaintenanceMode_Req 0;
BA_ "GenSigTimeoutTime_CADM" SG_ 158 EPB_MaintenanceMode_Req 0;
BA_ "GenSigTimeoutTime_DMSM" SG_ 158 EPB_MaintenanceMode_Req 0;
BA_ "GenSigTimeoutTime_DTCM" SG_ 158 EPB_MaintenanceMode_Req 0;
BA_ "GenSigTimeoutTime_ECM" SG_ 158 EPB_MaintenanceMode_Req 0;
BA_ "GenSigTimeoutTime_EVCU2" SG_ 158 EPB_MaintenanceMode_Req 0;
BA_ "GenSigTimeoutTime_GNMM" SG_ 158 EPB_MaintenanceMode_Req 0;
BA_ "GenSigTimeoutTime_HCP" SG_ 158 EPB_MaintenanceMode_Req 0;
BA_ "GenSigTimeoutTime_IPC" SG_ 158 EPB_MaintenanceMode_Req 0;
BA_ "GenSigTimeoutTime_RFHM" SG_ 158 EPB_MaintenanceMode_Req 0;
BA_ "GenSigTimeoutTime_SGW" SG_ 158 EPB_MaintenanceMode_Req 0;
BA_ "GenSigTimeoutTime_TCM" SG_ 158 EPB_MaintenanceMode_Req 0;
BA_ "GenSigStartValue" SG_ 158 FlashLightWLock_Req 1;
BA_ "GenSigSendType" SG_ 158 FlashLightWLock_Req 1;
BA_ "GenSigTimeoutTime_AGSM" SG_ 158 FlashLightWLock_Req 0;
BA_ "GenSigTimeoutTime_BCM" SG_ 158 FlashLightWLock_Req 0;
BA_ "GenSigTimeoutTime_BSM" SG_ 158 FlashLightWLock_Req 0;
BA_ "GenSigTimeoutTime_CADM" SG_ 158 FlashLightWLock_Req 0;
BA_ "GenSigTimeoutTime_DMSM" SG_ 158 FlashLightWLock_Req 0;
BA_ "GenSigTimeoutTime_DTCM" SG_ 158 FlashLightWLock_Req 0;
BA_ "GenSigTimeoutTime_ECM" SG_ 158 FlashLightWLock_Req 0;
BA_ "GenSigTimeoutTime_EVCU2" SG_ 158 FlashLightWLock_Req 0;
BA_ "GenSigTimeoutTime_GNMM" SG_ 158 FlashLightWLock_Req 0;
BA_ "GenSigTimeoutTime_HCP" SG_ 158 FlashLightWLock_Req 0;
BA_ "GenSigTimeoutTime_RFHM" SG_ 158 FlashLightWLock_Req 0;
BA_ "GenSigTimeoutTime_SGW" SG_ 158 FlashLightWLock_Req 0;
BA_ "GenSigTimeoutTime_TCM" SG_ 158 FlashLightWLock_Req 0;
BA_ "GenSigStartValue" SG_ 158 FOA_Alert_Type_Req 1;
BA_ "GenSigSendType" SG_ 158 FOA_Alert_Type_Req 3;
BA_ "GenSigTimeoutTime_AGSM" SG_ 158 FOA_Alert_Type_Req 0;
BA_ "GenSigTimeoutTime_BCM" SG_ 158 FOA_Alert_Type_Req 0;
BA_ "GenSigTimeoutTime_BSM" SG_ 158 FOA_Alert_Type_Req 0;
BA_ "GenSigTimeoutTime_CADM" SG_ 158 FOA_Alert_Type_Req 0;
BA_ "GenSigTimeoutTime_DMSM" SG_ 158 FOA_Alert_Type_Req 0;
BA_ "GenSigTimeoutTime_DTCM" SG_ 158 FOA_Alert_Type_Req 0;
BA_ "GenSigTimeoutTime_ECM" SG_ 158 FOA_Alert_Type_Req 0;
BA_ "GenSigTimeoutTime_EVCU2" SG_ 158 FOA_Alert_Type_Req 0;
BA_ "GenSigTimeoutTime_GNMM" SG_ 158 FOA_Alert_Type_Req 0;
BA_ "GenSigTimeoutTime_HCP" SG_ 158 FOA_Alert_Type_Req 0;
BA_ "GenSigTimeoutTime_RFHM" SG_ 158 FOA_Alert_Type_Req 0;
BA_ "GenSigTimeoutTime_SGW" SG_ 158 FOA_Alert_Type_Req 0;
BA_ "GenSigTimeoutTime_TCM" SG_ 158 FOA_Alert_Type_Req 0;
BA_ "GenSigStartValue" SG_ 158 FSFCWPlusActivationMode_Req 1;
BA_ "GenSigSendType" SG_ 158 FSFCWPlusActivationMode_Req 1;
BA_ "GenSigTimeoutTime_AGSM" SG_ 158 FSFCWPlusActivationMode_Req 0;
BA_ "GenSigTimeoutTime_BCM" SG_ 158 FSFCWPlusActivationMode_Req 0;
BA_ "GenSigTimeoutTime_BSM" SG_ 158 FSFCWPlusActivationMode_Req 0;
BA_ "GenSigTimeoutTime_DMSM" SG_ 158 FSFCWPlusActivationMode_Req 0;
BA_ "GenSigTimeoutTime_DTCM" SG_ 158 FSFCWPlusActivationMode_Req 0;
BA_ "GenSigTimeoutTime_ECM" SG_ 158 FSFCWPlusActivationMode_Req 0;
BA_ "GenSigTimeoutTime_EVCU2" SG_ 158 FSFCWPlusActivationMode_Req 0;
BA_ "GenSigTimeoutTime_GNMM" SG_ 158 FSFCWPlusActivationMode_Req 0;
BA_ "GenSigTimeoutTime_HCP" SG_ 158 FSFCWPlusActivationMode_Req 0;
BA_ "GenSigTimeoutTime_RFHM" SG_ 158 FSFCWPlusActivationMode_Req 0;
BA_ "GenSigTimeoutTime_SGW" SG_ 158 FSFCWPlusActivationMode_Req 0;
BA_ "GenSigTimeoutTime_TCM" SG_ 158 FSFCWPlusActivationMode_Req 0;
BA_ "GenSigStartValue" SG_ 158 FSFCWPlusSetting_Req 3;
BA_ "GenSigSendType" SG_ 158 FSFCWPlusSetting_Req 1;
BA_ "GenSigTimeoutTime_AGSM" SG_ 158 FSFCWPlusSetting_Req 0;
BA_ "GenSigTimeoutTime_BCM" SG_ 158 FSFCWPlusSetting_Req 0;
BA_ "GenSigTimeoutTime_BSM" SG_ 158 FSFCWPlusSetting_Req 0;
BA_ "GenSigTimeoutTime_DMSM" SG_ 158 FSFCWPlusSetting_Req 0;
BA_ "GenSigTimeoutTime_DTCM" SG_ 158 FSFCWPlusSetting_Req 0;
BA_ "GenSigTimeoutTime_ECM" SG_ 158 FSFCWPlusSetting_Req 0;
BA_ "GenSigTimeoutTime_EVCU2" SG_ 158 FSFCWPlusSetting_Req 0;
BA_ "GenSigTimeoutTime_GNMM" SG_ 158 FSFCWPlusSetting_Req 0;
BA_ "GenSigTimeoutTime_HCP" SG_ 158 FSFCWPlusSetting_Req 0;
BA_ "GenSigTimeoutTime_RFHM" SG_ 158 FSFCWPlusSetting_Req 0;
BA_ "GenSigTimeoutTime_SGW" SG_ 158 FSFCWPlusSetting_Req 0;
BA_ "GenSigTimeoutTime_TCM" SG_ 158 FSFCWPlusSetting_Req 0;
BA_ "GenSigSendType" SG_ 158 Fwrd_Cam_Guidelines_Req 3;
BA_ "GenSigTimeoutTime_AGSM" SG_ 158 Fwrd_Cam_Guidelines_Req 0;
BA_ "GenSigTimeoutTime_BCM" SG_ 158 Fwrd_Cam_Guidelines_Req 0;
BA_ "GenSigTimeoutTime_BSM" SG_ 158 Fwrd_Cam_Guidelines_Req 0;
BA_ "GenSigTimeoutTime_CADM" SG_ 158 Fwrd_Cam_Guidelines_Req 0;
BA_ "GenSigTimeoutTime_DMSM" SG_ 158 Fwrd_Cam_Guidelines_Req 0;
BA_ "GenSigTimeoutTime_DTCM" SG_ 158 Fwrd_Cam_Guidelines_Req 0;
BA_ "GenSigTimeoutTime_ECM" SG_ 158 Fwrd_Cam_Guidelines_Req 0;
BA_ "GenSigTimeoutTime_EVCU2" SG_ 158 Fwrd_Cam_Guidelines_Req 0;
BA_ "GenSigTimeoutTime_GNMM" SG_ 158 Fwrd_Cam_Guidelines_Req 0;
BA_ "GenSigTimeoutTime_HCP" SG_ 158 Fwrd_Cam_Guidelines_Req 0;
BA_ "GenSigTimeoutTime_RFHM" SG_ 158 Fwrd_Cam_Guidelines_Req 0;
BA_ "GenSigTimeoutTime_SGW" SG_ 158 Fwrd_Cam_Guidelines_Req 0;
BA_ "GenSigTimeoutTime_TCM" SG_ 158 Fwrd_Cam_Guidelines_Req 0;
BA_ "GenSigSendType" SG_ 158 GreetingLightsEnable_Req 1;
BA_ "GenSigTimeoutTime_AGSM" SG_ 158 GreetingLightsEnable_Req 0;
BA_ "GenSigTimeoutTime_BCM" SG_ 158 GreetingLightsEnable_Req 0;
BA_ "GenSigTimeoutTime_BSM" SG_ 158 GreetingLightsEnable_Req 0;
BA_ "GenSigTimeoutTime_CADM" SG_ 158 GreetingLightsEnable_Req 0;
BA_ "GenSigTimeoutTime_DMSM" SG_ 158 GreetingLightsEnable_Req 0;
BA_ "GenSigTimeoutTime_DTCM" SG_ 158 GreetingLightsEnable_Req 0;
BA_ "GenSigTimeoutTime_ECM" SG_ 158 GreetingLightsEnable_Req 0;
BA_ "GenSigTimeoutTime_EVCU2" SG_ 158 GreetingLightsEnable_Req 0;
BA_ "GenSigTimeoutTime_GNMM" SG_ 158 GreetingLightsEnable_Req 0;
BA_ "GenSigTimeoutTime_HCP" SG_ 158 GreetingLightsEnable_Req 0;
BA_ "GenSigTimeoutTime_RFHM" SG_ 158 GreetingLightsEnable_Req 0;
BA_ "GenSigTimeoutTime_SGW" SG_ 158 GreetingLightsEnable_Req 0;
BA_ "GenSigTimeoutTime_TCM" SG_ 158 GreetingLightsEnable_Req 0;
BA_ "GenSigSendType" SG_ 158 HeadlightsOffDelay_Req 1;
BA_ "GenSigTimeoutTime_AGSM" SG_ 158 HeadlightsOffDelay_Req 0;
BA_ "GenSigTimeoutTime_BCM" SG_ 158 HeadlightsOffDelay_Req 0;
BA_ "GenSigTimeoutTime_BSM" SG_ 158 HeadlightsOffDelay_Req 0;
BA_ "GenSigTimeoutTime_CADM" SG_ 158 HeadlightsOffDelay_Req 0;
BA_ "GenSigTimeoutTime_DMSM" SG_ 158 HeadlightsOffDelay_Req 0;
BA_ "GenSigTimeoutTime_DTCM" SG_ 158 HeadlightsOffDelay_Req 0;
BA_ "GenSigTimeoutTime_ECM" SG_ 158 HeadlightsOffDelay_Req 0;
BA_ "GenSigTimeoutTime_EVCU2" SG_ 158 HeadlightsOffDelay_Req 0;
BA_ "GenSigTimeoutTime_GNMM" SG_ 158 HeadlightsOffDelay_Req 0;
BA_ "GenSigTimeoutTime_HCP" SG_ 158 HeadlightsOffDelay_Req 0;
BA_ "GenSigTimeoutTime_RFHM" SG_ 158 HeadlightsOffDelay_Req 0;
BA_ "GenSigTimeoutTime_SGW" SG_ 158 HeadlightsOffDelay_Req 0;
BA_ "GenSigTimeoutTime_TCM" SG_ 158 HeadlightsOffDelay_Req 0;
BA_ "GenSigStartValue" SG_ 158 HeadLightWipers_Req 1;
BA_ "GenSigSendType" SG_ 158 HeadLightWipers_Req 1;
BA_ "GenSigTimeoutTime_AGSM" SG_ 158 HeadLightWipers_Req 0;
BA_ "GenSigTimeoutTime_BCM" SG_ 158 HeadLightWipers_Req 0;
BA_ "GenSigTimeoutTime_BSM" SG_ 158 HeadLightWipers_Req 0;
BA_ "GenSigTimeoutTime_CADM" SG_ 158 HeadLightWipers_Req 0;
BA_ "GenSigTimeoutTime_DMSM" SG_ 158 HeadLightWipers_Req 0;
BA_ "GenSigTimeoutTime_DTCM" SG_ 158 HeadLightWipers_Req 0;
BA_ "GenSigTimeoutTime_ECM" SG_ 158 HeadLightWipers_Req 0;
BA_ "GenSigTimeoutTime_EVCU2" SG_ 158 HeadLightWipers_Req 0;
BA_ "GenSigTimeoutTime_GNMM" SG_ 158 HeadLightWipers_Req 0;
BA_ "GenSigTimeoutTime_HCP" SG_ 158 HeadLightWipers_Req 0;
BA_ "GenSigTimeoutTime_RFHM" SG_ 158 HeadLightWipers_Req 0;
BA_ "GenSigTimeoutTime_SGW" SG_ 158 HeadLightWipers_Req 0;
BA_ "GenSigTimeoutTime_TCM" SG_ 158 HeadLightWipers_Req 0;
BA_ "GenSigSendType" SG_ 158 Hill_Start_Assist_Req 3;
BA_ "GenSigTimeoutTime_AGSM" SG_ 158 Hill_Start_Assist_Req 0;
BA_ "GenSigTimeoutTime_BCM" SG_ 158 Hill_Start_Assist_Req 0;
BA_ "GenSigTimeoutTime_BSM" SG_ 158 Hill_Start_Assist_Req 0;
BA_ "GenSigTimeoutTime_CADM" SG_ 158 Hill_Start_Assist_Req 0;
BA_ "GenSigTimeoutTime_DMSM" SG_ 158 Hill_Start_Assist_Req 0;
BA_ "GenSigTimeoutTime_DTCM" SG_ 158 Hill_Start_Assist_Req 0;
BA_ "GenSigTimeoutTime_ECM" SG_ 158 Hill_Start_Assist_Req 0;
BA_ "GenSigTimeoutTime_EVCU2" SG_ 158 Hill_Start_Assist_Req 0;
BA_ "GenSigTimeoutTime_GNMM" SG_ 158 Hill_Start_Assist_Req 0;
BA_ "GenSigTimeoutTime_HCP" SG_ 158 Hill_Start_Assist_Req 0;
BA_ "GenSigTimeoutTime_RFHM" SG_ 158 Hill_Start_Assist_Req 0;
BA_ "GenSigTimeoutTime_SGW" SG_ 158 Hill_Start_Assist_Req 0;
BA_ "GenSigTimeoutTime_TCM" SG_ 158 Hill_Start_Assist_Req 0;
BA_ "GenSigSendType" SG_ 158 HourMode_Req 1;
BA_ "GenSigTimeoutTime_AGSM" SG_ 158 HourMode_Req 0;
BA_ "GenSigTimeoutTime_BCM" SG_ 158 HourMode_Req 0;
BA_ "GenSigTimeoutTime_BSM" SG_ 158 HourMode_Req 0;
BA_ "GenSigTimeoutTime_CADM" SG_ 158 HourMode_Req 0;
BA_ "GenSigTimeoutTime_DMSM" SG_ 158 HourMode_Req 0;
BA_ "GenSigTimeoutTime_DTCM" SG_ 158 HourMode_Req 0;
BA_ "GenSigTimeoutTime_ECM" SG_ 158 HourMode_Req 0;
BA_ "GenSigTimeoutTime_EVCU2" SG_ 158 HourMode_Req 0;
BA_ "GenSigTimeoutTime_GNMM" SG_ 158 HourMode_Req 0;
BA_ "GenSigTimeoutTime_HCP" SG_ 158 HourMode_Req 0;
BA_ "GenSigTimeoutTime_RFHM" SG_ 158 HourMode_Req 0;
BA_ "GenSigTimeoutTime_SGW" SG_ 158 HourMode_Req 0;
BA_ "GenSigTimeoutTime_TCM" SG_ 158 HourMode_Req 0;
BA_ "GenSigSendType" SG_ 158 HP_Unit_Req 3;
BA_ "GenSigTimeoutTime_AGSM" SG_ 158 HP_Unit_Req 0;
BA_ "GenSigTimeoutTime_BCM" SG_ 158 HP_Unit_Req 0;
BA_ "GenSigTimeoutTime_BSM" SG_ 158 HP_Unit_Req 0;
BA_ "GenSigTimeoutTime_CADM" SG_ 158 HP_Unit_Req 0;
BA_ "GenSigTimeoutTime_DMSM" SG_ 158 HP_Unit_Req 0;
BA_ "GenSigTimeoutTime_DTCM" SG_ 158 HP_Unit_Req 0;
BA_ "GenSigTimeoutTime_ECM" SG_ 158 HP_Unit_Req 0;
BA_ "GenSigTimeoutTime_EVCU2" SG_ 158 HP_Unit_Req 0;
BA_ "GenSigTimeoutTime_GNMM" SG_ 158 HP_Unit_Req 0;
BA_ "GenSigTimeoutTime_HCP" SG_ 158 HP_Unit_Req 0;
BA_ "GenSigTimeoutTime_RFHM" SG_ 158 HP_Unit_Req 0;
BA_ "GenSigTimeoutTime_SGW" SG_ 158 HP_Unit_Req 0;
BA_ "GenSigTimeoutTime_TCM" SG_ 158 HP_Unit_Req 0;
BA_ "GenSigSendType" SG_ 158 Illuminated_Approach_Req 3;
BA_ "GenSigTimeoutTime_AGSM" SG_ 158 Illuminated_Approach_Req 0;
BA_ "GenSigTimeoutTime_BCM" SG_ 158 Illuminated_Approach_Req 0;
BA_ "GenSigTimeoutTime_BSM" SG_ 158 Illuminated_Approach_Req 0;
BA_ "GenSigTimeoutTime_CADM" SG_ 158 Illuminated_Approach_Req 0;
BA_ "GenSigTimeoutTime_DMSM" SG_ 158 Illuminated_Approach_Req 0;
BA_ "GenSigTimeoutTime_DTCM" SG_ 158 Illuminated_Approach_Req 0;
BA_ "GenSigTimeoutTime_ECM" SG_ 158 Illuminated_Approach_Req 0;
BA_ "GenSigTimeoutTime_EVCU2" SG_ 158 Illuminated_Approach_Req 0;
BA_ "GenSigTimeoutTime_GNMM" SG_ 158 Illuminated_Approach_Req 0;
BA_ "GenSigTimeoutTime_HCP" SG_ 158 Illuminated_Approach_Req 0;
BA_ "GenSigTimeoutTime_RFHM" SG_ 158 Illuminated_Approach_Req 0;
BA_ "GenSigTimeoutTime_SGW" SG_ 158 Illuminated_Approach_Req 0;
BA_ "GenSigTimeoutTime_TCM" SG_ 158 Illuminated_Approach_Req 0;
BA_ "GenSigSendType" SG_ 158 LanguageSelection_Req 1;
BA_ "GenSigTimeoutTime_AGSM" SG_ 158 LanguageSelection_Req 0;
BA_ "GenSigTimeoutTime_BCM" SG_ 158 LanguageSelection_Req 0;
BA_ "GenSigTimeoutTime_BSM" SG_ 158 LanguageSelection_Req 0;
BA_ "GenSigTimeoutTime_CADM" SG_ 158 LanguageSelection_Req 0;
BA_ "GenSigTimeoutTime_DMSM" SG_ 158 LanguageSelection_Req 0;
BA_ "GenSigTimeoutTime_DTCM" SG_ 158 LanguageSelection_Req 0;
BA_ "GenSigTimeoutTime_ECM" SG_ 158 LanguageSelection_Req 0;
BA_ "GenSigTimeoutTime_EVCU2" SG_ 158 LanguageSelection_Req 0;
BA_ "GenSigTimeoutTime_GNMM" SG_ 158 LanguageSelection_Req 0;
BA_ "GenSigTimeoutTime_HCP" SG_ 158 LanguageSelection_Req 0;
BA_ "GenSigTimeoutTime_RFHM" SG_ 158 LanguageSelection_Req 0;
BA_ "GenSigTimeoutTime_SGW" SG_ 158 LanguageSelection_Req 0;
BA_ "GenSigTimeoutTime_TCM" SG_ 158 LanguageSelection_Req 0;
BA_ "GenSigSendType" SG_ 158 LDW_Intensity_Req 1;
BA_ "GenSigTimeoutTime_AGSM" SG_ 158 LDW_Intensity_Req 0;
BA_ "GenSigTimeoutTime_BCM" SG_ 158 LDW_Intensity_Req 0;
BA_ "GenSigTimeoutTime_BSM" SG_ 158 LDW_Intensity_Req 0;
BA_ "GenSigTimeoutTime_CADM" SG_ 158 LDW_Intensity_Req 0;
BA_ "GenSigTimeoutTime_DMSM" SG_ 158 LDW_Intensity_Req 0;
BA_ "GenSigTimeoutTime_DTCM" SG_ 158 LDW_Intensity_Req 0;
BA_ "GenSigTimeoutTime_ECM" SG_ 158 LDW_Intensity_Req 0;
BA_ "GenSigTimeoutTime_EVCU2" SG_ 158 LDW_Intensity_Req 0;
BA_ "GenSigTimeoutTime_GNMM" SG_ 158 LDW_Intensity_Req 0;
BA_ "GenSigTimeoutTime_HCP" SG_ 158 LDW_Intensity_Req 0;
BA_ "GenSigTimeoutTime_RFHM" SG_ 158 LDW_Intensity_Req 0;
BA_ "GenSigTimeoutTime_SGW" SG_ 158 LDW_Intensity_Req 0;
BA_ "GenSigTimeoutTime_TCM" SG_ 158 LDW_Intensity_Req 0;
BA_ "GenSigStartValue" SG_ 158 LDW_Sensibility_Req 3;
BA_ "GenSigSendType" SG_ 158 LDW_Sensibility_Req 1;
BA_ "GenSigTimeoutTime_AGSM" SG_ 158 LDW_Sensibility_Req 0;
BA_ "GenSigTimeoutTime_BCM" SG_ 158 LDW_Sensibility_Req 0;
BA_ "GenSigTimeoutTime_BSM" SG_ 158 LDW_Sensibility_Req 0;
BA_ "GenSigTimeoutTime_CADM" SG_ 158 LDW_Sensibility_Req 0;
BA_ "GenSigTimeoutTime_DMSM" SG_ 158 LDW_Sensibility_Req 0;
BA_ "GenSigTimeoutTime_DTCM" SG_ 158 LDW_Sensibility_Req 0;
BA_ "GenSigTimeoutTime_ECM" SG_ 158 LDW_Sensibility_Req 0;
BA_ "GenSigTimeoutTime_EVCU2" SG_ 158 LDW_Sensibility_Req 0;
BA_ "GenSigTimeoutTime_GNMM" SG_ 158 LDW_Sensibility_Req 0;
BA_ "GenSigTimeoutTime_HCP" SG_ 158 LDW_Sensibility_Req 0;
BA_ "GenSigTimeoutTime_RFHM" SG_ 158 LDW_Sensibility_Req 0;
BA_ "GenSigTimeoutTime_SGW" SG_ 158 LDW_Sensibility_Req 0;
BA_ "GenSigTimeoutTime_TCM" SG_ 158 LDW_Sensibility_Req 0;
BA_ "GenSigTimeoutTime_AGSM" SG_ 158 MessageCounter_TVS1 0;
BA_ "GenSigTimeoutTime_BCM" SG_ 158 MessageCounter_TVS1 0;
BA_ "GenSigTimeoutTime_BSM" SG_ 158 MessageCounter_TVS1 0;
BA_ "GenSigTimeoutTime_DMSM" SG_ 158 MessageCounter_TVS1 0;
BA_ "GenSigTimeoutTime_DTCM" SG_ 158 MessageCounter_TVS1 0;
BA_ "GenSigTimeoutTime_ECM" SG_ 158 MessageCounter_TVS1 0;
BA_ "GenSigTimeoutTime_EVCU2" SG_ 158 MessageCounter_TVS1 0;
BA_ "GenSigTimeoutTime_GNMM" SG_ 158 MessageCounter_TVS1 0;
BA_ "GenSigTimeoutTime_HCP" SG_ 158 MessageCounter_TVS1 0;
BA_ "GenSigTimeoutTime_IPC" SG_ 158 MessageCounter_TVS1 0;
BA_ "GenSigTimeoutTime_RFHM" SG_ 158 MessageCounter_TVS1 0;
BA_ "GenSigTimeoutTime_SGW" SG_ 158 MessageCounter_TVS1 0;
BA_ "GenSigTimeoutTime_TCM" SG_ 158 MessageCounter_TVS1 0;
BA_ "GenSigSendType" SG_ 158 NavigationRepetition_Req 1;
BA_ "GenSigTimeoutTime_AGSM" SG_ 158 NavigationRepetition_Req 0;
BA_ "GenSigTimeoutTime_BCM" SG_ 158 NavigationRepetition_Req 0;
BA_ "GenSigTimeoutTime_BSM" SG_ 158 NavigationRepetition_Req 0;
BA_ "GenSigTimeoutTime_CADM" SG_ 158 NavigationRepetition_Req 0;
BA_ "GenSigTimeoutTime_DMSM" SG_ 158 NavigationRepetition_Req 0;
BA_ "GenSigTimeoutTime_DTCM" SG_ 158 NavigationRepetition_Req 0;
BA_ "GenSigTimeoutTime_ECM" SG_ 158 NavigationRepetition_Req 0;
BA_ "GenSigTimeoutTime_EVCU2" SG_ 158 NavigationRepetition_Req 0;
BA_ "GenSigTimeoutTime_GNMM" SG_ 158 NavigationRepetition_Req 0;
BA_ "GenSigTimeoutTime_HCP" SG_ 158 NavigationRepetition_Req 0;
BA_ "GenSigTimeoutTime_RFHM" SG_ 158 NavigationRepetition_Req 0;
BA_ "GenSigTimeoutTime_SGW" SG_ 158 NavigationRepetition_Req 0;
BA_ "GenSigTimeoutTime_TCM" SG_ 158 NavigationRepetition_Req 0;
BA_ "GenSigSendType" SG_ 158 New_Spd_Zone_Ind_Req 3;
BA_ "GenSigTimeoutTime_AGSM" SG_ 158 New_Spd_Zone_Ind_Req 0;
BA_ "GenSigTimeoutTime_BCM" SG_ 158 New_Spd_Zone_Ind_Req 0;
BA_ "GenSigTimeoutTime_BSM" SG_ 158 New_Spd_Zone_Ind_Req 0;
BA_ "GenSigTimeoutTime_CADM" SG_ 158 New_Spd_Zone_Ind_Req 0;
BA_ "GenSigTimeoutTime_DMSM" SG_ 158 New_Spd_Zone_Ind_Req 0;
BA_ "GenSigTimeoutTime_DTCM" SG_ 158 New_Spd_Zone_Ind_Req 0;
BA_ "GenSigTimeoutTime_ECM" SG_ 158 New_Spd_Zone_Ind_Req 0;
BA_ "GenSigTimeoutTime_EVCU2" SG_ 158 New_Spd_Zone_Ind_Req 0;
BA_ "GenSigTimeoutTime_GNMM" SG_ 158 New_Spd_Zone_Ind_Req 0;
BA_ "GenSigTimeoutTime_HCP" SG_ 158 New_Spd_Zone_Ind_Req 0;
BA_ "GenSigTimeoutTime_RFHM" SG_ 158 New_Spd_Zone_Ind_Req 0;
BA_ "GenSigTimeoutTime_SGW" SG_ 158 New_Spd_Zone_Ind_Req 0;
BA_ "GenSigTimeoutTime_TCM" SG_ 158 New_Spd_Zone_Ind_Req 0;
BA_ "GenSigSendType" SG_ 158 Paddle_Shifter_Req 3;
BA_ "GenSigTimeoutTime_AGSM" SG_ 158 Paddle_Shifter_Req 0;
BA_ "GenSigTimeoutTime_BCM" SG_ 158 Paddle_Shifter_Req 0;
BA_ "GenSigTimeoutTime_BSM" SG_ 158 Paddle_Shifter_Req 0;
BA_ "GenSigTimeoutTime_CADM" SG_ 158 Paddle_Shifter_Req 0;
BA_ "GenSigTimeoutTime_DMSM" SG_ 158 Paddle_Shifter_Req 0;
BA_ "GenSigTimeoutTime_DTCM" SG_ 158 Paddle_Shifter_Req 0;
BA_ "GenSigTimeoutTime_ECM" SG_ 158 Paddle_Shifter_Req 0;
BA_ "GenSigTimeoutTime_EVCU2" SG_ 158 Paddle_Shifter_Req 0;
BA_ "GenSigTimeoutTime_GNMM" SG_ 158 Paddle_Shifter_Req 0;
BA_ "GenSigTimeoutTime_HCP" SG_ 158 Paddle_Shifter_Req 0;
BA_ "GenSigTimeoutTime_RFHM" SG_ 158 Paddle_Shifter_Req 0;
BA_ "GenSigTimeoutTime_SGW" SG_ 158 Paddle_Shifter_Req 0;
BA_ "GenSigTimeoutTime_TCM" SG_ 158 Paddle_Shifter_Req 0;
BA_ "GenSigStartValue" SG_ 158 PamChimeVolumeFront_Req 1;
BA_ "GenSigSendType" SG_ 158 PamChimeVolumeFront_Req 1;
BA_ "GenSigTimeoutTime_AGSM" SG_ 158 PamChimeVolumeFront_Req 0;
BA_ "GenSigTimeoutTime_BCM" SG_ 158 PamChimeVolumeFront_Req 0;
BA_ "GenSigTimeoutTime_BSM" SG_ 158 PamChimeVolumeFront_Req 0;
BA_ "GenSigTimeoutTime_CADM" SG_ 158 PamChimeVolumeFront_Req 0;
BA_ "GenSigTimeoutTime_DMSM" SG_ 158 PamChimeVolumeFront_Req 0;
BA_ "GenSigTimeoutTime_DTCM" SG_ 158 PamChimeVolumeFront_Req 0;
BA_ "GenSigTimeoutTime_ECM" SG_ 158 PamChimeVolumeFront_Req 0;
BA_ "GenSigTimeoutTime_EVCU2" SG_ 158 PamChimeVolumeFront_Req 0;
BA_ "GenSigTimeoutTime_GNMM" SG_ 158 PamChimeVolumeFront_Req 0;
BA_ "GenSigTimeoutTime_HCP" SG_ 158 PamChimeVolumeFront_Req 0;
BA_ "GenSigTimeoutTime_RFHM" SG_ 158 PamChimeVolumeFront_Req 0;
BA_ "GenSigTimeoutTime_SGW" SG_ 158 PamChimeVolumeFront_Req 0;
BA_ "GenSigTimeoutTime_TCM" SG_ 158 PamChimeVolumeFront_Req 0;
BA_ "GenSigStartValue" SG_ 158 PamChimeVolumeRear_Req 1;
BA_ "GenSigSendType" SG_ 158 PamChimeVolumeRear_Req 1;
BA_ "GenSigTimeoutTime_AGSM" SG_ 158 PamChimeVolumeRear_Req 0;
BA_ "GenSigTimeoutTime_BCM" SG_ 158 PamChimeVolumeRear_Req 0;
BA_ "GenSigTimeoutTime_BSM" SG_ 158 PamChimeVolumeRear_Req 0;
BA_ "GenSigTimeoutTime_CADM" SG_ 158 PamChimeVolumeRear_Req 0;
BA_ "GenSigTimeoutTime_DMSM" SG_ 158 PamChimeVolumeRear_Req 0;
BA_ "GenSigTimeoutTime_DTCM" SG_ 158 PamChimeVolumeRear_Req 0;
BA_ "GenSigTimeoutTime_ECM" SG_ 158 PamChimeVolumeRear_Req 0;
BA_ "GenSigTimeoutTime_EVCU2" SG_ 158 PamChimeVolumeRear_Req 0;
BA_ "GenSigTimeoutTime_GNMM" SG_ 158 PamChimeVolumeRear_Req 0;
BA_ "GenSigTimeoutTime_HCP" SG_ 158 PamChimeVolumeRear_Req 0;
BA_ "GenSigTimeoutTime_RFHM" SG_ 158 PamChimeVolumeRear_Req 0;
BA_ "GenSigTimeoutTime_SGW" SG_ 158 PamChimeVolumeRear_Req 0;
BA_ "GenSigTimeoutTime_TCM" SG_ 158 PamChimeVolumeRear_Req 0;
BA_ "GenSigSendType" SG_ 158 PassiveEntry_Req 1;
BA_ "GenSigTimeoutTime_AGSM" SG_ 158 PassiveEntry_Req 0;
BA_ "GenSigTimeoutTime_BCM" SG_ 158 PassiveEntry_Req 0;
BA_ "GenSigTimeoutTime_BSM" SG_ 158 PassiveEntry_Req 0;
BA_ "GenSigTimeoutTime_CADM" SG_ 158 PassiveEntry_Req 0;
BA_ "GenSigTimeoutTime_DMSM" SG_ 158 PassiveEntry_Req 0;
BA_ "GenSigTimeoutTime_DTCM" SG_ 158 PassiveEntry_Req 0;
BA_ "GenSigTimeoutTime_ECM" SG_ 158 PassiveEntry_Req 0;
BA_ "GenSigTimeoutTime_EVCU2" SG_ 158 PassiveEntry_Req 0;
BA_ "GenSigTimeoutTime_GNMM" SG_ 158 PassiveEntry_Req 0;
BA_ "GenSigTimeoutTime_HCP" SG_ 158 PassiveEntry_Req 0;
BA_ "GenSigTimeoutTime_RFHM" SG_ 158 PassiveEntry_Req 0;
BA_ "GenSigTimeoutTime_SGW" SG_ 158 PassiveEntry_Req 0;
BA_ "GenSigTimeoutTime_TCM" SG_ 158 PassiveEntry_Req 0;
BA_ "GenSigSendType" SG_ 158 Ped_EM_Brk_Warn_Act_Req 3;
BA_ "GenSigTimeoutTime_AGSM" SG_ 158 Ped_EM_Brk_Warn_Act_Req 0;
BA_ "GenSigTimeoutTime_BCM" SG_ 158 Ped_EM_Brk_Warn_Act_Req 0;
BA_ "GenSigTimeoutTime_BSM" SG_ 158 Ped_EM_Brk_Warn_Act_Req 0;
BA_ "GenSigTimeoutTime_DMSM" SG_ 158 Ped_EM_Brk_Warn_Act_Req 0;
BA_ "GenSigTimeoutTime_DTCM" SG_ 158 Ped_EM_Brk_Warn_Act_Req 0;
BA_ "GenSigTimeoutTime_ECM" SG_ 158 Ped_EM_Brk_Warn_Act_Req 0;
BA_ "GenSigTimeoutTime_EVCU2" SG_ 158 Ped_EM_Brk_Warn_Act_Req 0;
BA_ "GenSigTimeoutTime_GNMM" SG_ 158 Ped_EM_Brk_Warn_Act_Req 0;
BA_ "GenSigTimeoutTime_HCP" SG_ 158 Ped_EM_Brk_Warn_Act_Req 0;
BA_ "GenSigTimeoutTime_RFHM" SG_ 158 Ped_EM_Brk_Warn_Act_Req 0;
BA_ "GenSigTimeoutTime_SGW" SG_ 158 Ped_EM_Brk_Warn_Act_Req 0;
BA_ "GenSigTimeoutTime_TCM" SG_ 158 Ped_EM_Brk_Warn_Act_Req 0;
BA_ "GenSigSendType" SG_ 158 PhoneRepetition_Req 1;
BA_ "GenSigTimeoutTime_AGSM" SG_ 158 PhoneRepetition_Req 0;
BA_ "GenSigTimeoutTime_BCM" SG_ 158 PhoneRepetition_Req 0;
BA_ "GenSigTimeoutTime_BSM" SG_ 158 PhoneRepetition_Req 0;
BA_ "GenSigTimeoutTime_CADM" SG_ 158 PhoneRepetition_Req 0;
BA_ "GenSigTimeoutTime_DMSM" SG_ 158 PhoneRepetition_Req 0;
BA_ "GenSigTimeoutTime_DTCM" SG_ 158 PhoneRepetition_Req 0;
BA_ "GenSigTimeoutTime_ECM" SG_ 158 PhoneRepetition_Req 0;
BA_ "GenSigTimeoutTime_EVCU2" SG_ 158 PhoneRepetition_Req 0;
BA_ "GenSigTimeoutTime_GNMM" SG_ 158 PhoneRepetition_Req 0;
BA_ "GenSigTimeoutTime_HCP" SG_ 158 PhoneRepetition_Req 0;
BA_ "GenSigTimeoutTime_RFHM" SG_ 158 PhoneRepetition_Req 0;
BA_ "GenSigTimeoutTime_SGW" SG_ 158 PhoneRepetition_Req 0;
BA_ "GenSigTimeoutTime_TCM" SG_ 158 PhoneRepetition_Req 0;
BA_ "GenSigStartValue" SG_ 158 PLGAlert_Req 1;
BA_ "GenSigSendType" SG_ 158 PLGAlert_Req 1;
BA_ "GenSigTimeoutTime_AGSM" SG_ 158 PLGAlert_Req 0;
BA_ "GenSigTimeoutTime_BCM" SG_ 158 PLGAlert_Req 0;
BA_ "GenSigTimeoutTime_BSM" SG_ 158 PLGAlert_Req 0;
BA_ "GenSigTimeoutTime_CADM" SG_ 158 PLGAlert_Req 0;
BA_ "GenSigTimeoutTime_DMSM" SG_ 158 PLGAlert_Req 0;
BA_ "GenSigTimeoutTime_DTCM" SG_ 158 PLGAlert_Req 0;
BA_ "GenSigTimeoutTime_ECM" SG_ 158 PLGAlert_Req 0;
BA_ "GenSigTimeoutTime_EVCU2" SG_ 158 PLGAlert_Req 0;
BA_ "GenSigTimeoutTime_GNMM" SG_ 158 PLGAlert_Req 0;
BA_ "GenSigTimeoutTime_HCP" SG_ 158 PLGAlert_Req 0;
BA_ "GenSigTimeoutTime_RFHM" SG_ 158 PLGAlert_Req 0;
BA_ "GenSigTimeoutTime_SGW" SG_ 158 PLGAlert_Req 0;
BA_ "GenSigTimeoutTime_TCM" SG_ 158 PLGAlert_Req 0;
BA_ "GenSigSendType" SG_ 158 Power_Side_Step_Req 3;
BA_ "GenSigTimeoutTime_AGSM" SG_ 158 Power_Side_Step_Req 0;
BA_ "GenSigTimeoutTime_BCM" SG_ 158 Power_Side_Step_Req 0;
BA_ "GenSigTimeoutTime_BSM" SG_ 158 Power_Side_Step_Req 0;
BA_ "GenSigTimeoutTime_CADM" SG_ 158 Power_Side_Step_Req 0;
BA_ "GenSigTimeoutTime_DMSM" SG_ 158 Power_Side_Step_Req 0;
BA_ "GenSigTimeoutTime_DTCM" SG_ 158 Power_Side_Step_Req 0;
BA_ "GenSigTimeoutTime_ECM" SG_ 158 Power_Side_Step_Req 0;
BA_ "GenSigTimeoutTime_EVCU2" SG_ 158 Power_Side_Step_Req 0;
BA_ "GenSigTimeoutTime_GNMM" SG_ 158 Power_Side_Step_Req 0;
BA_ "GenSigTimeoutTime_HCP" SG_ 158 Power_Side_Step_Req 0;
BA_ "GenSigTimeoutTime_RFHM" SG_ 158 Power_Side_Step_Req 0;
BA_ "GenSigTimeoutTime_SGW" SG_ 158 Power_Side_Step_Req 0;
BA_ "GenSigTimeoutTime_TCM" SG_ 158 Power_Side_Step_Req 0;
BA_ "GenSigSendType" SG_ 158 Proximity_WU_Req 3;
BA_ "GenSigTimeoutTime_AGSM" SG_ 158 Proximity_WU_Req 0;
BA_ "GenSigTimeoutTime_BCM" SG_ 158 Proximity_WU_Req 0;
BA_ "GenSigTimeoutTime_BSM" SG_ 158 Proximity_WU_Req 0;
BA_ "GenSigTimeoutTime_CADM" SG_ 158 Proximity_WU_Req 0;
BA_ "GenSigTimeoutTime_DMSM" SG_ 158 Proximity_WU_Req 0;
BA_ "GenSigTimeoutTime_DTCM" SG_ 158 Proximity_WU_Req 0;
BA_ "GenSigTimeoutTime_ECM" SG_ 158 Proximity_WU_Req 0;
BA_ "GenSigTimeoutTime_EVCU2" SG_ 158 Proximity_WU_Req 0;
BA_ "GenSigTimeoutTime_GNMM" SG_ 158 Proximity_WU_Req 0;
BA_ "GenSigTimeoutTime_HCP" SG_ 158 Proximity_WU_Req 0;
BA_ "GenSigTimeoutTime_RFHM" SG_ 158 Proximity_WU_Req 0;
BA_ "GenSigTimeoutTime_SGW" SG_ 158 Proximity_WU_Req 0;
BA_ "GenSigTimeoutTime_TCM" SG_ 158 Proximity_WU_Req 0;
BA_ "GenSigStartValue" SG_ 158 PwrLevReq 2;
BA_ "GenSigSendType" SG_ 158 PwrLevReq 1;
BA_ "GenSigTimeoutTime_AGSM" SG_ 158 PwrLevReq 0;
BA_ "GenSigTimeoutTime_BCM" SG_ 158 PwrLevReq 0;
BA_ "GenSigTimeoutTime_BSM" SG_ 158 PwrLevReq 0;
BA_ "GenSigTimeoutTime_CADM" SG_ 158 PwrLevReq 0;
BA_ "GenSigTimeoutTime_DMSM" SG_ 158 PwrLevReq 0;
BA_ "GenSigTimeoutTime_DTCM" SG_ 158 PwrLevReq 0;
BA_ "GenSigTimeoutTime_ECM" SG_ 158 PwrLevReq 0;
BA_ "GenSigTimeoutTime_EVCU2" SG_ 158 PwrLevReq 0;
BA_ "GenSigTimeoutTime_GNMM" SG_ 158 PwrLevReq 0;
BA_ "GenSigTimeoutTime_HCP" SG_ 158 PwrLevReq 0;
BA_ "GenSigTimeoutTime_RFHM" SG_ 158 PwrLevReq 0;
BA_ "GenSigTimeoutTime_SGW" SG_ 158 PwrLevReq 0;
BA_ "GenSigTimeoutTime_TCM" SG_ 158 PwrLevReq 0;
BA_ "GenSigStartValue" SG_ 158 RainSensorLevel_Req 1;
BA_ "GenSigSendType" SG_ 158 RainSensorLevel_Req 1;
BA_ "GenSigTimeoutTime_AGSM" SG_ 158 RainSensorLevel_Req 0;
BA_ "GenSigTimeoutTime_BCM" SG_ 158 RainSensorLevel_Req 0;
BA_ "GenSigTimeoutTime_BSM" SG_ 158 RainSensorLevel_Req 0;
BA_ "GenSigTimeoutTime_CADM" SG_ 158 RainSensorLevel_Req 0;
BA_ "GenSigTimeoutTime_DMSM" SG_ 158 RainSensorLevel_Req 0;
BA_ "GenSigTimeoutTime_DTCM" SG_ 158 RainSensorLevel_Req 0;
BA_ "GenSigTimeoutTime_ECM" SG_ 158 RainSensorLevel_Req 0;
BA_ "GenSigTimeoutTime_EVCU2" SG_ 158 RainSensorLevel_Req 0;
BA_ "GenSigTimeoutTime_GNMM" SG_ 158 RainSensorLevel_Req 0;
BA_ "GenSigTimeoutTime_HCP" SG_ 158 RainSensorLevel_Req 0;
BA_ "GenSigTimeoutTime_RFHM" SG_ 158 RainSensorLevel_Req 0;
BA_ "GenSigTimeoutTime_SGW" SG_ 158 RainSensorLevel_Req 0;
BA_ "GenSigTimeoutTime_TCM" SG_ 158 RainSensorLevel_Req 0;
BA_ "GenSigSendType" SG_ 158 Rdy_To_Drive_Req 3;
BA_ "GenSigTimeoutTime_AGSM" SG_ 158 Rdy_To_Drive_Req 0;
BA_ "GenSigTimeoutTime_BCM" SG_ 158 Rdy_To_Drive_Req 0;
BA_ "GenSigTimeoutTime_BSM" SG_ 158 Rdy_To_Drive_Req 0;
BA_ "GenSigTimeoutTime_CADM" SG_ 158 Rdy_To_Drive_Req 0;
BA_ "GenSigTimeoutTime_DMSM" SG_ 158 Rdy_To_Drive_Req 0;
BA_ "GenSigTimeoutTime_DTCM" SG_ 158 Rdy_To_Drive_Req 0;
BA_ "GenSigTimeoutTime_ECM" SG_ 158 Rdy_To_Drive_Req 0;
BA_ "GenSigTimeoutTime_EVCU2" SG_ 158 Rdy_To_Drive_Req 0;
BA_ "GenSigTimeoutTime_GNMM" SG_ 158 Rdy_To_Drive_Req 0;
BA_ "GenSigTimeoutTime_HCP" SG_ 158 Rdy_To_Drive_Req 0;
BA_ "GenSigTimeoutTime_RFHM" SG_ 158 Rdy_To_Drive_Req 0;
BA_ "GenSigTimeoutTime_SGW" SG_ 158 Rdy_To_Drive_Req 0;
BA_ "GenSigTimeoutTime_TCM" SG_ 158 Rdy_To_Drive_Req 0;
BA_ "GenSigSendType" SG_ 158 Rear_Brk_Asst_Req 3;
BA_ "GenSigTimeoutTime_AGSM" SG_ 158 Rear_Brk_Asst_Req 0;
BA_ "GenSigTimeoutTime_BCM" SG_ 158 Rear_Brk_Asst_Req 0;
BA_ "GenSigTimeoutTime_BSM" SG_ 158 Rear_Brk_Asst_Req 0;
BA_ "GenSigTimeoutTime_CADM" SG_ 158 Rear_Brk_Asst_Req 0;
BA_ "GenSigTimeoutTime_DMSM" SG_ 158 Rear_Brk_Asst_Req 0;
BA_ "GenSigTimeoutTime_DTCM" SG_ 158 Rear_Brk_Asst_Req 0;
BA_ "GenSigTimeoutTime_ECM" SG_ 158 Rear_Brk_Asst_Req 0;
BA_ "GenSigTimeoutTime_EVCU2" SG_ 158 Rear_Brk_Asst_Req 0;
BA_ "GenSigTimeoutTime_GNMM" SG_ 158 Rear_Brk_Asst_Req 0;
BA_ "GenSigTimeoutTime_HCP" SG_ 158 Rear_Brk_Asst_Req 0;
BA_ "GenSigTimeoutTime_RFHM" SG_ 158 Rear_Brk_Asst_Req 0;
BA_ "GenSigTimeoutTime_SGW" SG_ 158 Rear_Brk_Asst_Req 0;
BA_ "GenSigTimeoutTime_TCM" SG_ 158 Rear_Brk_Asst_Req 0;
BA_ "GenSigStartValue" SG_ 158 RemoteDoorUnlock_Req 1;
BA_ "GenSigSendType" SG_ 158 RemoteDoorUnlock_Req 1;
BA_ "GenSigTimeoutTime_AGSM" SG_ 158 RemoteDoorUnlock_Req 0;
BA_ "GenSigTimeoutTime_BCM" SG_ 158 RemoteDoorUnlock_Req 0;
BA_ "GenSigTimeoutTime_BSM" SG_ 158 RemoteDoorUnlock_Req 0;
BA_ "GenSigTimeoutTime_CADM" SG_ 158 RemoteDoorUnlock_Req 0;
BA_ "GenSigTimeoutTime_DMSM" SG_ 158 RemoteDoorUnlock_Req 0;
BA_ "GenSigTimeoutTime_DTCM" SG_ 158 RemoteDoorUnlock_Req 0;
BA_ "GenSigTimeoutTime_ECM" SG_ 158 RemoteDoorUnlock_Req 0;
BA_ "GenSigTimeoutTime_EVCU2" SG_ 158 RemoteDoorUnlock_Req 0;
BA_ "GenSigTimeoutTime_GNMM" SG_ 158 RemoteDoorUnlock_Req 0;
BA_ "GenSigTimeoutTime_HCP" SG_ 158 RemoteDoorUnlock_Req 0;
BA_ "GenSigTimeoutTime_RFHM" SG_ 158 RemoteDoorUnlock_Req 0;
BA_ "GenSigTimeoutTime_SGW" SG_ 158 RemoteDoorUnlock_Req 0;
BA_ "GenSigTimeoutTime_TCM" SG_ 158 RemoteDoorUnlock_Req 0;
BA_ "GenSigStartValue" SG_ 158 RemStNrmlStEnbl_Req 2;
BA_ "GenSigSendType" SG_ 158 RemStNrmlStEnbl_Req 1;
BA_ "GenSigTimeoutTime_AGSM" SG_ 158 RemStNrmlStEnbl_Req 0;
BA_ "GenSigTimeoutTime_BCM" SG_ 158 RemStNrmlStEnbl_Req 0;
BA_ "GenSigTimeoutTime_BSM" SG_ 158 RemStNrmlStEnbl_Req 0;
BA_ "GenSigTimeoutTime_CADM" SG_ 158 RemStNrmlStEnbl_Req 0;
BA_ "GenSigTimeoutTime_DMSM" SG_ 158 RemStNrmlStEnbl_Req 0;
BA_ "GenSigTimeoutTime_DTCM" SG_ 158 RemStNrmlStEnbl_Req 0;
BA_ "GenSigTimeoutTime_ECM" SG_ 158 RemStNrmlStEnbl_Req 0;
BA_ "GenSigTimeoutTime_EVCU2" SG_ 158 RemStNrmlStEnbl_Req 0;
BA_ "GenSigTimeoutTime_GNMM" SG_ 158 RemStNrmlStEnbl_Req 0;
BA_ "GenSigTimeoutTime_HCP" SG_ 158 RemStNrmlStEnbl_Req 0;
BA_ "GenSigTimeoutTime_RFHM" SG_ 158 RemStNrmlStEnbl_Req 0;
BA_ "GenSigTimeoutTime_SGW" SG_ 158 RemStNrmlStEnbl_Req 0;
BA_ "GenSigTimeoutTime_TCM" SG_ 158 RemStNrmlStEnbl_Req 0;
BA_ "GenSigStartValue" SG_ 158 RKEMemoryLinkEnable_Req 1;
BA_ "GenSigSendType" SG_ 158 RKEMemoryLinkEnable_Req 1;
BA_ "GenSigTimeoutTime_AGSM" SG_ 158 RKEMemoryLinkEnable_Req 0;
BA_ "GenSigTimeoutTime_BCM" SG_ 158 RKEMemoryLinkEnable_Req 0;
BA_ "GenSigTimeoutTime_BSM" SG_ 158 RKEMemoryLinkEnable_Req 0;
BA_ "GenSigTimeoutTime_CADM" SG_ 158 RKEMemoryLinkEnable_Req 0;
BA_ "GenSigTimeoutTime_DMSM" SG_ 158 RKEMemoryLinkEnable_Req 0;
BA_ "GenSigTimeoutTime_DTCM" SG_ 158 RKEMemoryLinkEnable_Req 0;
BA_ "GenSigTimeoutTime_ECM" SG_ 158 RKEMemoryLinkEnable_Req 0;
BA_ "GenSigTimeoutTime_EVCU2" SG_ 158 RKEMemoryLinkEnable_Req 0;
BA_ "GenSigTimeoutTime_GNMM" SG_ 158 RKEMemoryLinkEnable_Req 0;
BA_ "GenSigTimeoutTime_HCP" SG_ 158 RKEMemoryLinkEnable_Req 0;
BA_ "GenSigTimeoutTime_RFHM" SG_ 158 RKEMemoryLinkEnable_Req 0;
BA_ "GenSigTimeoutTime_SGW" SG_ 158 RKEMemoryLinkEnable_Req 0;
BA_ "GenSigTimeoutTime_TCM" SG_ 158 RKEMemoryLinkEnable_Req 0;
BA_ "GenSigSendType" SG_ 158 SOC_Max_Lev_Req 1;
BA_ "GenSigTimeoutTime_AGSM" SG_ 158 SOC_Max_Lev_Req 0;
BA_ "GenSigTimeoutTime_BCM" SG_ 158 SOC_Max_Lev_Req 0;
BA_ "GenSigTimeoutTime_BSM" SG_ 158 SOC_Max_Lev_Req 0;
BA_ "GenSigTimeoutTime_CADM" SG_ 158 SOC_Max_Lev_Req 0;
BA_ "GenSigTimeoutTime_DMSM" SG_ 158 SOC_Max_Lev_Req 0;
BA_ "GenSigTimeoutTime_DTCM" SG_ 158 SOC_Max_Lev_Req 0;
BA_ "GenSigTimeoutTime_ECM" SG_ 158 SOC_Max_Lev_Req 0;
BA_ "GenSigTimeoutTime_EVCU2" SG_ 158 SOC_Max_Lev_Req 0;
BA_ "GenSigTimeoutTime_GNMM" SG_ 158 SOC_Max_Lev_Req 0;
BA_ "GenSigTimeoutTime_HCP" SG_ 158 SOC_Max_Lev_Req 0;
BA_ "GenSigTimeoutTime_RFHM" SG_ 158 SOC_Max_Lev_Req 0;
BA_ "GenSigTimeoutTime_SGW" SG_ 158 SOC_Max_Lev_Req 0;
BA_ "GenSigTimeoutTime_TCM" SG_ 158 SOC_Max_Lev_Req 0;
BA_ "GenSigStartValue" SG_ 158 SoundHornLock_Req 1;
BA_ "GenSigSendType" SG_ 158 SoundHornLock_Req 1;
BA_ "GenSigTimeoutTime_AGSM" SG_ 158 SoundHornLock_Req 0;
BA_ "GenSigTimeoutTime_BCM" SG_ 158 SoundHornLock_Req 0;
BA_ "GenSigTimeoutTime_BSM" SG_ 158 SoundHornLock_Req 0;
BA_ "GenSigTimeoutTime_CADM" SG_ 158 SoundHornLock_Req 0;
BA_ "GenSigTimeoutTime_DMSM" SG_ 158 SoundHornLock_Req 0;
BA_ "GenSigTimeoutTime_DTCM" SG_ 158 SoundHornLock_Req 0;
BA_ "GenSigTimeoutTime_ECM" SG_ 158 SoundHornLock_Req 0;
BA_ "GenSigTimeoutTime_EVCU2" SG_ 158 SoundHornLock_Req 0;
BA_ "GenSigTimeoutTime_GNMM" SG_ 158 SoundHornLock_Req 0;
BA_ "GenSigTimeoutTime_HCP" SG_ 158 SoundHornLock_Req 0;
BA_ "GenSigTimeoutTime_RFHM" SG_ 158 SoundHornLock_Req 0;
BA_ "GenSigTimeoutTime_SGW" SG_ 158 SoundHornLock_Req 0;
BA_ "GenSigTimeoutTime_TCM" SG_ 158 SoundHornLock_Req 0;
BA_ "GenSigSendType" SG_ 158 SoundHornRemoteStart_Req 1;
BA_ "GenSigTimeoutTime_AGSM" SG_ 158 SoundHornRemoteStart_Req 0;
BA_ "GenSigTimeoutTime_BCM" SG_ 158 SoundHornRemoteStart_Req 0;
BA_ "GenSigTimeoutTime_BSM" SG_ 158 SoundHornRemoteStart_Req 0;
BA_ "GenSigTimeoutTime_CADM" SG_ 158 SoundHornRemoteStart_Req 0;
BA_ "GenSigTimeoutTime_DMSM" SG_ 158 SoundHornRemoteStart_Req 0;
BA_ "GenSigTimeoutTime_DTCM" SG_ 158 SoundHornRemoteStart_Req 0;
BA_ "GenSigTimeoutTime_ECM" SG_ 158 SoundHornRemoteStart_Req 0;
BA_ "GenSigTimeoutTime_EVCU2" SG_ 158 SoundHornRemoteStart_Req 0;
BA_ "GenSigTimeoutTime_GNMM" SG_ 158 SoundHornRemoteStart_Req 0;
BA_ "GenSigTimeoutTime_HCP" SG_ 158 SoundHornRemoteStart_Req 0;
BA_ "GenSigTimeoutTime_RFHM" SG_ 158 SoundHornRemoteStart_Req 0;
BA_ "GenSigTimeoutTime_SGW" SG_ 158 SoundHornRemoteStart_Req 0;
BA_ "GenSigTimeoutTime_TCM" SG_ 158 SoundHornRemoteStart_Req 0;
BA_ "GenSigSendType" SG_ 158 Speed_Unit_Req 3;
BA_ "GenSigTimeoutTime_AGSM" SG_ 158 Speed_Unit_Req 0;
BA_ "GenSigTimeoutTime_BCM" SG_ 158 Speed_Unit_Req 0;
BA_ "GenSigTimeoutTime_BSM" SG_ 158 Speed_Unit_Req 0;
BA_ "GenSigTimeoutTime_CADM" SG_ 158 Speed_Unit_Req 0;
BA_ "GenSigTimeoutTime_DMSM" SG_ 158 Speed_Unit_Req 0;
BA_ "GenSigTimeoutTime_DTCM" SG_ 158 Speed_Unit_Req 0;
BA_ "GenSigTimeoutTime_ECM" SG_ 158 Speed_Unit_Req 0;
BA_ "GenSigTimeoutTime_EVCU2" SG_ 158 Speed_Unit_Req 0;
BA_ "GenSigTimeoutTime_GNMM" SG_ 158 Speed_Unit_Req 0;
BA_ "GenSigTimeoutTime_HCP" SG_ 158 Speed_Unit_Req 0;
BA_ "GenSigTimeoutTime_RFHM" SG_ 158 Speed_Unit_Req 0;
BA_ "GenSigTimeoutTime_SGW" SG_ 158 Speed_Unit_Req 0;
BA_ "GenSigTimeoutTime_TCM" SG_ 158 Speed_Unit_Req 0;
BA_ "GenSigSendType" SG_ 158 SpeedLockDoorEnable_Req 1;
BA_ "GenSigTimeoutTime_AGSM" SG_ 158 SpeedLockDoorEnable_Req 0;
BA_ "GenSigTimeoutTime_BCM" SG_ 158 SpeedLockDoorEnable_Req 0;
BA_ "GenSigTimeoutTime_BSM" SG_ 158 SpeedLockDoorEnable_Req 0;
BA_ "GenSigTimeoutTime_CADM" SG_ 158 SpeedLockDoorEnable_Req 0;
BA_ "GenSigTimeoutTime_DMSM" SG_ 158 SpeedLockDoorEnable_Req 0;
BA_ "GenSigTimeoutTime_DTCM" SG_ 158 SpeedLockDoorEnable_Req 0;
BA_ "GenSigTimeoutTime_ECM" SG_ 158 SpeedLockDoorEnable_Req 0;
BA_ "GenSigTimeoutTime_EVCU2" SG_ 158 SpeedLockDoorEnable_Req 0;
BA_ "GenSigTimeoutTime_GNMM" SG_ 158 SpeedLockDoorEnable_Req 0;
BA_ "GenSigTimeoutTime_HCP" SG_ 158 SpeedLockDoorEnable_Req 0;
BA_ "GenSigTimeoutTime_RFHM" SG_ 158 SpeedLockDoorEnable_Req 0;
BA_ "GenSigTimeoutTime_SGW" SG_ 158 SpeedLockDoorEnable_Req 0;
BA_ "GenSigTimeoutTime_TCM" SG_ 158 SpeedLockDoorEnable_Req 0;
BA_ "GenSigSendType" SG_ 158 StaticGrid_Req 1;
BA_ "GenSigTimeoutTime_AGSM" SG_ 158 StaticGrid_Req 0;
BA_ "GenSigTimeoutTime_BCM" SG_ 158 StaticGrid_Req 0;
BA_ "GenSigTimeoutTime_BSM" SG_ 158 StaticGrid_Req 0;
BA_ "GenSigTimeoutTime_CADM" SG_ 158 StaticGrid_Req 0;
BA_ "GenSigTimeoutTime_DMSM" SG_ 158 StaticGrid_Req 0;
BA_ "GenSigTimeoutTime_DTCM" SG_ 158 StaticGrid_Req 0;
BA_ "GenSigTimeoutTime_ECM" SG_ 158 StaticGrid_Req 0;
BA_ "GenSigTimeoutTime_EVCU2" SG_ 158 StaticGrid_Req 0;
BA_ "GenSigTimeoutTime_GNMM" SG_ 158 StaticGrid_Req 0;
BA_ "GenSigTimeoutTime_HCP" SG_ 158 StaticGrid_Req 0;
BA_ "GenSigTimeoutTime_RFHM" SG_ 158 StaticGrid_Req 0;
BA_ "GenSigTimeoutTime_SGW" SG_ 158 StaticGrid_Req 0;
BA_ "GenSigTimeoutTime_TCM" SG_ 158 StaticGrid_Req 0;
BA_ "GenSigSendType" SG_ 158 Susp_Auto_Ent_Ext_Req 3;
BA_ "GenSigTimeoutTime_AGSM" SG_ 158 Susp_Auto_Ent_Ext_Req 0;
BA_ "GenSigTimeoutTime_BCM" SG_ 158 Susp_Auto_Ent_Ext_Req 0;
BA_ "GenSigTimeoutTime_BSM" SG_ 158 Susp_Auto_Ent_Ext_Req 0;
BA_ "GenSigTimeoutTime_CADM" SG_ 158 Susp_Auto_Ent_Ext_Req 0;
BA_ "GenSigTimeoutTime_DMSM" SG_ 158 Susp_Auto_Ent_Ext_Req 0;
BA_ "GenSigTimeoutTime_DTCM" SG_ 158 Susp_Auto_Ent_Ext_Req 0;
BA_ "GenSigTimeoutTime_ECM" SG_ 158 Susp_Auto_Ent_Ext_Req 0;
BA_ "GenSigTimeoutTime_EVCU2" SG_ 158 Susp_Auto_Ent_Ext_Req 0;
BA_ "GenSigTimeoutTime_GNMM" SG_ 158 Susp_Auto_Ent_Ext_Req 0;
BA_ "GenSigTimeoutTime_HCP" SG_ 158 Susp_Auto_Ent_Ext_Req 0;
BA_ "GenSigTimeoutTime_RFHM" SG_ 158 Susp_Auto_Ent_Ext_Req 0;
BA_ "GenSigTimeoutTime_SGW" SG_ 158 Susp_Auto_Ent_Ext_Req 0;
BA_ "GenSigTimeoutTime_TCM" SG_ 158 Susp_Auto_Ent_Ext_Req 0;
BA_ "GenSigSendType" SG_ 158 Susp_Disp_Message_Req 3;
BA_ "GenSigTimeoutTime_AGSM" SG_ 158 Susp_Disp_Message_Req 0;
BA_ "GenSigTimeoutTime_BCM" SG_ 158 Susp_Disp_Message_Req 0;
BA_ "GenSigTimeoutTime_BSM" SG_ 158 Susp_Disp_Message_Req 0;
BA_ "GenSigTimeoutTime_CADM" SG_ 158 Susp_Disp_Message_Req 0;
BA_ "GenSigTimeoutTime_DMSM" SG_ 158 Susp_Disp_Message_Req 0;
BA_ "GenSigTimeoutTime_DTCM" SG_ 158 Susp_Disp_Message_Req 0;
BA_ "GenSigTimeoutTime_ECM" SG_ 158 Susp_Disp_Message_Req 0;
BA_ "GenSigTimeoutTime_EVCU2" SG_ 158 Susp_Disp_Message_Req 0;
BA_ "GenSigTimeoutTime_GNMM" SG_ 158 Susp_Disp_Message_Req 0;
BA_ "GenSigTimeoutTime_HCP" SG_ 158 Susp_Disp_Message_Req 0;
BA_ "GenSigTimeoutTime_RFHM" SG_ 158 Susp_Disp_Message_Req 0;
BA_ "GenSigTimeoutTime_SGW" SG_ 158 Susp_Disp_Message_Req 0;
BA_ "GenSigTimeoutTime_TCM" SG_ 158 Susp_Disp_Message_Req 0;
BA_ "GenSigSendType" SG_ 158 Susp_Flsh_Lght_Low_Req 3;
BA_ "GenSigTimeoutTime_AGSM" SG_ 158 Susp_Flsh_Lght_Low_Req 0;
BA_ "GenSigTimeoutTime_BCM" SG_ 158 Susp_Flsh_Lght_Low_Req 0;
BA_ "GenSigTimeoutTime_BSM" SG_ 158 Susp_Flsh_Lght_Low_Req 0;
BA_ "GenSigTimeoutTime_CADM" SG_ 158 Susp_Flsh_Lght_Low_Req 0;
BA_ "GenSigTimeoutTime_DMSM" SG_ 158 Susp_Flsh_Lght_Low_Req 0;
BA_ "GenSigTimeoutTime_DTCM" SG_ 158 Susp_Flsh_Lght_Low_Req 0;
BA_ "GenSigTimeoutTime_ECM" SG_ 158 Susp_Flsh_Lght_Low_Req 0;
BA_ "GenSigTimeoutTime_EVCU2" SG_ 158 Susp_Flsh_Lght_Low_Req 0;
BA_ "GenSigTimeoutTime_GNMM" SG_ 158 Susp_Flsh_Lght_Low_Req 0;
BA_ "GenSigTimeoutTime_HCP" SG_ 158 Susp_Flsh_Lght_Low_Req 0;
BA_ "GenSigTimeoutTime_RFHM" SG_ 158 Susp_Flsh_Lght_Low_Req 0;
BA_ "GenSigTimeoutTime_SGW" SG_ 158 Susp_Flsh_Lght_Low_Req 0;
BA_ "GenSigTimeoutTime_TCM" SG_ 158 Susp_Flsh_Lght_Low_Req 0;
BA_ "GenSigSendType" SG_ 158 Susp_Sound_Hrn_Low_Req 3;
BA_ "GenSigTimeoutTime_AGSM" SG_ 158 Susp_Sound_Hrn_Low_Req 0;
BA_ "GenSigTimeoutTime_BCM" SG_ 158 Susp_Sound_Hrn_Low_Req 0;
BA_ "GenSigTimeoutTime_BSM" SG_ 158 Susp_Sound_Hrn_Low_Req 0;
BA_ "GenSigTimeoutTime_CADM" SG_ 158 Susp_Sound_Hrn_Low_Req 0;
BA_ "GenSigTimeoutTime_DMSM" SG_ 158 Susp_Sound_Hrn_Low_Req 0;
BA_ "GenSigTimeoutTime_DTCM" SG_ 158 Susp_Sound_Hrn_Low_Req 0;
BA_ "GenSigTimeoutTime_ECM" SG_ 158 Susp_Sound_Hrn_Low_Req 0;
BA_ "GenSigTimeoutTime_EVCU2" SG_ 158 Susp_Sound_Hrn_Low_Req 0;
BA_ "GenSigTimeoutTime_GNMM" SG_ 158 Susp_Sound_Hrn_Low_Req 0;
BA_ "GenSigTimeoutTime_HCP" SG_ 158 Susp_Sound_Hrn_Low_Req 0;
BA_ "GenSigTimeoutTime_RFHM" SG_ 158 Susp_Sound_Hrn_Low_Req 0;
BA_ "GenSigTimeoutTime_SGW" SG_ 158 Susp_Sound_Hrn_Low_Req 0;
BA_ "GenSigTimeoutTime_TCM" SG_ 158 Susp_Sound_Hrn_Low_Req 0;
BA_ "GenSigSendType" SG_ 158 Susp_Tire_Jack_Req 3;
BA_ "GenSigTimeoutTime_AGSM" SG_ 158 Susp_Tire_Jack_Req 0;
BA_ "GenSigTimeoutTime_BCM" SG_ 158 Susp_Tire_Jack_Req 0;
BA_ "GenSigTimeoutTime_BSM" SG_ 158 Susp_Tire_Jack_Req 0;
BA_ "GenSigTimeoutTime_CADM" SG_ 158 Susp_Tire_Jack_Req 0;
BA_ "GenSigTimeoutTime_DMSM" SG_ 158 Susp_Tire_Jack_Req 0;
BA_ "GenSigTimeoutTime_DTCM" SG_ 158 Susp_Tire_Jack_Req 0;
BA_ "GenSigTimeoutTime_ECM" SG_ 158 Susp_Tire_Jack_Req 0;
BA_ "GenSigTimeoutTime_EVCU2" SG_ 158 Susp_Tire_Jack_Req 0;
BA_ "GenSigTimeoutTime_GNMM" SG_ 158 Susp_Tire_Jack_Req 0;
BA_ "GenSigTimeoutTime_HCP" SG_ 158 Susp_Tire_Jack_Req 0;
BA_ "GenSigTimeoutTime_RFHM" SG_ 158 Susp_Tire_Jack_Req 0;
BA_ "GenSigTimeoutTime_SGW" SG_ 158 Susp_Tire_Jack_Req 0;
BA_ "GenSigTimeoutTime_TCM" SG_ 158 Susp_Tire_Jack_Req 0;
BA_ "GenSigSendType" SG_ 158 SVC_Delay_Req 3;
BA_ "GenSigTimeoutTime_AGSM" SG_ 158 SVC_Delay_Req 0;
BA_ "GenSigTimeoutTime_BCM" SG_ 158 SVC_Delay_Req 0;
BA_ "GenSigTimeoutTime_BSM" SG_ 158 SVC_Delay_Req 0;
BA_ "GenSigTimeoutTime_CADM" SG_ 158 SVC_Delay_Req 0;
BA_ "GenSigTimeoutTime_DMSM" SG_ 158 SVC_Delay_Req 0;
BA_ "GenSigTimeoutTime_DTCM" SG_ 158 SVC_Delay_Req 0;
BA_ "GenSigTimeoutTime_ECM" SG_ 158 SVC_Delay_Req 0;
BA_ "GenSigTimeoutTime_EVCU2" SG_ 158 SVC_Delay_Req 0;
BA_ "GenSigTimeoutTime_GNMM" SG_ 158 SVC_Delay_Req 0;
BA_ "GenSigTimeoutTime_HCP" SG_ 158 SVC_Delay_Req 0;
BA_ "GenSigTimeoutTime_RFHM" SG_ 158 SVC_Delay_Req 0;
BA_ "GenSigTimeoutTime_SGW" SG_ 158 SVC_Delay_Req 0;
BA_ "GenSigTimeoutTime_TCM" SG_ 158 SVC_Delay_Req 0;
BA_ "GenSigSendType" SG_ 158 SVC_Guidelines_Req 3;
BA_ "GenSigTimeoutTime_AGSM" SG_ 158 SVC_Guidelines_Req 0;
BA_ "GenSigTimeoutTime_BCM" SG_ 158 SVC_Guidelines_Req 0;
BA_ "GenSigTimeoutTime_BSM" SG_ 158 SVC_Guidelines_Req 0;
BA_ "GenSigTimeoutTime_CADM" SG_ 158 SVC_Guidelines_Req 0;
BA_ "GenSigTimeoutTime_DMSM" SG_ 158 SVC_Guidelines_Req 0;
BA_ "GenSigTimeoutTime_DTCM" SG_ 158 SVC_Guidelines_Req 0;
BA_ "GenSigTimeoutTime_ECM" SG_ 158 SVC_Guidelines_Req 0;
BA_ "GenSigTimeoutTime_EVCU2" SG_ 158 SVC_Guidelines_Req 0;
BA_ "GenSigTimeoutTime_GNMM" SG_ 158 SVC_Guidelines_Req 0;
BA_ "GenSigTimeoutTime_HCP" SG_ 158 SVC_Guidelines_Req 0;
BA_ "GenSigTimeoutTime_RFHM" SG_ 158 SVC_Guidelines_Req 0;
BA_ "GenSigTimeoutTime_SGW" SG_ 158 SVC_Guidelines_Req 0;
BA_ "GenSigTimeoutTime_TCM" SG_ 158 SVC_Guidelines_Req 0;
BA_ "GenSigSendType" SG_ 158 Temp_Unit_Req 3;
BA_ "GenSigTimeoutTime_AGSM" SG_ 158 Temp_Unit_Req 0;
BA_ "GenSigTimeoutTime_BCM" SG_ 158 Temp_Unit_Req 0;
BA_ "GenSigTimeoutTime_BSM" SG_ 158 Temp_Unit_Req 0;
BA_ "GenSigTimeoutTime_CADM" SG_ 158 Temp_Unit_Req 0;
BA_ "GenSigTimeoutTime_DMSM" SG_ 158 Temp_Unit_Req 0;
BA_ "GenSigTimeoutTime_DTCM" SG_ 158 Temp_Unit_Req 0;
BA_ "GenSigTimeoutTime_ECM" SG_ 158 Temp_Unit_Req 0;
BA_ "GenSigTimeoutTime_EVCU2" SG_ 158 Temp_Unit_Req 0;
BA_ "GenSigTimeoutTime_GNMM" SG_ 158 Temp_Unit_Req 0;
BA_ "GenSigTimeoutTime_HCP" SG_ 158 Temp_Unit_Req 0;
BA_ "GenSigTimeoutTime_RFHM" SG_ 158 Temp_Unit_Req 0;
BA_ "GenSigTimeoutTime_SGW" SG_ 158 Temp_Unit_Req 0;
BA_ "GenSigTimeoutTime_TCM" SG_ 158 Temp_Unit_Req 0;
BA_ "GenSigSendType" SG_ 158 Tilt_Mirr_Rev_Req 3;
BA_ "GenSigTimeoutTime_AGSM" SG_ 158 Tilt_Mirr_Rev_Req 0;
BA_ "GenSigTimeoutTime_BCM" SG_ 158 Tilt_Mirr_Rev_Req 0;
BA_ "GenSigTimeoutTime_BSM" SG_ 158 Tilt_Mirr_Rev_Req 0;
BA_ "GenSigTimeoutTime_CADM" SG_ 158 Tilt_Mirr_Rev_Req 0;
BA_ "GenSigTimeoutTime_DMSM" SG_ 158 Tilt_Mirr_Rev_Req 0;
BA_ "GenSigTimeoutTime_DTCM" SG_ 158 Tilt_Mirr_Rev_Req 0;
BA_ "GenSigTimeoutTime_ECM" SG_ 158 Tilt_Mirr_Rev_Req 0;
BA_ "GenSigTimeoutTime_EVCU2" SG_ 158 Tilt_Mirr_Rev_Req 0;
BA_ "GenSigTimeoutTime_GNMM" SG_ 158 Tilt_Mirr_Rev_Req 0;
BA_ "GenSigTimeoutTime_HCP" SG_ 158 Tilt_Mirr_Rev_Req 0;
BA_ "GenSigTimeoutTime_RFHM" SG_ 158 Tilt_Mirr_Rev_Req 0;
BA_ "GenSigTimeoutTime_SGW" SG_ 158 Tilt_Mirr_Rev_Req 0;
BA_ "GenSigTimeoutTime_TCM" SG_ 158 Tilt_Mirr_Rev_Req 0;
BA_ "GenSigSendType" SG_ 158 Tire_Fill_Alert_Req 3;
BA_ "GenSigTimeoutTime_AGSM" SG_ 158 Tire_Fill_Alert_Req 0;
BA_ "GenSigTimeoutTime_BCM" SG_ 158 Tire_Fill_Alert_Req 0;
BA_ "GenSigTimeoutTime_BSM" SG_ 158 Tire_Fill_Alert_Req 0;
BA_ "GenSigTimeoutTime_CADM" SG_ 158 Tire_Fill_Alert_Req 0;
BA_ "GenSigTimeoutTime_DMSM" SG_ 158 Tire_Fill_Alert_Req 0;
BA_ "GenSigTimeoutTime_DTCM" SG_ 158 Tire_Fill_Alert_Req 0;
BA_ "GenSigTimeoutTime_ECM" SG_ 158 Tire_Fill_Alert_Req 0;
BA_ "GenSigTimeoutTime_EVCU2" SG_ 158 Tire_Fill_Alert_Req 0;
BA_ "GenSigTimeoutTime_GNMM" SG_ 158 Tire_Fill_Alert_Req 0;
BA_ "GenSigTimeoutTime_HCP" SG_ 158 Tire_Fill_Alert_Req 0;
BA_ "GenSigTimeoutTime_RFHM" SG_ 158 Tire_Fill_Alert_Req 0;
BA_ "GenSigTimeoutTime_SGW" SG_ 158 Tire_Fill_Alert_Req 0;
BA_ "GenSigTimeoutTime_TCM" SG_ 158 Tire_Fill_Alert_Req 0;
BA_ "GenSigSendType" SG_ 158 Torque_Unit_Req 3;
BA_ "GenSigTimeoutTime_AGSM" SG_ 158 Torque_Unit_Req 0;
BA_ "GenSigTimeoutTime_BCM" SG_ 158 Torque_Unit_Req 0;
BA_ "GenSigTimeoutTime_BSM" SG_ 158 Torque_Unit_Req 0;
BA_ "GenSigTimeoutTime_CADM" SG_ 158 Torque_Unit_Req 0;
BA_ "GenSigTimeoutTime_DMSM" SG_ 158 Torque_Unit_Req 0;
BA_ "GenSigTimeoutTime_DTCM" SG_ 158 Torque_Unit_Req 0;
BA_ "GenSigTimeoutTime_ECM" SG_ 158 Torque_Unit_Req 0;
BA_ "GenSigTimeoutTime_EVCU2" SG_ 158 Torque_Unit_Req 0;
BA_ "GenSigTimeoutTime_GNMM" SG_ 158 Torque_Unit_Req 0;
BA_ "GenSigTimeoutTime_HCP" SG_ 158 Torque_Unit_Req 0;
BA_ "GenSigTimeoutTime_RFHM" SG_ 158 Torque_Unit_Req 0;
BA_ "GenSigTimeoutTime_SGW" SG_ 158 Torque_Unit_Req 0;
BA_ "GenSigTimeoutTime_TCM" SG_ 158 Torque_Unit_Req 0;
BA_ "GenSigSendType" SG_ 158 Traffic_Sign_Info_Req 3;
BA_ "GenSigTimeoutTime_AGSM" SG_ 158 Traffic_Sign_Info_Req 0;
BA_ "GenSigTimeoutTime_BCM" SG_ 158 Traffic_Sign_Info_Req 0;
BA_ "GenSigTimeoutTime_BSM" SG_ 158 Traffic_Sign_Info_Req 0;
BA_ "GenSigTimeoutTime_CADM" SG_ 158 Traffic_Sign_Info_Req 0;
BA_ "GenSigTimeoutTime_DMSM" SG_ 158 Traffic_Sign_Info_Req 0;
BA_ "GenSigTimeoutTime_DTCM" SG_ 158 Traffic_Sign_Info_Req 0;
BA_ "GenSigTimeoutTime_ECM" SG_ 158 Traffic_Sign_Info_Req 0;
BA_ "GenSigTimeoutTime_EVCU2" SG_ 158 Traffic_Sign_Info_Req 0;
BA_ "GenSigTimeoutTime_GNMM" SG_ 158 Traffic_Sign_Info_Req 0;
BA_ "GenSigTimeoutTime_HCP" SG_ 158 Traffic_Sign_Info_Req 0;
BA_ "GenSigTimeoutTime_RFHM" SG_ 158 Traffic_Sign_Info_Req 0;
BA_ "GenSigTimeoutTime_SGW" SG_ 158 Traffic_Sign_Info_Req 0;
BA_ "GenSigTimeoutTime_TCM" SG_ 158 Traffic_Sign_Info_Req 0;
BA_ "GenSigSendType" SG_ 158 Traffic_Sign_Warn_Req 3;
BA_ "GenSigTimeoutTime_AGSM" SG_ 158 Traffic_Sign_Warn_Req 0;
BA_ "GenSigTimeoutTime_BCM" SG_ 158 Traffic_Sign_Warn_Req 0;
BA_ "GenSigTimeoutTime_BSM" SG_ 158 Traffic_Sign_Warn_Req 0;
BA_ "GenSigTimeoutTime_CADM" SG_ 158 Traffic_Sign_Warn_Req 0;
BA_ "GenSigTimeoutTime_DMSM" SG_ 158 Traffic_Sign_Warn_Req 0;
BA_ "GenSigTimeoutTime_DTCM" SG_ 158 Traffic_Sign_Warn_Req 0;
BA_ "GenSigTimeoutTime_ECM" SG_ 158 Traffic_Sign_Warn_Req 0;
BA_ "GenSigTimeoutTime_EVCU2" SG_ 158 Traffic_Sign_Warn_Req 0;
BA_ "GenSigTimeoutTime_GNMM" SG_ 158 Traffic_Sign_Warn_Req 0;
BA_ "GenSigTimeoutTime_HCP" SG_ 158 Traffic_Sign_Warn_Req 0;
BA_ "GenSigTimeoutTime_RFHM" SG_ 158 Traffic_Sign_Warn_Req 0;
BA_ "GenSigTimeoutTime_SGW" SG_ 158 Traffic_Sign_Warn_Req 0;
BA_ "GenSigTimeoutTime_TCM" SG_ 158 Traffic_Sign_Warn_Req 0;
BA_ "GenSigSendType" SG_ 158 Trail_Brk_Type_Req 3;
BA_ "GenSigTimeoutTime_AGSM" SG_ 158 Trail_Brk_Type_Req 0;
BA_ "GenSigTimeoutTime_BCM" SG_ 158 Trail_Brk_Type_Req 0;
BA_ "GenSigTimeoutTime_BSM" SG_ 158 Trail_Brk_Type_Req 0;
BA_ "GenSigTimeoutTime_CADM" SG_ 158 Trail_Brk_Type_Req 0;
BA_ "GenSigTimeoutTime_DMSM" SG_ 158 Trail_Brk_Type_Req 0;
BA_ "GenSigTimeoutTime_DTCM" SG_ 158 Trail_Brk_Type_Req 0;
BA_ "GenSigTimeoutTime_ECM" SG_ 158 Trail_Brk_Type_Req 0;
BA_ "GenSigTimeoutTime_EVCU2" SG_ 158 Trail_Brk_Type_Req 0;
BA_ "GenSigTimeoutTime_GNMM" SG_ 158 Trail_Brk_Type_Req 0;
BA_ "GenSigTimeoutTime_HCP" SG_ 158 Trail_Brk_Type_Req 0;
BA_ "GenSigTimeoutTime_RFHM" SG_ 158 Trail_Brk_Type_Req 0;
BA_ "GenSigTimeoutTime_SGW" SG_ 158 Trail_Brk_Type_Req 0;
BA_ "GenSigTimeoutTime_TCM" SG_ 158 Trail_Brk_Type_Req 0;
BA_ "GenSigSendType" SG_ 158 Trail_Name_Req 3;
BA_ "GenSigTimeoutTime_AGSM" SG_ 158 Trail_Name_Req 0;
BA_ "GenSigTimeoutTime_BCM" SG_ 158 Trail_Name_Req 0;
BA_ "GenSigTimeoutTime_BSM" SG_ 158 Trail_Name_Req 0;
BA_ "GenSigTimeoutTime_CADM" SG_ 158 Trail_Name_Req 0;
BA_ "GenSigTimeoutTime_DMSM" SG_ 158 Trail_Name_Req 0;
BA_ "GenSigTimeoutTime_DTCM" SG_ 158 Trail_Name_Req 0;
BA_ "GenSigTimeoutTime_ECM" SG_ 158 Trail_Name_Req 0;
BA_ "GenSigTimeoutTime_EVCU2" SG_ 158 Trail_Name_Req 0;
BA_ "GenSigTimeoutTime_GNMM" SG_ 158 Trail_Name_Req 0;
BA_ "GenSigTimeoutTime_HCP" SG_ 158 Trail_Name_Req 0;
BA_ "GenSigTimeoutTime_RFHM" SG_ 158 Trail_Name_Req 0;
BA_ "GenSigTimeoutTime_SGW" SG_ 158 Trail_Name_Req 0;
BA_ "GenSigTimeoutTime_TCM" SG_ 158 Trail_Name_Req 0;
BA_ "GenSigSendType" SG_ 158 Trail_Num_Req 3;
BA_ "GenSigTimeoutTime_AGSM" SG_ 158 Trail_Num_Req 0;
BA_ "GenSigTimeoutTime_BCM" SG_ 158 Trail_Num_Req 0;
BA_ "GenSigTimeoutTime_BSM" SG_ 158 Trail_Num_Req 0;
BA_ "GenSigTimeoutTime_CADM" SG_ 158 Trail_Num_Req 0;
BA_ "GenSigTimeoutTime_DMSM" SG_ 158 Trail_Num_Req 0;
BA_ "GenSigTimeoutTime_DTCM" SG_ 158 Trail_Num_Req 0;
BA_ "GenSigTimeoutTime_ECM" SG_ 158 Trail_Num_Req 0;
BA_ "GenSigTimeoutTime_EVCU2" SG_ 158 Trail_Num_Req 0;
BA_ "GenSigTimeoutTime_GNMM" SG_ 158 Trail_Num_Req 0;
BA_ "GenSigTimeoutTime_HCP" SG_ 158 Trail_Num_Req 0;
BA_ "GenSigTimeoutTime_RFHM" SG_ 158 Trail_Num_Req 0;
BA_ "GenSigTimeoutTime_SGW" SG_ 158 Trail_Num_Req 0;
BA_ "GenSigTimeoutTime_TCM" SG_ 158 Trail_Num_Req 0;
BA_ "GenSigSendType" SG_ 158 Trailer_detection_blind_spot_Req 3;
BA_ "GenSigTimeoutTime_AGSM" SG_ 158 Trailer_detection_blind_spot_Req 0;
BA_ "GenSigTimeoutTime_BCM" SG_ 158 Trailer_detection_blind_spot_Req 0;
BA_ "GenSigTimeoutTime_BSM" SG_ 158 Trailer_detection_blind_spot_Req 0;
BA_ "GenSigTimeoutTime_CADM" SG_ 158 Trailer_detection_blind_spot_Req 0;
BA_ "GenSigTimeoutTime_DMSM" SG_ 158 Trailer_detection_blind_spot_Req 0;
BA_ "GenSigTimeoutTime_DTCM" SG_ 158 Trailer_detection_blind_spot_Req 0;
BA_ "GenSigTimeoutTime_ECM" SG_ 158 Trailer_detection_blind_spot_Req 0;
BA_ "GenSigTimeoutTime_EVCU2" SG_ 158 Trailer_detection_blind_spot_Req 0;
BA_ "GenSigTimeoutTime_GNMM" SG_ 158 Trailer_detection_blind_spot_Req 0;
BA_ "GenSigTimeoutTime_HCP" SG_ 158 Trailer_detection_blind_spot_Req 0;
BA_ "GenSigTimeoutTime_RFHM" SG_ 158 Trailer_detection_blind_spot_Req 0;
BA_ "GenSigTimeoutTime_SGW" SG_ 158 Trailer_detection_blind_spot_Req 0;
BA_ "GenSigTimeoutTime_TCM" SG_ 158 Trailer_detection_blind_spot_Req 0;
BA_ "GenSigSendType" SG_ 158 Trailer_Light_Check_Request 3;
BA_ "GenSigTimeoutTime_AGSM" SG_ 158 Trailer_Light_Check_Request 0;
BA_ "GenSigTimeoutTime_BSM" SG_ 158 Trailer_Light_Check_Request 0;
BA_ "GenSigTimeoutTime_CADM" SG_ 158 Trailer_Light_Check_Request 0;
BA_ "GenSigTimeoutTime_DMSM" SG_ 158 Trailer_Light_Check_Request 0;
BA_ "GenSigTimeoutTime_DTCM" SG_ 158 Trailer_Light_Check_Request 0;
BA_ "GenSigTimeoutTime_ECM" SG_ 158 Trailer_Light_Check_Request 0;
BA_ "GenSigTimeoutTime_EVCU2" SG_ 158 Trailer_Light_Check_Request 0;
BA_ "GenSigTimeoutTime_GNMM" SG_ 158 Trailer_Light_Check_Request 0;
BA_ "GenSigTimeoutTime_HCP" SG_ 158 Trailer_Light_Check_Request 0;
BA_ "GenSigTimeoutTime_IPC" SG_ 158 Trailer_Light_Check_Request 0;
BA_ "GenSigTimeoutTime_RFHM" SG_ 158 Trailer_Light_Check_Request 0;
BA_ "GenSigTimeoutTime_SGW" SG_ 158 Trailer_Light_Check_Request 0;
BA_ "GenSigTimeoutTime_TCM" SG_ 158 Trailer_Light_Check_Request 0;
BA_ "GenSigSendType" SG_ 158 TyrePress_Unit_Req 3;
BA_ "GenSigTimeoutTime_AGSM" SG_ 158 TyrePress_Unit_Req 0;
BA_ "GenSigTimeoutTime_BCM" SG_ 158 TyrePress_Unit_Req 0;
BA_ "GenSigTimeoutTime_BSM" SG_ 158 TyrePress_Unit_Req 0;
BA_ "GenSigTimeoutTime_CADM" SG_ 158 TyrePress_Unit_Req 0;
BA_ "GenSigTimeoutTime_DMSM" SG_ 158 TyrePress_Unit_Req 0;
BA_ "GenSigTimeoutTime_DTCM" SG_ 158 TyrePress_Unit_Req 0;
BA_ "GenSigTimeoutTime_ECM" SG_ 158 TyrePress_Unit_Req 0;
BA_ "GenSigTimeoutTime_EVCU2" SG_ 158 TyrePress_Unit_Req 0;
BA_ "GenSigTimeoutTime_GNMM" SG_ 158 TyrePress_Unit_Req 0;
BA_ "GenSigTimeoutTime_HCP" SG_ 158 TyrePress_Unit_Req 0;
BA_ "GenSigTimeoutTime_RFHM" SG_ 158 TyrePress_Unit_Req 0;
BA_ "GenSigTimeoutTime_SGW" SG_ 158 TyrePress_Unit_Req 0;
BA_ "GenSigTimeoutTime_TCM" SG_ 158 TyrePress_Unit_Req 0;
BA_ "GenSigStartValue" SG_ 2147484460 TrailerTirePress1 255;
BA_ "GenSigTimeoutTime_AGSM" SG_ 2147484460 TrailerTirePress1 0;
BA_ "GenSigTimeoutTime_BCM" SG_ 2147484460 TrailerTirePress1 0;
BA_ "GenSigTimeoutTime_BSM" SG_ 2147484460 TrailerTirePress1 0;
BA_ "GenSigTimeoutTime_CADM" SG_ 2147484460 TrailerTirePress1 0;
BA_ "GenSigTimeoutTime_DMSM" SG_ 2147484460 TrailerTirePress1 0;
BA_ "GenSigTimeoutTime_DTCM" SG_ 2147484460 TrailerTirePress1 0;
BA_ "GenSigTimeoutTime_ECM" SG_ 2147484460 TrailerTirePress1 0;
BA_ "GenSigTimeoutTime_EVCU2" SG_ 2147484460 TrailerTirePress1 0;
BA_ "GenSigTimeoutTime_GNMM" SG_ 2147484460 TrailerTirePress1 0;
BA_ "GenSigTimeoutTime_HCP" SG_ 2147484460 TrailerTirePress1 0;
BA_ "GenSigTimeoutTime_IPC" SG_ 2147484460 TrailerTirePress1 0;
BA_ "GenSigTimeoutTime_RFHM" SG_ 2147484460 TrailerTirePress1 0;
BA_ "GenSigTimeoutTime_TCM" SG_ 2147484460 TrailerTirePress1 0;
BA_ "GenSigStartValue" SG_ 2147484460 TrailerTirePress2 255;
BA_ "GenSigTimeoutTime_AGSM" SG_ 2147484460 TrailerTirePress2 0;
BA_ "GenSigTimeoutTime_BCM" SG_ 2147484460 TrailerTirePress2 0;
BA_ "GenSigTimeoutTime_BSM" SG_ 2147484460 TrailerTirePress2 0;
BA_ "GenSigTimeoutTime_CADM" SG_ 2147484460 TrailerTirePress2 0;
BA_ "GenSigTimeoutTime_DMSM" SG_ 2147484460 TrailerTirePress2 0;
BA_ "GenSigTimeoutTime_DTCM" SG_ 2147484460 TrailerTirePress2 0;
BA_ "GenSigTimeoutTime_ECM" SG_ 2147484460 TrailerTirePress2 0;
BA_ "GenSigTimeoutTime_EVCU2" SG_ 2147484460 TrailerTirePress2 0;
BA_ "GenSigTimeoutTime_GNMM" SG_ 2147484460 TrailerTirePress2 0;
BA_ "GenSigTimeoutTime_HCP" SG_ 2147484460 TrailerTirePress2 0;
BA_ "GenSigTimeoutTime_IPC" SG_ 2147484460 TrailerTirePress2 0;
BA_ "GenSigTimeoutTime_RFHM" SG_ 2147484460 TrailerTirePress2 0;
BA_ "GenSigTimeoutTime_TCM" SG_ 2147484460 TrailerTirePress2 0;
BA_ "GenSigStartValue" SG_ 2147484460 TrailerTirePress3 255;
BA_ "GenSigTimeoutTime_AGSM" SG_ 2147484460 TrailerTirePress3 0;
BA_ "GenSigTimeoutTime_BCM" SG_ 2147484460 TrailerTirePress3 0;
BA_ "GenSigTimeoutTime_BSM" SG_ 2147484460 TrailerTirePress3 0;
BA_ "GenSigTimeoutTime_CADM" SG_ 2147484460 TrailerTirePress3 0;
BA_ "GenSigTimeoutTime_DMSM" SG_ 2147484460 TrailerTirePress3 0;
BA_ "GenSigTimeoutTime_DTCM" SG_ 2147484460 TrailerTirePress3 0;
BA_ "GenSigTimeoutTime_ECM" SG_ 2147484460 TrailerTirePress3 0;
BA_ "GenSigTimeoutTime_EVCU2" SG_ 2147484460 TrailerTirePress3 0;
BA_ "GenSigTimeoutTime_GNMM" SG_ 2147484460 TrailerTirePress3 0;
BA_ "GenSigTimeoutTime_HCP" SG_ 2147484460 TrailerTirePress3 0;
BA_ "GenSigTimeoutTime_IPC" SG_ 2147484460 TrailerTirePress3 0;
BA_ "GenSigTimeoutTime_RFHM" SG_ 2147484460 TrailerTirePress3 0;
BA_ "GenSigTimeoutTime_TCM" SG_ 2147484460 TrailerTirePress3 0;
BA_ "GenSigStartValue" SG_ 2147484460 TrailerTirePress4 255;
BA_ "GenSigTimeoutTime_AGSM" SG_ 2147484460 TrailerTirePress4 0;
BA_ "GenSigTimeoutTime_BCM" SG_ 2147484460 TrailerTirePress4 0;
BA_ "GenSigTimeoutTime_BSM" SG_ 2147484460 TrailerTirePress4 0;
BA_ "GenSigTimeoutTime_CADM" SG_ 2147484460 TrailerTirePress4 0;
BA_ "GenSigTimeoutTime_DMSM" SG_ 2147484460 TrailerTirePress4 0;
BA_ "GenSigTimeoutTime_DTCM" SG_ 2147484460 TrailerTirePress4 0;
BA_ "GenSigTimeoutTime_ECM" SG_ 2147484460 TrailerTirePress4 0;
BA_ "GenSigTimeoutTime_EVCU2" SG_ 2147484460 TrailerTirePress4 0;
BA_ "GenSigTimeoutTime_GNMM" SG_ 2147484460 TrailerTirePress4 0;
BA_ "GenSigTimeoutTime_HCP" SG_ 2147484460 TrailerTirePress4 0;
BA_ "GenSigTimeoutTime_IPC" SG_ 2147484460 TrailerTirePress4 0;
BA_ "GenSigTimeoutTime_RFHM" SG_ 2147484460 TrailerTirePress4 0;
BA_ "GenSigTimeoutTime_TCM" SG_ 2147484460 TrailerTirePress4 0;
BA_ "GenSigStartValue" SG_ 2147484460 TrailerTirePress5 255;
BA_ "GenSigTimeoutTime_AGSM" SG_ 2147484460 TrailerTirePress5 0;
BA_ "GenSigTimeoutTime_BCM" SG_ 2147484460 TrailerTirePress5 0;
BA_ "GenSigTimeoutTime_BSM" SG_ 2147484460 TrailerTirePress5 0;
BA_ "GenSigTimeoutTime_CADM" SG_ 2147484460 TrailerTirePress5 0;
BA_ "GenSigTimeoutTime_DMSM" SG_ 2147484460 TrailerTirePress5 0;
BA_ "GenSigTimeoutTime_DTCM" SG_ 2147484460 TrailerTirePress5 0;
BA_ "GenSigTimeoutTime_ECM" SG_ 2147484460 TrailerTirePress5 0;
BA_ "GenSigTimeoutTime_EVCU2" SG_ 2147484460 TrailerTirePress5 0;
BA_ "GenSigTimeoutTime_GNMM" SG_ 2147484460 TrailerTirePress5 0;
BA_ "GenSigTimeoutTime_HCP" SG_ 2147484460 TrailerTirePress5 0;
BA_ "GenSigTimeoutTime_IPC" SG_ 2147484460 TrailerTirePress5 0;
BA_ "GenSigTimeoutTime_RFHM" SG_ 2147484460 TrailerTirePress5 0;
BA_ "GenSigTimeoutTime_TCM" SG_ 2147484460 TrailerTirePress5 0;
BA_ "GenSigStartValue" SG_ 2147484460 TrailerTirePress6 255;
BA_ "GenSigTimeoutTime_AGSM" SG_ 2147484460 TrailerTirePress6 0;
BA_ "GenSigTimeoutTime_BCM" SG_ 2147484460 TrailerTirePress6 0;
BA_ "GenSigTimeoutTime_BSM" SG_ 2147484460 TrailerTirePress6 0;
BA_ "GenSigTimeoutTime_CADM" SG_ 2147484460 TrailerTirePress6 0;
BA_ "GenSigTimeoutTime_DMSM" SG_ 2147484460 TrailerTirePress6 0;
BA_ "GenSigTimeoutTime_DTCM" SG_ 2147484460 TrailerTirePress6 0;
BA_ "GenSigTimeoutTime_ECM" SG_ 2147484460 TrailerTirePress6 0;
BA_ "GenSigTimeoutTime_EVCU2" SG_ 2147484460 TrailerTirePress6 0;
BA_ "GenSigTimeoutTime_GNMM" SG_ 2147484460 TrailerTirePress6 0;
BA_ "GenSigTimeoutTime_HCP" SG_ 2147484460 TrailerTirePress6 0;
BA_ "GenSigTimeoutTime_IPC" SG_ 2147484460 TrailerTirePress6 0;
BA_ "GenSigTimeoutTime_RFHM" SG_ 2147484460 TrailerTirePress6 0;
BA_ "GenSigTimeoutTime_TCM" SG_ 2147484460 TrailerTirePress6 0;
BA_ "GenSigTimeoutTime_AGSM" SG_ 2147484460 TrlTire1_Stat 0;
BA_ "GenSigTimeoutTime_BCM" SG_ 2147484460 TrlTire1_Stat 0;
BA_ "GenSigTimeoutTime_BSM" SG_ 2147484460 TrlTire1_Stat 0;
BA_ "GenSigTimeoutTime_CADM" SG_ 2147484460 TrlTire1_Stat 0;
BA_ "GenSigTimeoutTime_DMSM" SG_ 2147484460 TrlTire1_Stat 0;
BA_ "GenSigTimeoutTime_DTCM" SG_ 2147484460 TrlTire1_Stat 0;
BA_ "GenSigTimeoutTime_ECM" SG_ 2147484460 TrlTire1_Stat 0;
BA_ "GenSigTimeoutTime_EVCU2" SG_ 2147484460 TrlTire1_Stat 0;
BA_ "GenSigTimeoutTime_GNMM" SG_ 2147484460 TrlTire1_Stat 0;
BA_ "GenSigTimeoutTime_HCP" SG_ 2147484460 TrlTire1_Stat 0;
BA_ "GenSigTimeoutTime_IPC" SG_ 2147484460 TrlTire1_Stat 0;
BA_ "GenSigTimeoutTime_RFHM" SG_ 2147484460 TrlTire1_Stat 0;
BA_ "GenSigTimeoutTime_TCM" SG_ 2147484460 TrlTire1_Stat 0;
BA_ "GenSigTimeoutTime_AGSM" SG_ 2147484460 TrlTire2_Stat 0;
BA_ "GenSigTimeoutTime_BCM" SG_ 2147484460 TrlTire2_Stat 0;
BA_ "GenSigTimeoutTime_BSM" SG_ 2147484460 TrlTire2_Stat 0;
BA_ "GenSigTimeoutTime_CADM" SG_ 2147484460 TrlTire2_Stat 0;
BA_ "GenSigTimeoutTime_DMSM" SG_ 2147484460 TrlTire2_Stat 0;
BA_ "GenSigTimeoutTime_DTCM" SG_ 2147484460 TrlTire2_Stat 0;
BA_ "GenSigTimeoutTime_ECM" SG_ 2147484460 TrlTire2_Stat 0;
BA_ "GenSigTimeoutTime_EVCU2" SG_ 2147484460 TrlTire2_Stat 0;
BA_ "GenSigTimeoutTime_GNMM" SG_ 2147484460 TrlTire2_Stat 0;
BA_ "GenSigTimeoutTime_HCP" SG_ 2147484460 TrlTire2_Stat 0;
BA_ "GenSigTimeoutTime_IPC" SG_ 2147484460 TrlTire2_Stat 0;
BA_ "GenSigTimeoutTime_RFHM" SG_ 2147484460 TrlTire2_Stat 0;
BA_ "GenSigTimeoutTime_TCM" SG_ 2147484460 TrlTire2_Stat 0;
BA_ "GenSigTimeoutTime_AGSM" SG_ 2147484460 TrlTire3_Stat 0;
BA_ "GenSigTimeoutTime_BCM" SG_ 2147484460 TrlTire3_Stat 0;
BA_ "GenSigTimeoutTime_BSM" SG_ 2147484460 TrlTire3_Stat 0;
BA_ "GenSigTimeoutTime_CADM" SG_ 2147484460 TrlTire3_Stat 0;
BA_ "GenSigTimeoutTime_DMSM" SG_ 2147484460 TrlTire3_Stat 0;
BA_ "GenSigTimeoutTime_DTCM" SG_ 2147484460 TrlTire3_Stat 0;
BA_ "GenSigTimeoutTime_ECM" SG_ 2147484460 TrlTire3_Stat 0;
BA_ "GenSigTimeoutTime_EVCU2" SG_ 2147484460 TrlTire3_Stat 0;
BA_ "GenSigTimeoutTime_GNMM" SG_ 2147484460 TrlTire3_Stat 0;
BA_ "GenSigTimeoutTime_HCP" SG_ 2147484460 TrlTire3_Stat 0;
BA_ "GenSigTimeoutTime_IPC" SG_ 2147484460 TrlTire3_Stat 0;
BA_ "GenSigTimeoutTime_RFHM" SG_ 2147484460 TrlTire3_Stat 0;
BA_ "GenSigTimeoutTime_TCM" SG_ 2147484460 TrlTire3_Stat 0;
BA_ "GenSigTimeoutTime_AGSM" SG_ 2147484460 TrlTire4_Stat 0;
BA_ "GenSigTimeoutTime_BCM" SG_ 2147484460 TrlTire4_Stat 0;
BA_ "GenSigTimeoutTime_BSM" SG_ 2147484460 TrlTire4_Stat 0;
BA_ "GenSigTimeoutTime_CADM" SG_ 2147484460 TrlTire4_Stat 0;
BA_ "GenSigTimeoutTime_DMSM" SG_ 2147484460 TrlTire4_Stat 0;
BA_ "GenSigTimeoutTime_DTCM" SG_ 2147484460 TrlTire4_Stat 0;
BA_ "GenSigTimeoutTime_ECM" SG_ 2147484460 TrlTire4_Stat 0;
BA_ "GenSigTimeoutTime_EVCU2" SG_ 2147484460 TrlTire4_Stat 0;
BA_ "GenSigTimeoutTime_GNMM" SG_ 2147484460 TrlTire4_Stat 0;
BA_ "GenSigTimeoutTime_HCP" SG_ 2147484460 TrlTire4_Stat 0;
BA_ "GenSigTimeoutTime_IPC" SG_ 2147484460 TrlTire4_Stat 0;
BA_ "GenSigTimeoutTime_RFHM" SG_ 2147484460 TrlTire4_Stat 0;
BA_ "GenSigTimeoutTime_TCM" SG_ 2147484460 TrlTire4_Stat 0;
BA_ "GenSigTimeoutTime_AGSM" SG_ 2147484460 TrlTire5_Stat 0;
BA_ "GenSigTimeoutTime_BCM" SG_ 2147484460 TrlTire5_Stat 0;
BA_ "GenSigTimeoutTime_BSM" SG_ 2147484460 TrlTire5_Stat 0;
BA_ "GenSigTimeoutTime_CADM" SG_ 2147484460 TrlTire5_Stat 0;
BA_ "GenSigTimeoutTime_DMSM" SG_ 2147484460 TrlTire5_Stat 0;
BA_ "GenSigTimeoutTime_DTCM" SG_ 2147484460 TrlTire5_Stat 0;
BA_ "GenSigTimeoutTime_ECM" SG_ 2147484460 TrlTire5_Stat 0;
BA_ "GenSigTimeoutTime_EVCU2" SG_ 2147484460 TrlTire5_Stat 0;
BA_ "GenSigTimeoutTime_GNMM" SG_ 2147484460 TrlTire5_Stat 0;
BA_ "GenSigTimeoutTime_HCP" SG_ 2147484460 TrlTire5_Stat 0;
BA_ "GenSigTimeoutTime_IPC" SG_ 2147484460 TrlTire5_Stat 0;
BA_ "GenSigTimeoutTime_RFHM" SG_ 2147484460 TrlTire5_Stat 0;
BA_ "GenSigTimeoutTime_TCM" SG_ 2147484460 TrlTire5_Stat 0;
BA_ "GenSigTimeoutTime_AGSM" SG_ 2147484460 TrlTire6_Stat 0;
BA_ "GenSigTimeoutTime_BCM" SG_ 2147484460 TrlTire6_Stat 0;
BA_ "GenSigTimeoutTime_BSM" SG_ 2147484460 TrlTire6_Stat 0;
BA_ "GenSigTimeoutTime_CADM" SG_ 2147484460 TrlTire6_Stat 0;
BA_ "GenSigTimeoutTime_DMSM" SG_ 2147484460 TrlTire6_Stat 0;
BA_ "GenSigTimeoutTime_DTCM" SG_ 2147484460 TrlTire6_Stat 0;
BA_ "GenSigTimeoutTime_ECM" SG_ 2147484460 TrlTire6_Stat 0;
BA_ "GenSigTimeoutTime_EVCU2" SG_ 2147484460 TrlTire6_Stat 0;
BA_ "GenSigTimeoutTime_GNMM" SG_ 2147484460 TrlTire6_Stat 0;
BA_ "GenSigTimeoutTime_HCP" SG_ 2147484460 TrlTire6_Stat 0;
BA_ "GenSigTimeoutTime_IPC" SG_ 2147484460 TrlTire6_Stat 0;
BA_ "GenSigTimeoutTime_RFHM" SG_ 2147484460 TrlTire6_Stat 0;
BA_ "GenSigTimeoutTime_TCM" SG_ 2147484460 TrlTire6_Stat 0;
BA_ "GenSigStartValue" SG_ 2147484461 TrailerTirePress10 255;
BA_ "GenSigTimeoutTime_AGSM" SG_ 2147484461 TrailerTirePress10 0;
BA_ "GenSigTimeoutTime_BCM" SG_ 2147484461 TrailerTirePress10 0;
BA_ "GenSigTimeoutTime_BSM" SG_ 2147484461 TrailerTirePress10 0;
BA_ "GenSigTimeoutTime_CADM" SG_ 2147484461 TrailerTirePress10 0;
BA_ "GenSigTimeoutTime_DMSM" SG_ 2147484461 TrailerTirePress10 0;
BA_ "GenSigTimeoutTime_DTCM" SG_ 2147484461 TrailerTirePress10 0;
BA_ "GenSigTimeoutTime_ECM" SG_ 2147484461 TrailerTirePress10 0;
BA_ "GenSigTimeoutTime_EVCU2" SG_ 2147484461 TrailerTirePress10 0;
BA_ "GenSigTimeoutTime_GNMM" SG_ 2147484461 TrailerTirePress10 0;
BA_ "GenSigTimeoutTime_HCP" SG_ 2147484461 TrailerTirePress10 0;
BA_ "GenSigTimeoutTime_IPC" SG_ 2147484461 TrailerTirePress10 0;
BA_ "GenSigTimeoutTime_RFHM" SG_ 2147484461 TrailerTirePress10 0;
BA_ "GenSigTimeoutTime_TCM" SG_ 2147484461 TrailerTirePress10 0;
BA_ "GenSigStartValue" SG_ 2147484461 TrailerTirePress11 255;
BA_ "GenSigTimeoutTime_AGSM" SG_ 2147484461 TrailerTirePress11 0;
BA_ "GenSigTimeoutTime_BCM" SG_ 2147484461 TrailerTirePress11 0;
BA_ "GenSigTimeoutTime_BSM" SG_ 2147484461 TrailerTirePress11 0;
BA_ "GenSigTimeoutTime_CADM" SG_ 2147484461 TrailerTirePress11 0;
BA_ "GenSigTimeoutTime_DMSM" SG_ 2147484461 TrailerTirePress11 0;
BA_ "GenSigTimeoutTime_DTCM" SG_ 2147484461 TrailerTirePress11 0;
BA_ "GenSigTimeoutTime_ECM" SG_ 2147484461 TrailerTirePress11 0;
BA_ "GenSigTimeoutTime_EVCU2" SG_ 2147484461 TrailerTirePress11 0;
BA_ "GenSigTimeoutTime_GNMM" SG_ 2147484461 TrailerTirePress11 0;
BA_ "GenSigTimeoutTime_HCP" SG_ 2147484461 TrailerTirePress11 0;
BA_ "GenSigTimeoutTime_IPC" SG_ 2147484461 TrailerTirePress11 0;
BA_ "GenSigTimeoutTime_RFHM" SG_ 2147484461 TrailerTirePress11 0;
BA_ "GenSigTimeoutTime_TCM" SG_ 2147484461 TrailerTirePress11 0;
BA_ "GenSigStartValue" SG_ 2147484461 TrailerTirePress12 255;
BA_ "GenSigTimeoutTime_AGSM" SG_ 2147484461 TrailerTirePress12 0;
BA_ "GenSigTimeoutTime_BCM" SG_ 2147484461 TrailerTirePress12 0;
BA_ "GenSigTimeoutTime_BSM" SG_ 2147484461 TrailerTirePress12 0;
BA_ "GenSigTimeoutTime_CADM" SG_ 2147484461 TrailerTirePress12 0;
BA_ "GenSigTimeoutTime_DMSM" SG_ 2147484461 TrailerTirePress12 0;
BA_ "GenSigTimeoutTime_DTCM" SG_ 2147484461 TrailerTirePress12 0;
BA_ "GenSigTimeoutTime_ECM" SG_ 2147484461 TrailerTirePress12 0;
BA_ "GenSigTimeoutTime_EVCU2" SG_ 2147484461 TrailerTirePress12 0;
BA_ "GenSigTimeoutTime_GNMM" SG_ 2147484461 TrailerTirePress12 0;
BA_ "GenSigTimeoutTime_HCP" SG_ 2147484461 TrailerTirePress12 0;
BA_ "GenSigTimeoutTime_IPC" SG_ 2147484461 TrailerTirePress12 0;
BA_ "GenSigTimeoutTime_RFHM" SG_ 2147484461 TrailerTirePress12 0;
BA_ "GenSigTimeoutTime_TCM" SG_ 2147484461 TrailerTirePress12 0;
BA_ "GenSigStartValue" SG_ 2147484461 TrailerTirePress7 255;
BA_ "GenSigTimeoutTime_AGSM" SG_ 2147484461 TrailerTirePress7 0;
BA_ "GenSigTimeoutTime_BCM" SG_ 2147484461 TrailerTirePress7 0;
BA_ "GenSigTimeoutTime_BSM" SG_ 2147484461 TrailerTirePress7 0;
BA_ "GenSigTimeoutTime_CADM" SG_ 2147484461 TrailerTirePress7 0;
BA_ "GenSigTimeoutTime_DMSM" SG_ 2147484461 TrailerTirePress7 0;
BA_ "GenSigTimeoutTime_DTCM" SG_ 2147484461 TrailerTirePress7 0;
BA_ "GenSigTimeoutTime_ECM" SG_ 2147484461 TrailerTirePress7 0;
BA_ "GenSigTimeoutTime_EVCU2" SG_ 2147484461 TrailerTirePress7 0;
BA_ "GenSigTimeoutTime_GNMM" SG_ 2147484461 TrailerTirePress7 0;
BA_ "GenSigTimeoutTime_HCP" SG_ 2147484461 TrailerTirePress7 0;
BA_ "GenSigTimeoutTime_IPC" SG_ 2147484461 TrailerTirePress7 0;
BA_ "GenSigTimeoutTime_RFHM" SG_ 2147484461 TrailerTirePress7 0;
BA_ "GenSigTimeoutTime_TCM" SG_ 2147484461 TrailerTirePress7 0;
BA_ "GenSigStartValue" SG_ 2147484461 TrailerTirePress8 255;
BA_ "GenSigTimeoutTime_AGSM" SG_ 2147484461 TrailerTirePress8 0;
BA_ "GenSigTimeoutTime_BCM" SG_ 2147484461 TrailerTirePress8 0;
BA_ "GenSigTimeoutTime_BSM" SG_ 2147484461 TrailerTirePress8 0;
BA_ "GenSigTimeoutTime_CADM" SG_ 2147484461 TrailerTirePress8 0;
BA_ "GenSigTimeoutTime_DMSM" SG_ 2147484461 TrailerTirePress8 0;
BA_ "GenSigTimeoutTime_DTCM" SG_ 2147484461 TrailerTirePress8 0;
BA_ "GenSigTimeoutTime_ECM" SG_ 2147484461 TrailerTirePress8 0;
BA_ "GenSigTimeoutTime_EVCU2" SG_ 2147484461 TrailerTirePress8 0;
BA_ "GenSigTimeoutTime_GNMM" SG_ 2147484461 TrailerTirePress8 0;
BA_ "GenSigTimeoutTime_HCP" SG_ 2147484461 TrailerTirePress8 0;
BA_ "GenSigTimeoutTime_IPC" SG_ 2147484461 TrailerTirePress8 0;
BA_ "GenSigTimeoutTime_RFHM" SG_ 2147484461 TrailerTirePress8 0;
BA_ "GenSigTimeoutTime_TCM" SG_ 2147484461 TrailerTirePress8 0;
BA_ "GenSigStartValue" SG_ 2147484461 TrailerTirePress9 255;
BA_ "GenSigTimeoutTime_AGSM" SG_ 2147484461 TrailerTirePress9 0;
BA_ "GenSigTimeoutTime_BCM" SG_ 2147484461 TrailerTirePress9 0;
BA_ "GenSigTimeoutTime_BSM" SG_ 2147484461 TrailerTirePress9 0;
BA_ "GenSigTimeoutTime_CADM" SG_ 2147484461 TrailerTirePress9 0;
BA_ "GenSigTimeoutTime_DMSM" SG_ 2147484461 TrailerTirePress9 0;
BA_ "GenSigTimeoutTime_DTCM" SG_ 2147484461 TrailerTirePress9 0;
BA_ "GenSigTimeoutTime_ECM" SG_ 2147484461 TrailerTirePress9 0;
BA_ "GenSigTimeoutTime_EVCU2" SG_ 2147484461 TrailerTirePress9 0;
BA_ "GenSigTimeoutTime_GNMM" SG_ 2147484461 TrailerTirePress9 0;
BA_ "GenSigTimeoutTime_HCP" SG_ 2147484461 TrailerTirePress9 0;
BA_ "GenSigTimeoutTime_IPC" SG_ 2147484461 TrailerTirePress9 0;
BA_ "GenSigTimeoutTime_RFHM" SG_ 2147484461 TrailerTirePress9 0;
BA_ "GenSigTimeoutTime_TCM" SG_ 2147484461 TrailerTirePress9 0;
BA_ "GenSigTimeoutTime_AGSM" SG_ 2147484461 TrlTire10_Stat 0;
BA_ "GenSigTimeoutTime_BCM" SG_ 2147484461 TrlTire10_Stat 0;
BA_ "GenSigTimeoutTime_BSM" SG_ 2147484461 TrlTire10_Stat 0;
BA_ "GenSigTimeoutTime_CADM" SG_ 2147484461 TrlTire10_Stat 0;
BA_ "GenSigTimeoutTime_DMSM" SG_ 2147484461 TrlTire10_Stat 0;
BA_ "GenSigTimeoutTime_DTCM" SG_ 2147484461 TrlTire10_Stat 0;
BA_ "GenSigTimeoutTime_ECM" SG_ 2147484461 TrlTire10_Stat 0;
BA_ "GenSigTimeoutTime_EVCU2" SG_ 2147484461 TrlTire10_Stat 0;
BA_ "GenSigTimeoutTime_GNMM" SG_ 2147484461 TrlTire10_Stat 0;
BA_ "GenSigTimeoutTime_HCP" SG_ 2147484461 TrlTire10_Stat 0;
BA_ "GenSigTimeoutTime_IPC" SG_ 2147484461 TrlTire10_Stat 0;
BA_ "GenSigTimeoutTime_RFHM" SG_ 2147484461 TrlTire10_Stat 0;
BA_ "GenSigTimeoutTime_TCM" SG_ 2147484461 TrlTire10_Stat 0;
BA_ "GenSigTimeoutTime_AGSM" SG_ 2147484461 TrlTire11_Stat 0;
BA_ "GenSigTimeoutTime_BCM" SG_ 2147484461 TrlTire11_Stat 0;
BA_ "GenSigTimeoutTime_BSM" SG_ 2147484461 TrlTire11_Stat 0;
BA_ "GenSigTimeoutTime_CADM" SG_ 2147484461 TrlTire11_Stat 0;
BA_ "GenSigTimeoutTime_DMSM" SG_ 2147484461 TrlTire11_Stat 0;
BA_ "GenSigTimeoutTime_DTCM" SG_ 2147484461 TrlTire11_Stat 0;
BA_ "GenSigTimeoutTime_ECM" SG_ 2147484461 TrlTire11_Stat 0;
BA_ "GenSigTimeoutTime_EVCU2" SG_ 2147484461 TrlTire11_Stat 0;
BA_ "GenSigTimeoutTime_GNMM" SG_ 2147484461 TrlTire11_Stat 0;
BA_ "GenSigTimeoutTime_HCP" SG_ 2147484461 TrlTire11_Stat 0;
BA_ "GenSigTimeoutTime_IPC" SG_ 2147484461 TrlTire11_Stat 0;
BA_ "GenSigTimeoutTime_RFHM" SG_ 2147484461 TrlTire11_Stat 0;
BA_ "GenSigTimeoutTime_TCM" SG_ 2147484461 TrlTire11_Stat 0;
BA_ "GenSigTimeoutTime_AGSM" SG_ 2147484461 TrlTire12_Stat 0;
BA_ "GenSigTimeoutTime_BCM" SG_ 2147484461 TrlTire12_Stat 0;
BA_ "GenSigTimeoutTime_BSM" SG_ 2147484461 TrlTire12_Stat 0;
BA_ "GenSigTimeoutTime_CADM" SG_ 2147484461 TrlTire12_Stat 0;
BA_ "GenSigTimeoutTime_DMSM" SG_ 2147484461 TrlTire12_Stat 0;
BA_ "GenSigTimeoutTime_DTCM" SG_ 2147484461 TrlTire12_Stat 0;
BA_ "GenSigTimeoutTime_ECM" SG_ 2147484461 TrlTire12_Stat 0;
BA_ "GenSigTimeoutTime_EVCU2" SG_ 2147484461 TrlTire12_Stat 0;
BA_ "GenSigTimeoutTime_GNMM" SG_ 2147484461 TrlTire12_Stat 0;
BA_ "GenSigTimeoutTime_HCP" SG_ 2147484461 TrlTire12_Stat 0;
BA_ "GenSigTimeoutTime_IPC" SG_ 2147484461 TrlTire12_Stat 0;
BA_ "GenSigTimeoutTime_RFHM" SG_ 2147484461 TrlTire12_Stat 0;
BA_ "GenSigTimeoutTime_TCM" SG_ 2147484461 TrlTire12_Stat 0;
BA_ "GenSigTimeoutTime_AGSM" SG_ 2147484461 TrlTire7_Stat 0;
BA_ "GenSigTimeoutTime_BCM" SG_ 2147484461 TrlTire7_Stat 0;
BA_ "GenSigTimeoutTime_BSM" SG_ 2147484461 TrlTire7_Stat 0;
BA_ "GenSigTimeoutTime_CADM" SG_ 2147484461 TrlTire7_Stat 0;
BA_ "GenSigTimeoutTime_DMSM" SG_ 2147484461 TrlTire7_Stat 0;
BA_ "GenSigTimeoutTime_DTCM" SG_ 2147484461 TrlTire7_Stat 0;
BA_ "GenSigTimeoutTime_ECM" SG_ 2147484461 TrlTire7_Stat 0;
BA_ "GenSigTimeoutTime_EVCU2" SG_ 2147484461 TrlTire7_Stat 0;
BA_ "GenSigTimeoutTime_GNMM" SG_ 2147484461 TrlTire7_Stat 0;
BA_ "GenSigTimeoutTime_HCP" SG_ 2147484461 TrlTire7_Stat 0;
BA_ "GenSigTimeoutTime_IPC" SG_ 2147484461 TrlTire7_Stat 0;
BA_ "GenSigTimeoutTime_RFHM" SG_ 2147484461 TrlTire7_Stat 0;
BA_ "GenSigTimeoutTime_TCM" SG_ 2147484461 TrlTire7_Stat 0;
BA_ "GenSigTimeoutTime_AGSM" SG_ 2147484461 TrlTire8_Stat 0;
BA_ "GenSigTimeoutTime_BCM" SG_ 2147484461 TrlTire8_Stat 0;
BA_ "GenSigTimeoutTime_BSM" SG_ 2147484461 TrlTire8_Stat 0;
BA_ "GenSigTimeoutTime_CADM" SG_ 2147484461 TrlTire8_Stat 0;
BA_ "GenSigTimeoutTime_DMSM" SG_ 2147484461 TrlTire8_Stat 0;
BA_ "GenSigTimeoutTime_DTCM" SG_ 2147484461 TrlTire8_Stat 0;
BA_ "GenSigTimeoutTime_ECM" SG_ 2147484461 TrlTire8_Stat 0;
BA_ "GenSigTimeoutTime_EVCU2" SG_ 2147484461 TrlTire8_Stat 0;
BA_ "GenSigTimeoutTime_GNMM" SG_ 2147484461 TrlTire8_Stat 0;
BA_ "GenSigTimeoutTime_HCP" SG_ 2147484461 TrlTire8_Stat 0;
BA_ "GenSigTimeoutTime_IPC" SG_ 2147484461 TrlTire8_Stat 0;
BA_ "GenSigTimeoutTime_RFHM" SG_ 2147484461 TrlTire8_Stat 0;
BA_ "GenSigTimeoutTime_TCM" SG_ 2147484461 TrlTire8_Stat 0;
BA_ "GenSigTimeoutTime_AGSM" SG_ 2147484461 TrlTire9_Stat 0;
BA_ "GenSigTimeoutTime_BCM" SG_ 2147484461 TrlTire9_Stat 0;
BA_ "GenSigTimeoutTime_BSM" SG_ 2147484461 TrlTire9_Stat 0;
BA_ "GenSigTimeoutTime_CADM" SG_ 2147484461 TrlTire9_Stat 0;
BA_ "GenSigTimeoutTime_DMSM" SG_ 2147484461 TrlTire9_Stat 0;
BA_ "GenSigTimeoutTime_DTCM" SG_ 2147484461 TrlTire9_Stat 0;
BA_ "GenSigTimeoutTime_ECM" SG_ 2147484461 TrlTire9_Stat 0;
BA_ "GenSigTimeoutTime_EVCU2" SG_ 2147484461 TrlTire9_Stat 0;
BA_ "GenSigTimeoutTime_GNMM" SG_ 2147484461 TrlTire9_Stat 0;
BA_ "GenSigTimeoutTime_HCP" SG_ 2147484461 TrlTire9_Stat 0;
BA_ "GenSigTimeoutTime_IPC" SG_ 2147484461 TrlTire9_Stat 0;
BA_ "GenSigTimeoutTime_RFHM" SG_ 2147484461 TrlTire9_Stat 0;
BA_ "GenSigTimeoutTime_TCM" SG_ 2147484461 TrlTire9_Stat 0;
VAL_ 1440 AUD_LVL 255 "SNA";
VAL_ 1440 ETM_HUD_Zone1_Expanded 0 "Blank_Zone" 1 "Speedometer" 2 "Speed_Limit_Sign" 3 "Turn_By_Turn" 4 "Gear_Display" 5 "ACC_Cruise_Control" 6 "Phone" 7 "Battery_Voltage" 8 "Coolant_Temperature" 9 "Tire_Pressure" 10 "Trailer_Tire_Pressure" 11 "Longitude_and_Latitude" 12 "Altitude" 13 "Trailer_Odometer" 14 "Drive_Mode" 15 "Air_Suspension" 16 "Tow_Haul_Mode" 17 "Oil_Temperature" 18 "Trans_Oil_Temperature" 19 "Pitch" 20 "Roll" 21 "Steering_Angle" 22 "Timer_60ft" 23 "Timer_330ft" 24 "Eighth_Mile_Timer" 25 "Timer_1000ft" 26 "Quarter_Mile_Timer" 27 "Timer_60MPH" 28 "Timer_100MPH" 29 "Wheel_Articulation" 30 "GForce" 31 "Tachometer" 32 "Shift_Light" 33 "Oil_Pressure" 34 "Electronic_Range_Select" 63 "SNA";
VAL_ 1440 ETM_HUD_Zone2_Expanded 0 "Blank_Zone" 1 "Speedometer" 2 "Speed_Limit_Sign" 3 "Turn_By_Turn" 4 "Gear_Display" 5 "ACC_Cruise_Control" 6 "Phone" 7 "Battery_Voltage" 8 "Coolant_Temperature" 9 "Tire_Pressure" 10 "Trailer_Tire_Pressure" 11 "Longitude_and_Latitude" 12 "Altitude" 13 "Trailer_Odometer" 14 "Drive_Mode" 15 "Air_Suspension" 16 "Tow_Haul_Mode" 17 "Oil_Temperature" 18 "Trans_Oil_Temperature" 19 "Pitch" 20 "Roll" 21 "Steering_Angle" 22 "Timer_60ft" 23 "Timer_330ft" 24 "Eighth_Mile_Timer" 25 "Timer_1000ft" 26 "Quarter_Mile_Timer" 27 "Timer_60MPH" 28 "Timer_100MPH" 29 "Wheel_Articulation" 30 "GForce" 31 "Tachometer" 32 "Shift_Light" 33 "Oil_Pressure" 34 "Electronic_Range_Select" 63 "SNA";
VAL_ 1440 ETM_HUD_Zone3_Expanded 0 "Blank_Zone" 1 "Speedometer" 2 "Speed_Limit_Sign" 3 "Turn_By_Turn" 4 "Gear_Display" 5 "ACC_Cruise_Control" 6 "Phone" 7 "Battery_Voltage" 8 "Coolant_Temperature" 9 "Tire_Pressure" 10 "Trailer_Tire_Pressure" 11 "Longitude_and_Latitude" 12 "Altitude" 13 "Trailer_Odometer" 14 "Drive_Mode" 15 "Air_Suspension" 16 "Tow_Haul_Mode" 17 "Oil_Temperature" 18 "Trans_Oil_Temperature" 19 "Pitch" 20 "Roll" 21 "Steering_Angle" 22 "Timer_60ft" 23 "Timer_330ft" 24 "Eighth_Mile_Timer" 25 "Timer_1000ft" 26 "Quarter_Mile_Timer" 27 "Timer_60MPH" 28 "Timer_100MPH" 29 "Wheel_Articulation" 30 "GForce" 31 "Tachometer" 32 "Shift_Light" 33 "Oil_Pressure" 34 "Electronic_Range_Select" 63 "SNA";
VAL_ 1440 ETM_HUD_Zone4_Expanded 0 "Blank_Zone" 1 "Speedometer" 2 "Speed_Limit_Sign" 3 "Turn_By_Turn" 4 "Gear_Display" 5 "ACC_Cruise_Control" 6 "Phone" 7 "Battery_Voltage" 8 "Coolant_Temperature" 9 "Tire_Pressure" 10 "Trailer_Tire_Pressure" 11 "Longitude_and_Latitude" 12 "Altitude" 13 "Trailer_Odometer" 14 "Drive_Mode" 15 "Air_Suspension" 16 "Tow_Haul_Mode" 17 "Oil_Temperature" 18 "Trans_Oil_Temperature" 19 "Pitch" 20 "Roll" 21 "Steering_Angle" 22 "Timer_60ft" 23 "Timer_330ft" 24 "Eighth_Mile_Timer" 25 "Timer_1000ft" 26 "Quarter_Mile_Timer" 27 "Timer_60MPH" 28 "Timer_100MPH" 29 "Wheel_Articulation" 30 "GForce" 31 "Tachometer" 32 "Shift_Light" 33 "Oil_Pressure" 34 "Electronic_Range_Select" 63 "SNA";
VAL_ 1440 ETM_HUD_Zone5_Expanded 0 "Blank_Zone" 1 "Speedometer" 2 "Speed_Limit_Sign" 3 "Turn_By_Turn" 4 "Gear_Display" 5 "ACC_Cruise_Control" 6 "Phone" 7 "Battery_Voltage" 8 "Coolant_Temperature" 9 "Tire_Pressure" 10 "Trailer_Tire_Pressure" 11 "Longitude_and_Latitude" 12 "Altitude" 13 "Trailer_Odometer" 14 "Drive_Mode" 15 "Air_Suspension" 16 "Tow_Haul_Mode" 17 "Oil_Temperature" 18 "Trans_Oil_Temperature" 19 "Pitch" 20 "Roll" 21 "Steering_Angle" 22 "Timer_60ft" 23 "Timer_330ft" 24 "Eighth_Mile_Timer" 25 "Timer_1000ft" 26 "Quarter_Mile_Timer" 27 "Timer_60MPH" 28 "Timer_100MPH" 29 "Wheel_Articulation" 30 "GForce" 31 "Tachometer" 32 "Shift_Light" 33 "Oil_Pressure" 34 "Electronic_Range_Select" 63 "SNA";
VAL_ 1440 HU_Worksite_Inverter_RadioSwitch 0 "OFF" 1 "ON";
VAL_ 1465 ClusterAudiomode 0 "AM" 1 "FM" 2 "Apple_CarPlay" 3 "Android_Auto" 4 "CD" 5 "HDD" 6 "AUX" 7 "SD_Card" 8 "Baidu_Car_Life" 9 "SXM" 10 "Not_Used1" 11 "RSE_Listen_In_DVD" 12 "USB3" 13 "RSE1_AUX" 14 "RSE1_HDMI" 15 "RSE_USB" 16 "Alexa" 18 "DAB/DMB" 19 "USB1" 20 "VES_Rear_Source" 21 "RSE2_AUX" 22 "RSE_HDMI" 23 "Bluetooth" 24 "DTV" 25 "USB2" 26 "APPS" 27 "Audio_Muted" 28 "Not_Used2" 29 "Power_Off" 30 "Anti-Theft_Lock" 127 "SNA";
VAL_ 1465 ETM_HUD_Zone1 0 "Blank Zone" 1 "Speedometer" 2 "Speed Limit Sign" 3 "Turn By Turn" 4 "Gear Display" 5 "ACC/Cruise Control" 6 "Phone" 7 "SNA";
VAL_ 1465 ETM_HUD_Zone2 0 "Blank Zone" 1 "Speedometer" 2 "Speed Limit Sign" 3 "Turn By Turn" 4 "Gear Display" 5 "ACC/Cruise Control" 6 "Phone" 7 "SNA";
VAL_ 1465 ETM_HUD_Zone3 0 "Blank Zone" 1 "Speedometer" 2 "Speed Limit Sign" 3 "Turn By Turn" 4 "Gear Display" 5 "ACC/Cruise Control" 6 "Phone" 7 "SNA";
VAL_ 1465 ETM_HUD_Zone4 0 "Blank Zone" 1 "Speedometer" 2 "Speed Limit Sign" 3 "Turn By Turn" 4 "Gear Display" 5 "ACC/Cruise Control" 6 "Phone" 7 "SNA";
VAL_ 1465 ETM_HUD_Zone5 0 "Blank Zone" 1 "Speedometer" 2 "Speed Limit Sign" 3 "Turn By Turn" 4 "Gear Display" 5 "ACC/Cruise Control" 6 "Phone" 7 "SNA";
VAL_ 1465 PSI_Gr1_RPM_SET 31 "SNA";
VAL_ 1465 PSI_Gr2_RPM_SET 31 "SNA";
VAL_ 1465 PSI_Gr3_RPM_SET 31 "SNA";
VAL_ 1465 PSI_Gr4_RPM_SET 31 "SNA";
VAL_ 1465 PSI_Gr5_RPM_SET 31 "SNA";
VAL_ 1465 PSI_Rq 0 "NONE " 1 "DISABLE " 2 "ENABLE " 3 "SNA";
VAL_ 1465 Radio_Delete_Request 0 "No_Action" 1 "Delete_Profile_1" 2 "Delete_Profile_2" 3 "Delete_Profile_3" 4 "Delete_Profile_4" 5 "Delete_Profile_5" 6 "Delete_All" 7 "SNA";
VAL_ 1465 Radio_Profile_Request 0 "No_Action" 1 "Profile_1" 2 "Profile_2" 3 "Profile_3" 4 "Profile_4" 5 "Profile_5" 6 "Profile_6" 7 "SNA";
VAL_ 1465 TGW_CAMERA_DISP_STAT 0 "DISP_NON_CAMERA" 1 "DISP_DIGITAL_RVC_CAMERA" 2 "DISP_ANALOG_RVC_CAMERA" 3 "DISP_ANALOG_CHMSL_CAMERA" 4 "DISP_SURROUND_VIEW_CAMERA" 5 "DISP_TRAILER_CAMERA" 6 "DISP_WIRLESS_CAMERA" 7 "DISP_SVS_MORECAMS_POPUP" 8 "DISP_INTERIOR_CAMERA" 9 "DISP_TRAILER_SURROUND_CAMERA" 15 "SNA";
VAL_ 1466 Center_Cluster_Button_function 0 "Blank" 1 "Previous" 2 "Next" 3 "Pause/Play" 4 "Tune -" 5 "Tune +" 6 "Mute" 7 "Tag Song" 8 "Tag Artist" 9 "Unmute" 10 "Transfer Call to Device" 11 "Preset -" 12 "Preset +" 13 "Seek Up" 14 "Seek Down" 15 "Next Mode" 16 "Volume -" 17 "Volume +" 31 "SNA";
VAL_ 1466 ChargeNow 0 "No_Charge" 1 "Charge_Now";
VAL_ 1466 ETM_HUD_CustomSetting 0 "Default" 1 "ETM Settings Being Active work by User" 2 "ETM Settings Saved by Cutomer" 3 "ETM Settings Cancelled by User";
VAL_ 1466 ETM_HUD_Layout 0 "Default" 1 "Layout 1 Selected" 2 "Layout 2 Selected" 3 "Layout 3 Selected" 4 "Layout 4 Selected" 5 "Not Utilized " 6 "Not Utilized" 7 "SNA";
VAL_ 1466 GPS_Elevation 40000 "SNA";
VAL_ 1466 HUtoIPC_NAV_Sts 0 "Active" 1 "Not_Active" 2 "Map_Not_Available" 3 "Initialization" 4 "AppleCarPlay_projection_Active" 5 "AndroidAuto_projection_Active" 6 "BaiduCarLife_projection_Active" 7 "SNA";
VAL_ 1466 Left_Cluster_Button_function 0 "Blank" 1 "Previous" 2 "Next" 3 "Pause/Play" 4 "Tune -" 5 "Tune +" 6 "Mute" 7 "Tag Song" 8 "Tag Artist" 9 "Unmute" 10 "Transfer Call to Device" 11 "Preset -" 12 "Preset +" 13 "Seek Up" 14 "Seek Down" 15 "Next Mode" 16 "Volume -" 17 "Volume +" 31 "SNA";
VAL_ 1466 Right_Cluster_Button_function 0 "Blank" 1 "Previous" 2 "Next" 3 "Pause/Play" 4 "Tune -" 5 "Tune +" 6 "Mute" 7 "Tag Song" 8 "Tag Artist" 9 "Unmute" 10 "Transfer Call to Device" 11 "Preset -" 12 "Preset +" 13 "Seek Up" 14 "Seek Down" 15 "Next Mode" 16 "Volume -" 17 "Volume +" 31 "SNA";
VAL_ 150 FirstFrame_NavTbT 0 "Not_First_Frame" 1 "First_Frame";
VAL_ 150 Text_Type_NavTbT 0 "No_Text" 1 "Nav_Turn_By_Turn_Info" 2 "Current_Road" 4 "Lane_Guidance_Info" 15 "SNA";
VAL_ 154 Text_Type_Aud_Ph 0 "No_Text" 1 "First_Line_Audio_Info" 2 "Second_Line_Audio_Info" 3 "Third_Line_Audio_Info" 4 "Fourth_Line_Audio_Info" 7 "Incoming_Call" 8 "Call_Active_OR_Calling" 9 "Phone_Name" 10 "Contact_Name_OR_Phone_Number" 11 "Second_Phone_Incoming_Call" 12 "Wechat_incoming_call" 13 "Wechat_call_active" 14 "Wechat_calling" 255 "SNA";
VAL_ 145 PlugAndChargeReq 0 "Inactive" 1 "Active";
VAL_ 145 Secure_Idle_Req 0 "NOT_PRESSED" 1 "PRESSED";
VAL_ 145 SignatureLightingEnable_Req 0 "Disable" 1 "Enable";
VAL_ 1428 CM_TCH_STAT 0 "TCH_NOT_PSD" 1 "TCH_PSD" 2 "TCH_PS_CAN" 3 "Not_Used" 4 "TCH_CFG_RES" 5 "TCH_CFG_OFFSET" 6 "TCH_CFG_MAX" 7 "SNA";
VAL_ 1428 DIST_TO_TURN 65535 "SNA";
VAL_ 1428 ESC_Sft_btn_status 0 "ON" 1 "PARTIAL_1" 2 "PARTIAL_2" 3 "OFF" 4 "NOT_PRESSED" 5 "SNOW" 7 "SNA";
VAL_ 1428 HU_CMP 0 "CMP_N" 1 "CMP_N_E" 2 "CMP_E" 3 "CMP_S_E" 4 "CMP_S" 5 "CMP_S_W" 6 "CMP_W" 7 "CMP_N_W" 8 "NONE" 15 "SNA";
VAL_ 1428 NAV_ARROW 0 "NAV_NOT_ACT";
VAL_ 1428 NAV_UNITS 0 "NO_UNITS" 1 "MILE" 2 "FEET" 3 "KM" 4 "METER" 5 "YARD" 7 "SNA";
VAL_ 1428 NAVPrsnt 0 "Absent" 1 "Present";
VAL_ 1428 T_BY_T_ON 0 "Off" 1 "On";
VAL_ 1428 TURN_COMP 0 "turn_not_complete" 1 "complete";
VAL_ 1428 WorksiteINVM_Audible_LFW_Req 0 "OFF" 1 "ON";
VAL_ 1428 WorksiteINVM_Visual_LFW_Req 0 "OFF" 1 "ON";
VAL_ 956 Power_Tailgate_Enable_Req 0 "Disabled" 1 "Enabled";
VAL_ 956 Rear_Guidance_Light_Status_Req 0 "OFF" 1 "ON";
VAL_ 956 Rear_Lights_with_Approach_Req 0 "Off_with_Approach" 1 "On_with_Approach";
VAL_ 1832 GPS_Lat 4294967295 "SNA";
VAL_ 1832 GPS_Long 4294967295 "SNA";
VAL_ 158 Act_Lane_Mgt_Req 0 "Vib_Only" 1 "Steer_Asst_Only" 2 "Vib_Steer_Asst";
VAL_ 158 Act_Lane_Mgt_Strength_Req 0 "Low" 1 "Medium" 2 "High";
VAL_ 158 Active_Park_Mode_Req 0 "Full_Auto" 1 "Steering_Only";
VAL_ 158 Active_Park_Prox_Chime_Req 0 "Off" 1 "On";
VAL_ 158 Auto_Fold_Mirr_Req 0 "Off" 1 "On";
VAL_ 158 Auto_Trailer_Light_Check_Req 0 "Disable" 1 "Enable";
VAL_ 158 AutoHighBeamEnable_Req 0 "Not_Enable" 1 "Enable";
VAL_ 158 AutoParkBrake_Req 0 "On" 1 "Off";
VAL_ 158 AutoUnlockDoorExit_Req 0 "Not_Enable" 1 "Enable";
VAL_ 158 Backup_Cam_Delay_Req 0 "Off" 1 "On";
VAL_ 158 BSDEnable_Req 0 "Not_Enable" 1 "Enable_LED" 2 "Enable_ LED_Chime";
VAL_ 158 Consum_Unit_Req 0 "Km_Per_Litre" 1 "Litres_Per_100Km" 2 "Miles_Per_Gallon_UK" 3 "Miles_Per_Gallon_US" 4 "km/kWh" 5 "kWh/100km" 6 "mi/kWh" 7 "kWh/mi";
VAL_ 158 CorneringEnable_Req 0 "True" 1 "False";
VAL_ 158 Dist_Unit_Req 0 "km" 1 "miles";
VAL_ 158 DRLEnable_Req 0 "True" 1 "False";
VAL_ 158 Drowsy_Driver_Alert_Req 0 "Off" 1 "On";
VAL_ 158 DynamicGrid_Req 0 "Dynamic Gridlines OFF" 1 "Dynamic Gridlines ON";
VAL_ 158 Easy_Exit_D_Req 0 "Off" 1 "On";
VAL_ 158 Eng_Off_Pwr_Delay_Req 0 "Zero" 1 "Fourty_Five_Sec" 2 "Five_Min" 3 "Ten_Min";
VAL_ 158 EPB_MaintenanceMode_Req 0 "Off" 1 "On";
VAL_ 158 FlashLightWLock_Req 0 "Off" 1 "On";
VAL_ 158 FOA_Alert_Type_Req 0 "Off" 1 "Cluster_Warning" 2 "Cluster_SMS_Warning";
VAL_ 158 FSFCWPlusActivationMode_Req 0 "Near" 1 "Med" 2 "Far";
VAL_ 158 FSFCWPlusSetting_Req 0 "Off" 1 "Audio" 2 "Brake" 3 "Audio_Brake" 4 "Not_Request";
VAL_ 158 Fwrd_Cam_Guidelines_Req 0 "Off" 1 "On";
VAL_ 158 GreetingLightsEnable_Req 0 "True" 1 "False";
VAL_ 158 HeadlightsOffDelay_Req 0 "0sec" 1 "30sec" 2 "60sec" 3 "90sec";
VAL_ 158 HeadLightWipers_Req 0 "Off" 1 "On";
VAL_ 158 Hill_Start_Assist_Req 0 "Off" 1 "On";
VAL_ 158 HourMode_Req 0 "0_24_h" 1 "0_12_h";
VAL_ 158 HP_Unit_Req 0 "HP" 1 "kW" 2 "PS";
VAL_ 158 Illuminated_Approach_Req 0 "Zero" 1 "Thirty" 2 "Sixty" 3 "Ninety";
VAL_ 158 LanguageSelection_Req 0 "Italian" 1 "Deutsch" 2 "English" 3 "Espanol" 4 "Francais" 5 "Portugues" 6 "Polish" 7 "Dutch" 8 "Brazilian" 9 "Turkish" 10 "Mexican" 11 "English_US" 12 "Canadian" 13 "Russian" 14 "Chinese" 15 "Japanese" 16 "Korean" 17 "Arabic" 18 "Czech" 19 "Slovakian" 20 "Hungarian" 21 "Hindi";
VAL_ 158 LDW_Intensity_Req 0 "Low" 1 "Med" 2 "High";
VAL_ 158 LDW_Sensibility_Req 0 "Early" 1 "Med" 2 "Late";
VAL_ 158 NavigationRepetition_Req 0 "On" 1 "Off";
VAL_ 158 New_Spd_Zone_Ind_Req 0 "Off" 1 "Visual" 2 "Chime" 3 "Visual_Chime";
VAL_ 158 Paddle_Shifter_Req 0 "Off" 1 "On";
VAL_ 158 PamChimeVolumeFront_Req 0 "Low" 1 "Medium" 2 "High";
VAL_ 158 PamChimeVolumeRear_Req 0 "Low" 1 "Medium" 2 "High";
VAL_ 158 PassiveEntry_Req 0 "On" 1 "Off";
VAL_ 158 Ped_EM_Brk_Warn_Act_Req 0 "Off" 1 "On";
VAL_ 158 PhoneRepetition_Req 0 "On" 1 "Off";
VAL_ 158 PLGAlert_Req 0 "Off" 1 "On";
VAL_ 158 Power_Side_Step_Req 0 "Auto" 1 "Store";
VAL_ 158 Proximity_WU_Req 0 "Off" 1 "On";
VAL_ 158 PwrLevReq 0 "Level1" 1 "Level2" 2 "Level3" 3 "Level4" 4 "Level5";
VAL_ 158 RainSensorLevel_Req 0 "Not_Enable" 1 "Enable";
VAL_ 158 Rdy_To_Drive_Req 0 "Off" 1 "On";
VAL_ 158 Rear_Brk_Asst_Req 0 "Warn" 1 "Warn_Braking";
VAL_ 158 RemoteDoorUnlock_Req 0 "Driver" 1 "All";
VAL_ 158 RemStNrmlStEnbl_Req 0 "Off" 1 "Remote_Start_Only" 2 "Remote_And_Normal_Start " 3 "Normal_Start_Only";
VAL_ 158 RKEMemoryLinkEnable_Req 0 "Off" 1 "On";
VAL_ 158 SOC_Max_Lev_Req 0 "Level1" 1 "Level2";
VAL_ 158 SoundHornLock_Req 0 "Off" 1 "1st Press" 2 "2nd Press";
VAL_ 158 SoundHornRemoteStart_Req 0 "On" 1 "Off";
VAL_ 158 Speed_Unit_Req 0 "mph" 1 "kph";
VAL_ 158 SpeedLockDoorEnable_Req 0 "Not_Enable" 1 "Enable";
VAL_ 158 StaticGrid_Req 0 "Static Gridlines OFF" 1 "Static Gridlines ON";
VAL_ 158 Susp_Auto_Ent_Ext_Req 0 "Off" 1 "On";
VAL_ 158 Susp_Disp_Message_Req 0 "All" 1 "Warnings_Only";
VAL_ 158 Susp_Flsh_Lght_Low_Req 0 "Off" 1 "On";
VAL_ 158 Susp_Sound_Hrn_Low_Req 0 "Off" 1 "On";
VAL_ 158 Susp_Tire_Jack_Req 0 "Off" 1 "On";
VAL_ 158 SVC_Delay_Req 0 "Off" 1 "On";
VAL_ 158 SVC_Guidelines_Req 0 "Off" 1 "On";
VAL_ 158 Temp_Unit_Req 0 "°C" 1 "°F";
VAL_ 158 Tilt_Mirr_Rev_Req 0 "Off" 1 "On";
VAL_ 158 Tire_Fill_Alert_Req 0 "Off" 1 "On";
VAL_ 158 Torque_Unit_Req 0 "Nm" 1 "lb_ft";
VAL_ 158 Traffic_Sign_Info_Req 0 "Off" 1 "On";
VAL_ 158 Traffic_Sign_Warn_Req 0 "Off" 1 "Visual" 2 "Visual_Chime";
VAL_ 158 Trail_Brk_Type_Req 0 "Light_Electric" 1 "Heavy_Electric" 2 "Light_Electric_Over_Hydraulic" 3 "Heavy_Electric_Over_Hydraulic";
VAL_ 158 Trail_Name_Req 0 "Trailer" 1 "Boat" 2 "Car" 3 "Cargo" 4 "Dump" 5 "Equipment" 6 "Flatbed" 7 "Gooseneck" 8 "Horse" 9 "Livestock" 10 "Motorcycle" 11 "Snow_Mobile" 12 "Travel" 13 "Utility" 14 "Fifth_Wheel";
VAL_ 158 Trail_Num_Req 0 "One" 1 "Two" 2 "Three" 3 "Four";
VAL_ 158 Trailer_detection_blind_spot_Req 0 "Auto" 1 "Max";
VAL_ 158 Trailer_Light_Check_Request 0 "Not_Request" 1 "Request" 2 "In_Progress" 3 "Cancel";
VAL_ 158 TyrePress_Unit_Req 0 "KPa" 1 "psi" 2 "bar";
VAL_ 2147484460 TrailerTirePress1 255 "SNA";
VAL_ 2147484460 TrailerTirePress2 255 "SNA";
VAL_ 2147484460 TrailerTirePress3 255 "SNA";
VAL_ 2147484460 TrailerTirePress4 255 "SNA";
VAL_ 2147484460 TrailerTirePress5 255 "SNA";
VAL_ 2147484460 TrailerTirePress6 255 "SNA";
VAL_ 2147484460 TrlTire1_Stat 0 "NORMAL" 1 "LOW" 2 "HIGH" 3 "SNA";
VAL_ 2147484460 TrlTire2_Stat 0 "NORMAL" 1 "LOW" 2 "HIGH" 3 "SNA";
VAL_ 2147484460 TrlTire3_Stat 0 "NORMAL" 1 "LOW" 2 "HIGH" 3 "SNA";
VAL_ 2147484460 TrlTire4_Stat 0 "NORMAL" 1 "LOW" 2 "HIGH" 3 "SNA";
VAL_ 2147484460 TrlTire5_Stat 0 "NORMAL" 1 "LOW" 2 "HIGH" 3 "SNA";
VAL_ 2147484460 TrlTire6_Stat 0 "NORMAL" 1 "LOW" 2 "HIGH" 3 "SNA";
VAL_ 2147484461 TrailerTirePress10 255 "SNA";
VAL_ 2147484461 TrailerTirePress11 255 "SNA";
VAL_ 2147484461 TrailerTirePress12 255 "SNA";
VAL_ 2147484461 TrailerTirePress7 255 "SNA";
VAL_ 2147484461 TrailerTirePress8 255 "SNA";
VAL_ 2147484461 TrailerTirePress9 255 "SNA";
VAL_ 2147484461 TrlTire10_Stat 0 "NORMAL" 1 "LOW" 2 "HIGH" 3 "SNA";
VAL_ 2147484461 TrlTire11_Stat 0 "NORMAL" 1 "LOW" 2 "HIGH" 3 "SNA";
VAL_ 2147484461 TrlTire12_Stat 0 "NORMAL" 1 "LOW" 2 "HIGH" 3 "SNA";
VAL_ 2147484461 TrlTire7_Stat 0 "NORMAL" 1 "LOW" 2 "HIGH" 3 "SNA";
VAL_ 2147484461 TrlTire8_Stat 0 "NORMAL" 1 "LOW" 2 "HIGH" 3 "SNA";
VAL_ 2147484461 TrlTire9_Stat 0 "NORMAL" 1 "LOW" 2 "HIGH" 3 "SNA";
